VERSION ""

NS_ :

BS_:

BU_: CVC_I MHU TBOX FCAM_I MRR SRR_RL SRR_RR SRR_FL SRR_FR DUMMY_ECU ADCU_I AMP HUD

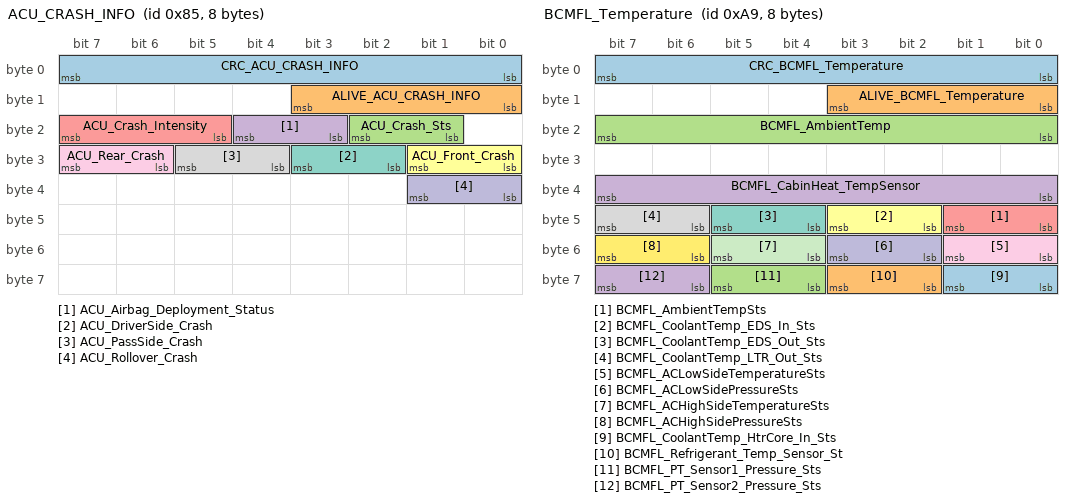
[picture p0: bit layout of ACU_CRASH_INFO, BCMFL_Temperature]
BO_ 133 ACU_CRASH_INFO: 8 CVC_I
 SG_ CRC_ACU_CRASH_INFO : 7|8@0+ (1,0) [0|255] ""  MHU,TBOX,FCAM_I,ADCU_I
 SG_ ALIVE_ACU_CRASH_INFO : 11|4@0+ (1,0) [0|15] ""  MHU,TBOX,FCAM_I,ADCU_I
 SG_ ACU_Crash_Sts : 18|2@0+ (1,0) [0|3] ""  MHU,TBOX,FCAM_I,ADCU_I
 SG_ ACU_Airbag_Deployment_Status : 20|2@0+ (1,0) [0|3] ""  MHU,TBOX,FCAM_I,ADCU_I
 SG_ ACU_Crash_Intensity : 23|3@0+ (1,0) [0|7] ""  MHU,TBOX,FCAM_I,ADCU_I
 SG_ ACU_Front_Crash : 25|2@0+ (1,0) [0|3] ""  MHU,TBOX,FCAM_I,ADCU_I
 SG_ ACU_DriverSide_Crash : 27|2@0+ (1,0) [0|3] ""  MHU,TBOX,FCAM_I,ADCU_I
 SG_ ACU_PassSide_Crash : 29|2@0+ (1,0) [0|3] ""  MHU,TBOX,FCAM_I,ADCU_I
 SG_ ACU_Rear_Crash : 31|2@0+ (1,0) [0|3] ""  MHU,TBOX,FCAM_I,ADCU_I
 SG_ ACU_Rollover_Crash : 33|2@0+ (1,0) [0|3] ""  MHU,TBOX,FCAM_I,ADCU_I

BO_ 169 BCMFL_Temperature: 8 CVC_I
 SG_ CRC_BCMFL_Temperature : 7|8@0+ (1,0) [0|255] ""  MHU,TBOX,FCAM_I,MRR,SRR_RL,SRR_RR,SRR_FL,SRR_FR,ADCU_I
 SG_ ALIVE_BCMFL_Temperature : 11|4@0+ (1,0) [0|15] ""  MHU,TBOX,FCAM_I,MRR,SRR_RL,SRR_RR,SRR_FL,SRR_FR,ADCU_I
 SG_ BCMFL_AmbientTemp : 23|8@0+ (0.5,-40) [-40|85] "Degree C"  MHU,TBOX,FCAM_I,MRR,SRR_RL,SRR_RR,SRR_FL,SRR_FR,ADCU_I
 SG_ BCMFL_CabinHeat_TempSensor : 39|8@0+ (0.5,-40) [-40|85] "Degree C"  MHU,TBOX,FCAM_I,MRR,SRR_RL,SRR_RR,SRR_FL,SRR_FR,ADCU_I
 SG_ BCMFL_AmbientTempSts : 41|2@0+ (1,0) [0|3] ""  MHU,TBOX,FCAM_I,MRR,SRR_RL,SRR_RR,SRR_FL,SRR_FR,ADCU_I
 SG_ BCMFL_CoolantTemp_EDS_In_Sts : 43|2@0+ (1,0) [0|3] ""  MHU,TBOX,FCAM_I,MRR,SRR_RL,SRR_RR,SRR_FL,SRR_FR,ADCU_I
 SG_ BCMFL_CoolantTemp_EDS_Out_Sts : 45|2@0+ (1,0) [0|3] ""  MHU,TBOX,FCAM_I,MRR,SRR_RL,SRR_RR,SRR_FL,SRR_FR,ADCU_I
 SG_ BCMFL_CoolantTemp_LTR_Out_Sts : 47|2@0+ (1,0) [0|3] ""  MHU,TBOX,FCAM_I,MRR,SRR_RL,SRR_RR,SRR_FL,SRR_FR,ADCU_I
 SG_ BCMFL_ACLowSideTemperatureSts : 49|2@0+ (1,0) [0|3] ""  MHU,TBOX,FCAM_I,MRR,SRR_RL,SRR_RR,SRR_FL,SRR_FR,ADCU_I
 SG_ BCMFL_ACLowSidePressureSts : 51|2@0+ (1,0) [0|3] ""  MHU,TBOX,FCAM_I,MRR,SRR_RL,SRR_RR,SRR_FL,SRR_FR,ADCU_I
 SG_ BCMFL_ACHighSideTemperatureSts : 53|2@0+ (1,0) [0|3] ""  MHU,TBOX,FCAM_I,MRR,SRR_RL,SRR_RR,SRR_FL,SRR_FR,ADCU_I
 SG_ BCMFL_ACHighSidePressureSts : 55|2@0+ (1,0) [0|3] ""  MHU,TBOX,FCAM_I,MRR,SRR_RL,SRR_RR,SRR_FL,SRR_FR,ADCU_I
 SG_ BCMFL_CoolantTemp_HtrCore_In_Sts : 57|2@0+ (1,0) [0|3] ""  MHU,TBOX,FCAM_I,MRR,SRR_RL,SRR_RR,SRR_FL,SRR_FR,ADCU_I
 SG_ BCMFL_Refrigerant_Temp_Sensor_St : 59|2@0+ (1,0) [0|3] ""  MHU,TBOX,FCAM_I,MRR,SRR_RL,SRR_RR,SRR_FL,SRR_FR,ADCU_I
 SG_ BCMFL_PT_Sensor1_Pressure_Sts : 61|2@0+ (1,0) [0|3] ""  MHU,TBOX,FCAM_I,MRR,SRR_RL,SRR_RR,SRR_FL,SRR_FR,ADCU_I
 SG_ BCMFL_PT_Sensor2_Pressure_Sts : 63|2@0+ (1,0) [0|3] ""  MHU,TBOX,FCAM_I,MRR,SRR_RL,SRR_RR,SRR_FL,SRR_FR,ADCU_I

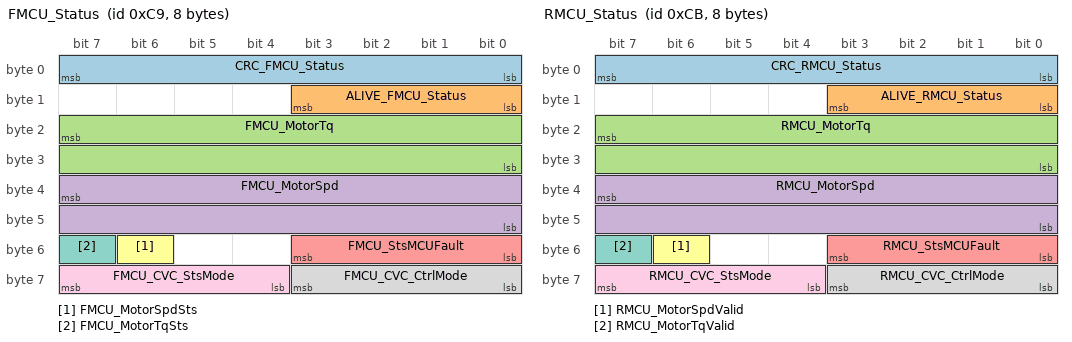
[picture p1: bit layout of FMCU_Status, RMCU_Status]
BO_ 201 FMCU_Status: 8 CVC_I
 SG_ CRC_FMCU_Status : 7|8@0+ (1,0) [0|255] ""  MHU,TBOX,FCAM_I,MRR,SRR_RL,SRR_RR,SRR_FL,SRR_FR,ADCU_I
 SG_ ALIVE_FMCU_Status : 11|4@0+ (1,0) [0|15] ""  MHU,TBOX,FCAM_I,MRR,SRR_RL,SRR_RR,SRR_FL,SRR_FR,ADCU_I
 SG_ FMCU_MotorTq : 23|16@0+ (0.1,-400) [-400|400] "Nm"  MHU,TBOX,FCAM_I,MRR,SRR_RL,SRR_RR,SRR_FL,SRR_FR,ADCU_I
 SG_ FMCU_MotorSpd : 39|16@0+ (1,-20000) [-20000|45531] "rpm"  MHU,TBOX,FCAM_I,MRR,SRR_RL,SRR_RR,SRR_FL,SRR_FR,ADCU_I
 SG_ FMCU_StsMCUFault : 51|4@0+ (1,0) [0|15] ""  MHU,TBOX,FCAM_I,MRR,SRR_RL,SRR_RR,SRR_FL,SRR_FR,ADCU_I
 SG_ FMCU_MotorSpdSts : 54|1@0+ (1,0) [0|1] ""  MHU,TBOX,FCAM_I,MRR,SRR_RL,SRR_RR,SRR_FL,SRR_FR,ADCU_I
 SG_ FMCU_MotorTqSts : 55|1@0+ (1,0) [0|1] ""  MHU,TBOX,FCAM_I,MRR,SRR_RL,SRR_RR,SRR_FL,SRR_FR,ADCU_I
 SG_ FMCU_CVC_CtrlMode : 59|4@0+ (1,0) [0|15] ""  MHU,TBOX,FCAM_I,MRR,SRR_RL,SRR_RR,SRR_FL,SRR_FR,ADCU_I
 SG_ FMCU_CVC_StsMode : 63|4@0+ (1,0) [0|15] ""  MHU,TBOX,FCAM_I,MRR,SRR_RL,SRR_RR,SRR_FL,SRR_FR,ADCU_I

BO_ 203 RMCU_Status: 8 CVC_I
 SG_ CRC_RMCU_Status : 7|8@0+ (1,0) [0|255] ""  MHU,TBOX,FCAM_I,MRR,SRR_RL,SRR_RR,SRR_FL,SRR_FR,ADCU_I
 SG_ ALIVE_RMCU_Status : 11|4@0+ (1,0) [0|15] ""  MHU,TBOX,FCAM_I,MRR,SRR_RL,SRR_RR,SRR_FL,SRR_FR,ADCU_I
 SG_ RMCU_MotorTq : 23|16@0+ (0.1,-400) [-400|400] "Nm"  MHU,TBOX,FCAM_I,MRR,SRR_RL,SRR_RR,SRR_FL,SRR_FR,ADCU_I
 SG_ RMCU_MotorSpd : 39|16@0+ (1,-20000) [-20000|45531] "rpm"  MHU,TBOX,FCAM_I,MRR,SRR_RL,SRR_RR,SRR_FL,SRR_FR,ADCU_I
 SG_ RMCU_StsMCUFault : 51|4@0+ (1,0) [0|15] ""  MHU,TBOX,FCAM_I,MRR,SRR_RL,SRR_RR,SRR_FL,SRR_FR,ADCU_I
 SG_ RMCU_MotorSpdValid : 54|1@0+ (1,0) [0|1] ""  MHU,TBOX,FCAM_I,MRR,SRR_RL,SRR_RR,SRR_FL,SRR_FR,ADCU_I
 SG_ RMCU_MotorTqValid : 55|1@0+ (1,0) [0|1] ""  MHU,TBOX,FCAM_I,MRR,SRR_RL,SRR_RR,SRR_FL,SRR_FR,ADCU_I
 SG_ RMCU_CVC_CtrlMode : 59|4@0+ (1,0) [0|15] ""  MHU,TBOX,FCAM_I,MRR,SRR_RL,SRR_RR,SRR_FL,SRR_FR,ADCU_I
 SG_ RMCU_CVC_StsMode : 63|4@0+ (1,0) [0|15] ""  MHU,TBOX,FCAM_I,MRR,SRR_RL,SRR_RR,SRR_FL,SRR_FR,ADCU_I

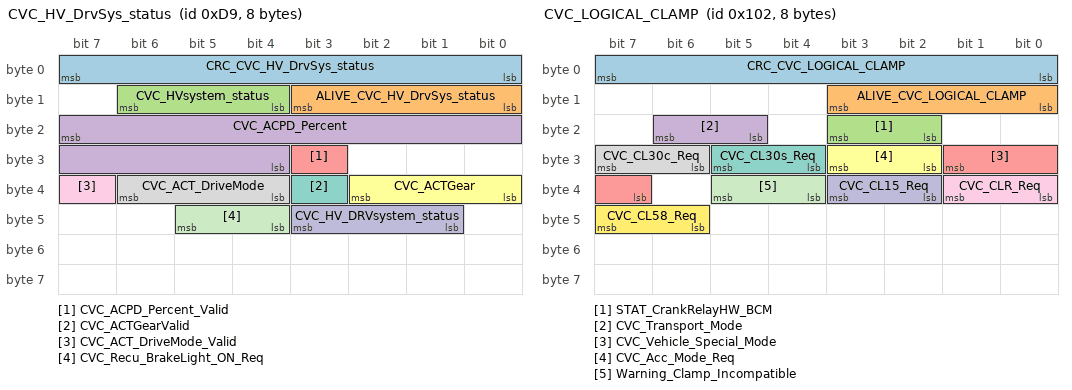
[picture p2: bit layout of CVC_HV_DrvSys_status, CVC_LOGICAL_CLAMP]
BO_ 217 CVC_HV_DrvSys_status: 8 CVC_I
 SG_ CRC_CVC_HV_DrvSys_status : 7|8@0+ (1,0) [0|255] ""  MHU,FCAM_I,SRR_RR
 SG_ ALIVE_CVC_HV_DrvSys_status : 11|4@0+ (1,0) [0|15] ""  MHU,FCAM_I,SRR_RR
 SG_ CVC_HVsystem_status : 14|3@0+ (1,0) [0|7] ""  MHU,FCAM_I,SRR_RR
 SG_ CVC_ACPD_Percent : 23|12@0+ (0.0625,0) [0|100] "%"  MHU,FCAM_I,SRR_RR
 SG_ CVC_ACPD_Percent_Valid : 27|1@0+ (1,0) [0|1] ""  MHU,FCAM_I,SRR_RR
 SG_ CVC_ACTGear : 34|3@0+ (1,0) [0|7] ""  MHU,FCAM_I,SRR_RR
 SG_ CVC_ACTGearValid : 35|1@0+ (1,0) [0|1] ""  MHU,FCAM_I,SRR_RR
 SG_ CVC_ACT_DriveMode : 38|3@0+ (1,0) [0|7] ""  MHU,FCAM_I,SRR_RR
 SG_ CVC_ACT_DriveMode_Valid : 39|1@0+ (1,0) [0|1] ""  MHU,FCAM_I,SRR_RR
 SG_ CVC_HV_DRVsystem_status : 43|3@0+ (1,0) [0|7] ""  MHU,FCAM_I,SRR_RR
 SG_ CVC_Recu_BrakeLight_ON_Req : 45|2@0+ (1,0) [0|3] ""  MHU,FCAM_I,SRR_RR

BO_ 258 CVC_LOGICAL_CLAMP: 8 CVC_I
 SG_ CRC_CVC_LOGICAL_CLAMP : 7|8@0+ (1,0) [0|255] ""  MHU,TBOX,FCAM_I,MRR,SRR_RL,SRR_RR,SRR_FL,SRR_FR,ADCU_I,AMP,HUD
 SG_ ALIVE_CVC_LOGICAL_CLAMP : 11|4@0+ (1,0) [0|15] ""  MHU,TBOX,FCAM_I,MRR,SRR_RL,SRR_RR,SRR_FL,SRR_FR,ADCU_I,AMP,HUD
 SG_ STAT_CrankRelayHW_BCM : 19|2@0+ (1,0) [0|3] ""  MHU
 SG_ CVC_Transport_Mode : 22|2@0+ (1,0) [0|3] ""  MHU,TBOX,FCAM_I,MRR,SRR_RL,SRR_RR,SRR_FL,SRR_FR,ADCU_I,AMP,HUD
 SG_ CVC_Vehicle_Special_Mode : 25|3@0+ (1,0) [0|7] ""  MHU
 SG_ CVC_Acc_Mode_Req : 27|2@0+ (1,0) [0|3] ""  MHU
 SG_ CVC_CL30s_Req : 29|2@0+ (1,0) [0|3] ""  MHU
 SG_ CVC_CL30c_Req : 31|2@0+ (1,0) [0|3] ""  MHU
 SG_ CVC_CLR_Req : 33|2@0+ (1,0) [0|3] ""  MHU
 SG_ CVC_CL15_Req : 35|2@0+ (1,0) [0|3] ""  MHU
 SG_ Warning_Clamp_Incompatible : 37|2@0+ (1,0) [0|3] ""  MHU
 SG_ CVC_CL58_Req : 47|2@0+ (1,0) [0|3] ""  MHU

BO_ 260 BCM_FL_Measured_Data: 12 CVC_I
 SG_ CRC_BCM_FL_Measured_Data : 7|8@0+ (1,0) [0|255] ""  MHU
 SG_ ALIVE_BCM_FL_Measured_Data : 11|4@0+ (1,0) [0|15] ""  MHU
 SG_ SOH_SUL : 23|8@0+ (1,0) [0|100] "%"  MHU
 SG_ SOH_SUL_STATE : 29|2@0+ (1,0) [0|3] ""  MHU
 SG_ SOC_STATE : 31|2@0+ (1,0) [0|3] ""  MHU
 SG_ Resp_Error : 35|1@0+ (1,0) [0|1] ""  MHU
 SG_ FLAG_INCONSTENCY : 36|1@0+ (1,0) [0|1] ""  MHU
 SG_ EBS_error : 37|1@0+ (1,0) [0|1] ""  MHU
 SG_ FLAG_DISCONNECT : 38|1@0+ (1,0) [0|1] ""  MHU
 SG_ IBATT_QUIESCENT : 47|8@0+ (0.00390625,0) [0|0.984375] ""  MHU
 SG_ LV_TargetCurrent : 55|10@0+ (0.25,-128) [-128|127] "A"  MHU
 SG_ LV_TargetVoltage : 61|6@0+ (0.112903,9) [9|16] "V"  MHU
 SG_ LV_ContinuousWakeUpCnt : 71|8@0+ (1,0) [0|255] ""  MHU

BO_ 262 CVC_Body_LIGHT: 8 CVC_I
 SG_ CRC_CVC_Body_LIGHT : 7|8@0+ (1,0) [0|255] ""  MHU,FCAM_I,SRR_RR,ADCU_I
 SG_ ALIVE_CVC_Body_LIGHT : 11|4@0+ (1,0) [0|15] ""  MHU,FCAM_I,SRR_RR,ADCU_I
 SG_ Body_DayRunningLampSts : 13|2@0+ (1,0) [0|3] ""  MHU,ADCU_I
 SG_ Body_ReverseLightSts : 15|2@0+ (1,0) [0|3] ""  MHU,ADCU_I
 SG_ Body_StopLightSts : 17|2@0+ (1,0) [0|3] ""  MHU,FCAM_I,SRR_RR,ADCU_I
 SG_ Body_LicensePlateLightSts : 19|2@0+ (1,0) [0|3] ""  MHU,ADCU_I
 SG_ Body_Fr_Dimming_dome_lampSts : 21|2@0+ (1,0) [0|3] ""  MHU,ADCU_I
 SG_ Body_Rr_Dimming_dome_lampSts : 23|2@0+ (1,0) [0|3] ""  MHU,ADCU_I
 SG_ Body_STAT_InteriorLight : 25|2@0+ (1,0) [0|3] ""  MHU,ADCU_I
 SG_ Body_STAT_LightActivation : 28|3@0+ (1,0) [0|7] ""  MHU,ADCU_I
 SG_ Body_HighBeamSts : 31|2@0+ (1,0) [0|3] ""  MHU,FCAM_I,SRR_RR,ADCU_I
 SG_ Body_STAT_SwitchLightBrightness : 39|7@0+ (1,0) [0|100] "%"  MHU,ADCU_I
 SG_ Body_LowBeamSts : 41|2@0+ (1,0) [0|3] ""  MHU,FCAM_I,SRR_RR,ADCU_I
 SG_ Body_RearFogLmpSts : 43|2@0+ (1,0) [0|3] ""  MHU,ADCU_I
 SG_ Body_FrntFogLmpSts : 45|2@0+ (1,0) [0|3] ""  MHU,ADCU_I
 SG_ Body_PosLmpSts : 47|2@0+ (1,0) [0|3] ""  MHU,ADCU_I
 SG_ Body_HornSts : 53|2@0+ (1,0) [0|3] ""  MHU,ADCU_I
 SG_ Body_TurnIndicatorSts : 55|2@0+ (1,0) [0|3] ""  MHU,FCAM_I,SRR_RR,ADCU_I

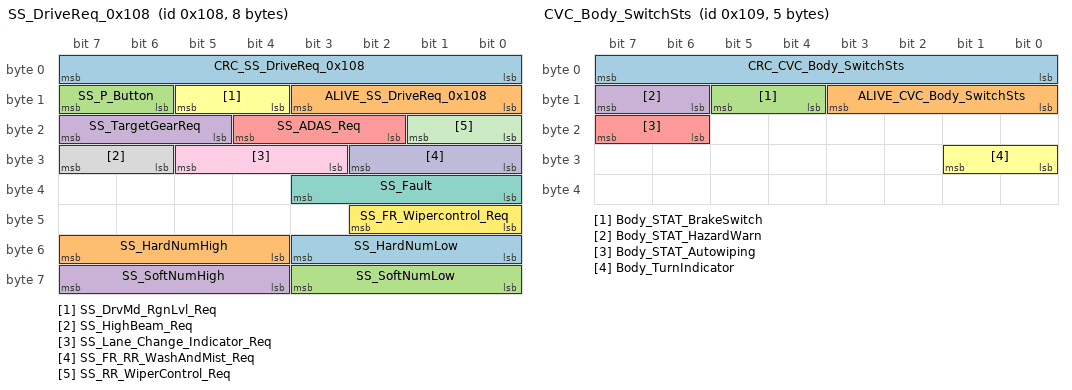
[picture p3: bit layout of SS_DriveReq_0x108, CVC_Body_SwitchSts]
BO_ 264 SS_DriveReq_0x108: 8 CVC_I
 SG_ CRC_SS_DriveReq_0x108 : 7|8@0+ (1,0) [0|255] ""  FCAM_I,ADCU_I
 SG_ ALIVE_SS_DriveReq_0x108 : 11|4@0+ (1,0) [0|15] ""  FCAM_I,ADCU_I
 SG_ SS_P_Button : 15|2@0+ (1,0) [0|3] ""  FCAM_I,ADCU_I
 SG_ SS_TargetGearReq : 23|3@0+ (1,0) [0|7] ""  FCAM_I,ADCU_I
 SG_ SS_ADAS_Req : 20|3@0+ (1,0) [0|7] ""  FCAM_I,ADCU_I
 SG_ SS_DrvMd_RgnLvl_Req : 13|2@0+ (1,0) [0|3] ""  FCAM_I,ADCU_I
 SG_ SS_Fault : 35|4@0+ (1,0) [0|15] ""  FCAM_I,ADCU_I
 SG_ SS_HighBeam_Req : 31|2@0+ (1,0) [0|3] ""  FCAM_I,ADCU_I
 SG_ SS_Lane_Change_Indicator_Req : 29|3@0+ (1,0) [0|7] ""  FCAM_I,ADCU_I
 SG_ SS_FR_RR_WashAndMist_Req : 26|3@0+ (1,0) [0|7] ""  FCAM_I,ADCU_I
 SG_ SS_RR_WiperControl_Req : 17|2@0+ (1,0) [0|3] ""  FCAM_I,ADCU_I
 SG_ SS_FR_Wipercontrol_Req : 42|3@0+ (1,0) [0|7] ""  FCAM_I,ADCU_I
 SG_ SS_HardNumLow : 51|4@0+ (1,0) [0|15] ""  FCAM_I,ADCU_I
 SG_ SS_HardNumHigh : 55|4@0+ (1,0) [0|15] ""  FCAM_I,ADCU_I
 SG_ SS_SoftNumLow : 59|4@0+ (1,0) [0|15] ""  FCAM_I,ADCU_I
 SG_ SS_SoftNumHigh : 63|4@0+ (1,0) [0|15] ""  FCAM_I,ADCU_I

BO_ 265 CVC_Body_SwitchSts: 5 CVC_I
 SG_ CRC_CVC_Body_SwitchSts : 7|8@0+ (1,0) [0|255] ""  MHU,FCAM_I,SRR_RR,ADCU_I
 SG_ ALIVE_CVC_Body_SwitchSts : 11|4@0+ (1,0) [0|15] ""  MHU,FCAM_I,SRR_RR,ADCU_I
 SG_ Body_STAT_BrakeSwitch : 13|2@0+ (1,0) [0|3] ""  MHU,FCAM_I,SRR_RR,ADCU_I
 SG_ Body_STAT_HazardWarn : 15|2@0+ (1,0) [0|3] ""  MHU,FCAM_I,SRR_RR,ADCU_I
 SG_ Body_STAT_Autowiping : 23|2@0+ (1,0) [0|3] ""  MHU,FCAM_I,SRR_RR,ADCU_I
 SG_ Body_TurnIndicator : 25|2@0+ (1,0) [0|3] ""  MHU,FCAM_I,SRR_RR,ADCU_I

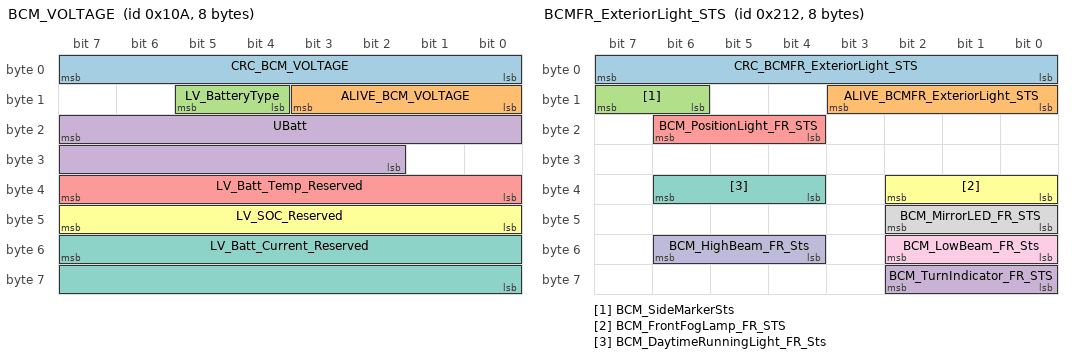
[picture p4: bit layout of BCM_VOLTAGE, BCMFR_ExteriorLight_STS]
BO_ 266 BCM_VOLTAGE: 8 CVC_I
 SG_ CRC_BCM_VOLTAGE : 7|8@0+ (1,0) [0|255] ""  MHU,TBOX,FCAM_I,MRR,SRR_RL,SRR_RR,ADCU_I
 SG_ ALIVE_BCM_VOLTAGE : 11|4@0+ (1,0) [0|15] ""  MHU,TBOX,FCAM_I,MRR,SRR_RL,SRR_RR,ADCU_I
 SG_ LV_BatteryType : 13|2@0+ (1,0) [0|3] ""  MHU,TBOX,FCAM_I,MRR,SRR_RL,SRR_RR,ADCU_I
 SG_ UBatt : 23|14@0+ (0.0009777,3) [3|18] "V"  MHU,TBOX,FCAM_I,MRR,SRR_RL,SRR_RR,ADCU_I
 SG_ LV_Batt_Temp_Reserved : 39|8@0+ (1,-40) [-40|105] "Degree C" Vector__XXX
 SG_ LV_SOC_Reserved : 47|8@0+ (1,0) [0|100] "%"  MHU,TBOX,FCAM_I,MRR,SRR_RL,SRR_RR,ADCU_I
 SG_ LV_Batt_Current_Reserved : 55|16@0+ (0.03125,-1536) [-1536|511.90625] "A"  MHU,TBOX,FCAM_I,MRR,SRR_RL,SRR_RR,ADCU_I

BO_ 180 BCM_WindowsFL_Status: 8 CVC_I
 SG_ CRC_BCM_WindowsFL_Status : 7|8@0+ (1,0) [0|255] ""  ADCU_I
 SG_ ALIVE_BCM_WindowsFL_Status : 11|4@0+ (1,0) [0|15] ""  ADCU_I
 SG_ BCMFL_WindowsFL_AntiPinch_Warn : 19|2@0+ (1,0) [0|3] ""  ADCU_I
 SG_ BCMFL_WindowFL_Learning_Sts : 23|2@0+ (1,0) [0|3] ""  ADCU_I
 SG_ BCMFL_WindowFL_Suppression_Warn : 25|2@0+ (1,0) [0|2] ""  ADCU_I
 SG_ BCMFL_WindowFL_LockActive : 26|1@0+ (1,0) [0|1] ""  ADCU_I
 SG_ BCMFL_WindowFL_ThermalProtect : 29|2@0+ (1,0) [0|2] ""  ADCU_I
 SG_ BCMFL_WindowFL_Error : 27|1@0+ (1,0) [0|1] ""  ADCU_I
 SG_ BCMFL_WindowsRL_AntiPinch_Warn : 33|2@0+ (1,0) [0|3] ""  ADCU_I
 SG_ BCMFL_WindowRL_LockActive : 35|1@0+ (1,0) [0|1] ""  ADCU_I
 SG_ BCMFL_WindowRL_Error : 34|1@0+ (1,0) [0|1] ""  ADCU_I
 SG_ BCMFL_WindowRL_Learning_Sts : 37|2@0+ (1,0) [0|3] ""  ADCU_I
 SG_ BCMFL_WindowRL_Suppression_Warn : 39|2@0+ (1,0) [0|2] ""  ADCU_I
 SG_ BCMFL_WindowRL_ThermalProtect : 41|2@0+ (1,0) [0|2] ""  ADCU_I
 SG_ Window_Position_FL : 51|4@0+ (1,0) [0|15] ""  ADCU_I
 SG_ Window_Position_RL : 55|4@0+ (1,0) [0|15] ""  ADCU_I
 SG_ BCMFL_WindowBtnPress_RL : 44|3@0+ (1,0) [0|4] ""  ADCU_I
 SG_ BCMFL_WindowBtnPress_FL : 47|3@0+ (1,0) [0|4] ""  ADCU_I
 SG_ BCMFL_WindowFL_Malfunction_Warn : 63|2@0+ (1,0) [0|3] ""  ADCU_I
 SG_ BCMFL_WindowRL_Malfunction_Warn : 61|2@0+ (1,0) [0|3] ""  ADCU_I

BO_ 530 BCMFR_ExteriorLight_STS: 8 CVC_I
 SG_ CRC_BCMFR_ExteriorLight_STS : 7|8@0+ (1,0) [0|255] ""  ADCU_I
 SG_ ALIVE_BCMFR_ExteriorLight_STS : 11|4@0+ (1,0) [0|15] ""  ADCU_I
 SG_ BCM_SideMarkerSts : 15|2@0+ (1,0) [0|3] ""  DUMMY_ECU
 SG_ BCM_TurnIndicator_FR_STS : 58|3@0+ (1,0) [0|4] ""  ADCU_I
 SG_ BCM_PositionLight_FR_STS : 22|3@0+ (1,0) [0|4] ""  ADCU_I
 SG_ BCM_FrontFogLamp_FR_STS : 34|3@0+ (1,0) [0|4] ""  DUMMY_ECU
 SG_ BCM_DaytimeRunningLight_FR_Sts : 38|3@0+ (1,0) [0|4] ""  DUMMY_ECU
 SG_ BCM_MirrorLED_FR_STS : 42|3@0+ (1,0) [0|4] ""  ADCU_I
 SG_ BCM_LowBeam_FR_Sts : 50|3@0+ (1,0) [0|4] ""  ADCU_I
 SG_ BCM_HighBeam_FR_Sts : 54|3@0+ (1,0) [0|4] ""  DUMMY_ECU

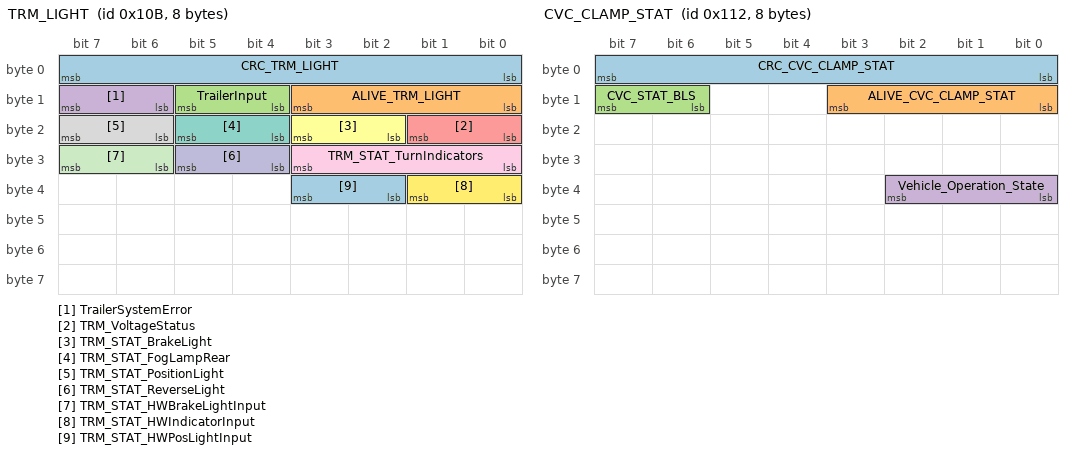
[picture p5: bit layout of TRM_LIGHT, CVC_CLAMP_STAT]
BO_ 267 TRM_LIGHT: 8 CVC_I
 SG_ CRC_TRM_LIGHT : 7|8@0+ (1,0) [0|255] ""  MHU
 SG_ ALIVE_TRM_LIGHT : 11|4@0+ (1,0) [0|15] ""  MHU
 SG_ TrailerInput : 13|2@0+ (1,0) [0|3] ""  MHU
 SG_ TrailerSystemError : 15|2@0+ (1,0) [0|3] ""  MHU
 SG_ TRM_VoltageStatus : 17|2@0+ (1,0) [0|3] ""  MHU
 SG_ TRM_STAT_BrakeLight : 19|2@0+ (1,0) [0|3] ""  MHU
 SG_ TRM_STAT_FogLampRear : 21|2@0+ (1,0) [0|3] ""  MHU
 SG_ TRM_STAT_PositionLight : 23|2@0+ (1,0) [0|3] ""  MHU
 SG_ TRM_STAT_TurnIndicators : 27|4@0+ (1,0) [0|15] ""  MHU
 SG_ TRM_STAT_ReverseLight : 29|2@0+ (1,0) [0|3] ""  MHU
 SG_ TRM_STAT_HWBrakeLightInput : 31|2@0+ (1,0) [0|3] ""  MHU
 SG_ TRM_STAT_HWIndicatorInput : 33|2@0+ (1,0) [0|3] ""  MHU
 SG_ TRM_STAT_HWPosLightInput : 35|2@0+ (1,0) [0|3] ""  MHU

BO_ 273 CVC_WCBS01: 12 CVC_I
 SG_ CRC_CVC_WCBS01 : 7|8@0+ (1,0) [0|255] ""  MHU
 SG_ ALIVE_CVC_WCBS01 : 11|4@0+ (1,0) [0|15] ""  MHU
 SG_ CVC_F_RegenTrqMaxValid : 12|1@0+ (1,0) [0|1] ""  MHU
 SG_ CVC_R_RegenTrqMaxValid : 13|1@0+ (1,0) [0|1] ""  MHU
 SG_ CVC_F_BrkRegenTrqActualValid : 14|1@0+ (1,0) [0|1] ""  MHU
 SG_ CVC_R_BrkRegenTrqActualValid : 15|1@0+ (1,0) [0|1] ""  MHU
 SG_ CVC_F_RegenTrqMax : 23|12@0+ (1,-4000) [-4000|0] "Nm"  MHU
 SG_ CVC_R_RegenTrqMax : 27|12@0+ (1,-4000) [-4000|0] "Nm"  MHU
 SG_ CVC_F_BrkRegenTrqActual : 47|12@0+ (1,-4000) [-4000|0] "Nm"  MHU
 SG_ CVC_R_BrkRegenTrqActual : 51|12@0+ (1,-4000) [-4000|0] "Nm"  MHU
 SG_ CVC_OnePedalModeSts : 69|2@0+ (1,0) [0|3] ""  MHU
 SG_ CVC_OnePedalModeEnable : 71|2@0+ (1,0) [0|3] ""  MHU
 SG_ CVC_TargetBrkTq : 67|12@0+ (1,0) [0|4000] "Nm"  MHU

BO_ 274 CVC_CLAMP_STAT: 8 CVC_I
 SG_ CRC_CVC_CLAMP_STAT : 7|8@0+ (1,0) [0|255] ""  MHU,TBOX,FCAM_I,MRR,SRR_RL,SRR_RR,SRR_FL,SRR_FR,ADCU_I,AMP,HUD
 SG_ ALIVE_CVC_CLAMP_STAT : 11|4@0+ (1,0) [0|15] ""  MHU,TBOX,FCAM_I,MRR,SRR_RL,SRR_RR,SRR_FL,SRR_FR,ADCU_I,AMP,HUD
 SG_ CVC_STAT_BLS : 15|2@0+ (1,0) [0|3] ""  MHU,TBOX,FCAM_I,MRR,SRR_RL,SRR_RR,SRR_FL,SRR_FR,ADCU_I,AMP,HUD
 SG_ Vehicle_Operation_State : 34|3@0+ (1,0) [0|7] ""  MHU,TBOX,FCAM_I,MRR,SRR_RL,SRR_RR,SRR_FL,SRR_FR,ADCU_I,AMP,HUD

BO_ 279 WCBS_Pressure: 16 CVC_I
 SG_ CRC_WCBS_Pressure : 7|8@0+ (1,0) [0|255] ""  SRR_RR,SRR_FR
 SG_ ALIVE_WCBS_Pressure : 11|4@0+ (1,0) [0|15] ""  SRR_RR,SRR_FR
 SG_ WCBS_CircuitPress : 58|15@0+ (0.01,0) [0|327.67] "bar"  SRR_RR,SRR_FR
 SG_ WCBS_CircuitPressValid : 109|1@0+ (1,0) [0|1] ""  SRR_RR,SRR_FR
 SG_ WCBS_EstWhlPress_FL : 23|15@0+ (0.01,0) [0|327.67] "bar"  SRR_RR,SRR_FR
 SG_ WCBS_EstWhlPress_FR : 92|15@0+ (0.01,0) [0|327.67] "bar"  SRR_RR,SRR_FR
 SG_ WCBS_EstWhlPress_RL : 75|15@0+ (0.01,0) [0|327.67] "bar"  SRR_RR,SRR_FR
 SG_ WCBS_EstWhlPress_RR : 24|15@0+ (0.01,0) [0|327.67] "bar"  SRR_RR,SRR_FR
 SG_ WCBS_EstWhlPressValid : 108|1@0+ (1,0) [0|1] ""  SRR_RR,SRR_FR
 SG_ WCBS_MainCylinderPress : 41|15@0+ (0.01,0) [0|250] "bar"  SRR_RR,SRR_FR
 SG_ WCBS_MainCylinderPressValid : 107|1@0+ (1,0) [0|1] ""  SRR_RR,SRR_FR

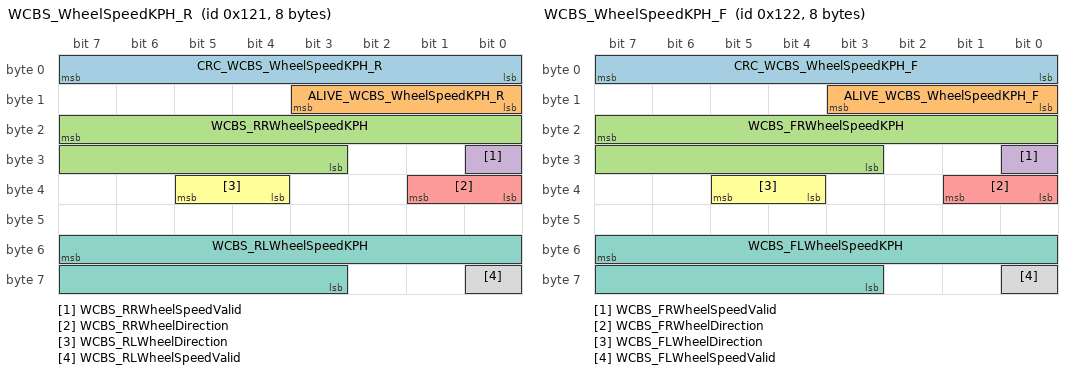
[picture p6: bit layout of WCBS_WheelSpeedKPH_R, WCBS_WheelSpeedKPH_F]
BO_ 289 WCBS_WheelSpeedKPH_R: 8 CVC_I
 SG_ CRC_WCBS_WheelSpeedKPH_R : 7|8@0+ (1,0) [0|255] ""  MHU,SRR_RR,SRR_FR
 SG_ ALIVE_WCBS_WheelSpeedKPH_R : 11|4@0+ (1,0) [0|15] ""  MHU,SRR_RR,SRR_FR
 SG_ WCBS_RRWheelSpeedKPH : 23|13@0+ (0.05625,0) [0|460.6875] "Km/h"  MHU,SRR_RR,SRR_FR
 SG_ WCBS_RRWheelSpeedValid : 24|1@0+ (1,0) [0|1] ""  MHU,SRR_RR,SRR_FR
 SG_ WCBS_RRWheelDirection : 33|2@0+ (1,0) [0|3] ""  MHU,SRR_RR,SRR_FR
 SG_ WCBS_RLWheelDirection : 37|2@0+ (1,0) [0|3] ""  MHU,SRR_RR,SRR_FR
 SG_ WCBS_RLWheelSpeedKPH : 55|13@0+ (0.05625,0) [0|460.6875] "Km/h"  MHU,SRR_RR,SRR_FR
 SG_ WCBS_RLWheelSpeedValid : 56|1@0+ (1,0) [0|1] ""  MHU,SRR_RR,SRR_FR

BO_ 290 WCBS_WheelSpeedKPH_F: 8 CVC_I
 SG_ CRC_WCBS_WheelSpeedKPH_F : 7|8@0+ (1,0) [0|255] ""  MHU,SRR_RR,SRR_FR
 SG_ ALIVE_WCBS_WheelSpeedKPH_F : 11|4@0+ (1,0) [0|15] ""  MHU,SRR_RR,SRR_FR
 SG_ WCBS_FRWheelSpeedKPH : 23|13@0+ (0.05625,0) [0|460.6875] "Km/h"  MHU,SRR_RR,SRR_FR
 SG_ WCBS_FRWheelSpeedValid : 24|1@0+ (1,0) [0|1] ""  MHU,SRR_RR,SRR_FR
 SG_ WCBS_FRWheelDirection : 33|2@0+ (1,0) [0|3] ""  MHU,SRR_RR,SRR_FR
 SG_ WCBS_FLWheelDirection : 37|2@0+ (1,0) [0|3] ""  MHU,SRR_RR,SRR_FR
 SG_ WCBS_FLWheelSpeedKPH : 55|13@0+ (0.05625,0) [0|460.6875] "Km/h"  MHU,SRR_RR,SRR_FR
 SG_ WCBS_FLWheelSpeedValid : 56|1@0+ (1,0) [0|1] ""  MHU,SRR_RR,SRR_FR

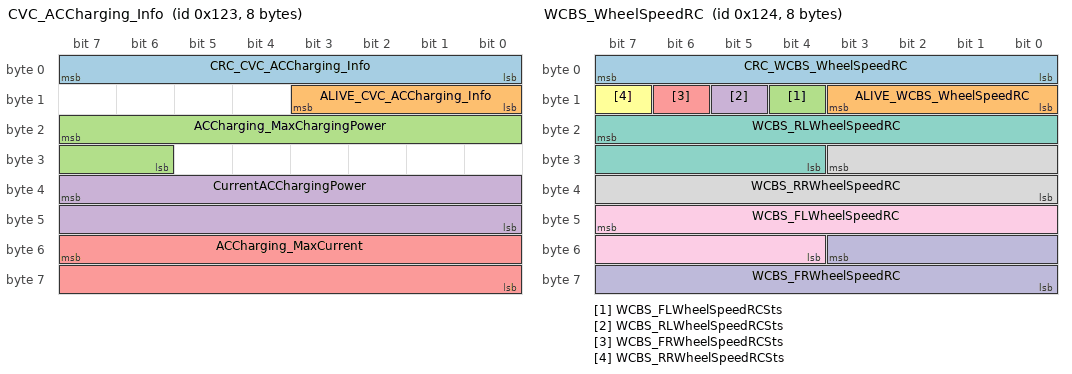
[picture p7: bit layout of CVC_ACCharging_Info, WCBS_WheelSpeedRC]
BO_ 291 CVC_ACCharging_Info: 8 CVC_I
 SG_ CRC_CVC_ACCharging_Info : 7|8@0+ (1,0) [0|255] ""  MHU
 SG_ ALIVE_CVC_ACCharging_Info : 11|4@0+ (1,0) [0|15] ""  MHU
 SG_ ACCharging_MaxChargingPower : 23|10@0+ (0.1,0) [0|102.2] "kW"  MHU
 SG_ CurrentACChargingPower : 39|16@0+ (0.1,0) [0|6553.5] "kW"  MHU
 SG_ ACCharging_MaxCurrent : 55|16@0+ (0.1,0) [0|3276.7] "A"  MHU

BO_ 292 WCBS_WheelSpeedRC: 8 CVC_I
 SG_ CRC_WCBS_WheelSpeedRC : 7|8@0+ (1,0) [0|255] ""  MHU,SRR_RR,SRR_FR
 SG_ ALIVE_WCBS_WheelSpeedRC : 11|4@0+ (1,0) [0|15] ""  MHU,SRR_RR,SRR_FR
 SG_ WCBS_FLWheelSpeedRCSts : 12|1@0+ (1,0) [0|1] ""  MHU,SRR_RR,SRR_FR
 SG_ WCBS_RLWheelSpeedRCSts : 13|1@0+ (1,0) [0|1] ""  MHU,SRR_RR,SRR_FR
 SG_ WCBS_FRWheelSpeedRCSts : 14|1@0+ (1,0) [0|1] ""  MHU,SRR_RR,SRR_FR
 SG_ WCBS_RRWheelSpeedRCSts : 15|1@0+ (1,0) [0|1] ""  MHU,SRR_RR,SRR_FR
 SG_ WCBS_RLWheelSpeedRC : 23|12@0+ (1,0) [0|4095] ""  MHU,SRR_RR,SRR_FR
 SG_ WCBS_RRWheelSpeedRC : 27|12@0+ (1,0) [0|4095] ""  MHU,SRR_RR,SRR_FR
 SG_ WCBS_FLWheelSpeedRC : 47|12@0+ (1,0) [0|4095] ""  MHU,SRR_RR,SRR_FR
 SG_ WCBS_FRWheelSpeedRC : 51|12@0+ (1,0) [0|4095] ""  MHU,SRR_RR,SRR_FR

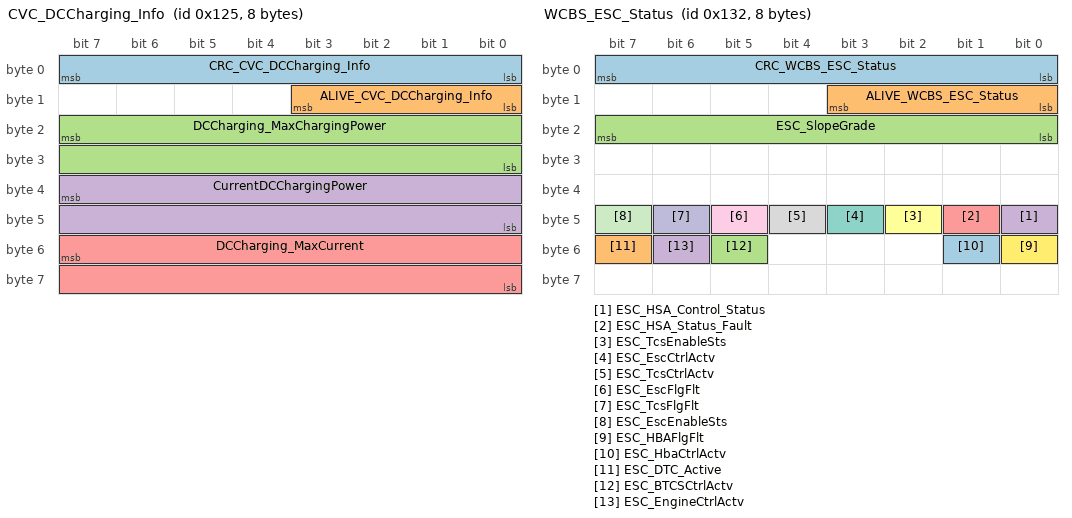
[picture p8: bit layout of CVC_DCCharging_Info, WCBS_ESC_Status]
BO_ 293 CVC_DCCharging_Info: 8 CVC_I
 SG_ CRC_CVC_DCCharging_Info : 7|8@0+ (1,0) [0|255] ""  MHU
 SG_ ALIVE_CVC_DCCharging_Info : 11|4@0+ (1,0) [0|15] ""  MHU
 SG_ DCCharging_MaxChargingPower : 23|16@0+ (0.1,0) [0|6553.5] "kW"  MHU
 SG_ CurrentDCChargingPower : 39|16@0+ (0.1,0) [0|6553.5] "kW"  MHU
 SG_ DCCharging_MaxCurrent : 55|16@0+ (0.1,0) [0|3276.7] "A"  MHU

BO_ 306 WCBS_ESC_Status: 8 CVC_I
 SG_ CRC_WCBS_ESC_Status : 7|8@0+ (1,0) [0|255] ""  MHU,SRR_RR
 SG_ ALIVE_WCBS_ESC_Status : 11|4@0+ (1,0) [0|15] ""  MHU,SRR_RR
 SG_ ESC_SlopeGrade : 23|8@0+ (1,-30) [-30|30] "%"  MHU,SRR_RR
 SG_ ESC_HSA_Control_Status : 40|1@0+ (1,0) [0|1] ""  MHU,SRR_RR
 SG_ ESC_HSA_Status_Fault : 41|1@0+ (1,0) [0|1] ""  MHU,SRR_RR
 SG_ ESC_TcsEnableSts : 42|1@0+ (1,0) [0|1] ""  MHU,SRR_RR
 SG_ ESC_EscCtrlActv : 43|1@0+ (1,0) [0|1] ""  MHU,SRR_RR
 SG_ ESC_TcsCtrlActv : 44|1@0+ (1,0) [0|1] ""  MHU,SRR_RR
 SG_ ESC_EscFlgFlt : 45|1@0+ (1,0) [0|1] ""  MHU,SRR_RR
 SG_ ESC_TcsFlgFlt : 46|1@0+ (1,0) [0|1] ""  MHU,SRR_RR
 SG_ ESC_EscEnableSts : 47|1@0+ (1,0) [0|1] ""  MHU,SRR_RR
 SG_ ESC_HBAFlgFlt : 48|1@0+ (1,0) [0|1] ""  MHU,SRR_RR
 SG_ ESC_HbaCtrlActv : 49|1@0+ (1,0) [0|1] ""  MHU,SRR_RR
 SG_ ESC_DTC_Active : 55|1@0+ (1,0) [0|1] ""  MHU,SRR_RR
 SG_ ESC_BTCSCtrlActv : 53|1@0+ (1,0) [0|1] ""  MHU,SRR_RR
 SG_ ESC_EngineCtrlActv : 54|1@0+ (1,0) [0|1] ""  MHU,SRR_RR

BO_ 311 EAS_CDC_WorkState: 8 CVC_I
 SG_ CRC_EAS_CDC_WorkState : 7|8@0+ (1,0) [0|255] ""  MHU
 SG_ ALIVE_EAS_CDC_WorkState : 11|4@0+ (1,0) [0|15] ""  MHU
 SG_ EAS_StiffStsFL : 12|1@0+ (1,0) [0|1] ""  MHU
 SG_ EAS_StiffStsFR : 13|1@0+ (1,0) [0|1] ""  MHU
 SG_ EAS_StiffStsRL : 14|1@0+ (1,0) [0|1] ""  MHU
 SG_ EAS_StiffStsRR : 15|1@0+ (1,0) [0|1] ""  MHU
 SG_ EAS_WorkSts : 17|2@0+ (1,0) [0|3] ""  MHU
 SG_ CDC_WorkSts : 19|2@0+ (1,0) [0|3] ""  MHU
 SG_ EAS_CDC_SystemWorkMode : 21|2@0+ (1,0) [0|3] ""  MHU
 SG_ EAS_SuspensionMode : 23|2@0+ (1,0) [0|3] ""  MHU
 SG_ EAS_EasyAccessSts : 25|2@0+ (1,0) [0|3] ""  MHU
 SG_ CDC_DamperMode : 27|2@0+ (1,0) [0|3] ""  MHU
 SG_ EAS_ValveValue_FL : 30|3@0+ (1,0) [0|7] ""  MHU
 SG_ EAS_ValveValue_FR : 34|3@0+ (1,0) [0|7] ""  MHU
 SG_ EAS_ValveValue_RL : 38|3@0+ (1,0) [0|7] ""  MHU
 SG_ EAS_ValveValue_RR : 42|3@0+ (1,0) [0|7] ""  MHU
 SG_ EAS_EnableSts : 31|1@0+ (1,0) [0|1] ""  MHU
 SG_ CDC_ValveValue_FL : 35|1@0+ (1,0) [0|1] ""  MHU
 SG_ CDC_ValveValue_FR : 39|1@0+ (1,0) [0|1] ""  MHU
 SG_ CDC_ValveValue_RL : 43|1@0+ (1,0) [0|1] ""  MHU
 SG_ CDC_ValveValue_RR : 44|1@0+ (1,0) [0|1] ""  MHU
 SG_ EAS_MntnSts : 45|1@0+ (1,0) [0|1] ""  MHU
 SG_ EAS_EasyLoadingSetFb : 47|2@0+ (1,0) [0|3] ""  MHU
 SG_ EAS_LiftModFb : 49|2@0+ (1,0) [0|3] ""  MHU
 SG_ EAS_VehicleUpDownState : 51|2@0+ (1,0) [0|3] ""  MHU
 SG_ EAS_Overheat_Warning : 52|1@0+ (1,0) [0|1] ""  MHU
 SG_ EAS_VehiclePositionState : 55|3@0+ (1,0) [0|7] ""  MHU
 SG_ EAS_VehicleTargetPositionState : 58|3@0+ (1,0) [0|7] ""  MHU

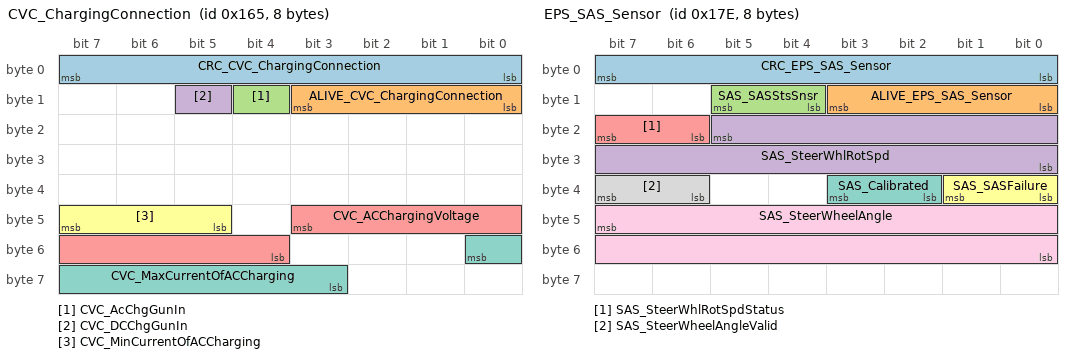
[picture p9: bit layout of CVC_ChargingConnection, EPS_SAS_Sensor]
BO_ 357 CVC_ChargingConnection: 8 CVC_I
 SG_ CRC_CVC_ChargingConnection : 7|8@0+ (1,0) [0|255] ""  MHU
 SG_ ALIVE_CVC_ChargingConnection : 11|4@0+ (1,0) [0|15] ""  MHU
 SG_ CVC_AcChgGunIn : 12|1@0+ (1,0) [0|1] ""  MHU
 SG_ CVC_DCChgGunIn : 13|1@0+ (1,0) [0|1] ""  MHU
 SG_ CVC_ACChargingVoltage : 43|8@0+ (1,0) [0|255] "V"  MHU
 SG_ CVC_MinCurrentOfACCharging : 47|3@0+ (1,0) [0|7] "A"  MHU
 SG_ CVC_MaxCurrentOfACCharging : 48|6@0+ (1,0) [0|63] "A"  MHU

BO_ 372 BMS_CurMeas: 24 CVC_I
 SG_ CRC_BMS_CurMeas : 7|8@0+ (1,0) [0|255] ""  MHU
 SG_ ALIVE_BMS_CurMeas : 11|4@0+ (1,0) [0|15] ""  MHU
 SG_ BMS_StartOfMeasument_STS : 15|1@0+ (1,0) [0|1] ""  MHU
 SG_ BMS_PackCur_MEAS : 23|16@0+ (0.1,-3276.8) [-3276.8|3276.7] "A"  MHU
 SG_ BMS_HVPackVol_MEAS : 39|16@0+ (0.1,0) [0|800] "V"  MHU
 SG_ BMS_HVLinkVol_MEAS : 55|16@0+ (0.1,0) [0|800] "V"  MHU
 SG_ BMS_HVBusVol_MEAS : 71|16@0+ (0.1,0) [0|800] "V"  MHU
 SG_ BMS_HVFuseVol_MEAS : 87|16@0+ (0.1,0) [0|800] "V"  MHU
 SG_ BMS_MainNegRelay_Volt : 103|8@0+ (0.1,0) [0|5] "V"  MHU
 SG_ BMS_CellNumMinCellVol : 111|8@0+ (1,0) [0|255] ""  MHU
 SG_ BMS_CellNumMaxCellVol : 119|8@0+ (1,0) [0|255] ""  MHU
 SG_ BMS_MinCellVol : 127|13@0+ (0.001,0) [0|6] "V"  MHU
 SG_ BMS_MaxCellVol : 143|13@0+ (0.001,0) [0|6] "V"  MHU
 SG_ BMS_MaxMinDiffCellVol : 159|13@0+ (0.001,0) [0|2] "V"  MHU
 SG_ BMS_CVC_Insulation_Mon_Sts : 162|1@0+ (1,0) [0|1] ""  MHU
 SG_ BMS_PackInsuRes : 175|16@0+ (1,0) [0|60000] "kOhm"  MHU

BO_ 382 EPS_SAS_Sensor: 8 CVC_I
 SG_ CRC_EPS_SAS_Sensor : 7|8@0+ (1,0) [0|255] ""  MHU,SRR_RR
 SG_ ALIVE_EPS_SAS_Sensor : 11|4@0+ (1,0) [0|15] ""  MHU,SRR_RR
 SG_ SAS_SASStsSnsr : 13|2@0+ (1,0) [0|1] ""  MHU,SRR_RR
 SG_ SAS_SteerWhlRotSpd : 21|14@0+ (0.125,-1024) [-1024|1023.88] "degree/s"  MHU,SRR_RR
 SG_ SAS_SteerWhlRotSpdStatus : 23|2@0+ (1,0) [0|1] ""  MHU,SRR_RR
 SG_ SAS_SASFailure : 33|2@0+ (1,0) [0|1] ""  MHU,SRR_RR
 SG_ SAS_Calibrated : 35|2@0+ (1,0) [0|1] ""  MHU,SRR_RR
 SG_ SAS_SteerWheelAngleValid : 39|2@0+ (1,0) [0|1] ""  MHU,SRR_RR
 SG_ SAS_SteerWheelAngle : 47|16@0+ (0.0238,-780) [-780|779.7] "deg"  MHU,SRR_RR

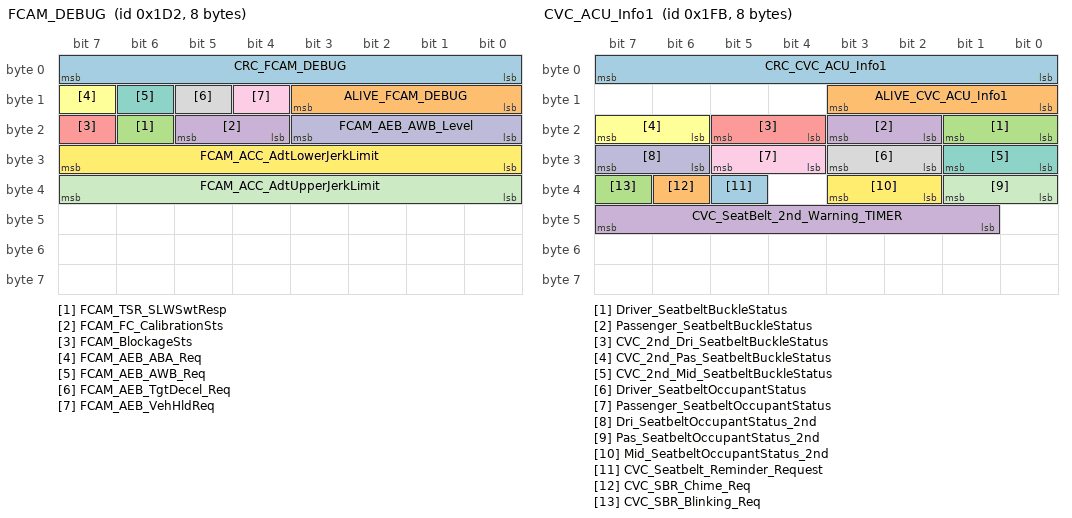
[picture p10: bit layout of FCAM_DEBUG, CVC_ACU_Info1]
BO_ 466 FCAM_DEBUG: 8 CVC_I
 SG_ CRC_FCAM_DEBUG : 7|8@0+ (1,0) [0|255] ""  MHU
 SG_ ALIVE_FCAM_DEBUG : 11|4@0+ (1,0) [0|15] ""  MHU
 SG_ FCAM_TSR_SLWSwtResp : 22|1@0+ (1,0) [0|1] ""  MHU
 SG_ FCAM_FC_CalibrationSts : 21|2@0+ (1,0) [0|3] ""  MHU
 SG_ FCAM_BlockageSts : 23|1@0+ (1,0) [0|1] ""  MHU
 SG_ FCAM_AEB_ABA_Req : 15|1@0+ (1,0) [0|1] ""  MHU
 SG_ FCAM_AEB_AWB_Req : 14|1@0+ (1,0) [0|1] ""  MHU
 SG_ FCAM_AEB_TgtDecel_Req : 13|1@0+ (1,0) [0|1] ""  MHU
 SG_ FCAM_AEB_VehHldReq : 12|1@0+ (1,0) [0|1] ""  MHU
 SG_ FCAM_AEB_AWB_Level : 19|4@0+ (1,0) [0|15] ""  MHU
 SG_ FCAM_ACC_AdtUpperJerkLimit : 39|8@0+ (0.1,-12.7) [-12.7|12.7] "m/s3"  MHU
 SG_ FCAM_ACC_AdtLowerJerkLimit : 31|8@0+ (0.1,-12.7) [-12.7|12.7] "m/s3"  MHU

BO_ 507 CVC_ACU_Info1: 8 CVC_I
 SG_ CRC_CVC_ACU_Info1 : 7|8@0+ (1,0) [0|255] ""  MHU
 SG_ ALIVE_CVC_ACU_Info1 : 11|4@0+ (1,0) [0|15] ""  MHU
 SG_ Driver_SeatbeltBuckleStatus : 17|2@0+ (1,0) [0|3] ""  MHU
 SG_ Passenger_SeatbeltBuckleStatus : 19|2@0+ (1,0) [0|3] ""  MHU
 SG_ CVC_2nd_Dri_SeatbeltBuckleStatus : 21|2@0+ (1,0) [0|3] ""  MHU
 SG_ CVC_2nd_Pas_SeatbeltBuckleStatus : 23|2@0+ (1,0) [0|3] ""  MHU
 SG_ CVC_2nd_Mid_SeatbeltBuckleStatus : 25|2@0+ (1,0) [0|3] ""  MHU
 SG_ Driver_SeatbeltOccupantStatus : 27|2@0+ (1,0) [0|3] ""  MHU
 SG_ Passenger_SeatbeltOccupantStatus : 29|2@0+ (1,0) [0|3] ""  MHU
 SG_ Dri_SeatbeltOccupantStatus_2nd : 31|2@0+ (1,0) [0|3] ""  MHU
 SG_ Pas_SeatbeltOccupantStatus_2nd : 33|2@0+ (1,0) [0|3] ""  MHU
 SG_ Mid_SeatbeltOccupantStatus_2nd : 35|2@0+ (1,0) [0|3] ""  MHU
 SG_ CVC_Seatbelt_Reminder_Request : 37|1@0+ (1,0) [0|1] ""  MHU
 SG_ CVC_SBR_Chime_Req : 38|1@0+ (1,0) [0|1] ""  MHU
 SG_ CVC_SBR_Blinking_Req : 39|1@0+ (1,0) [0|1] ""  MHU
 SG_ CVC_SeatBelt_2nd_Warning_TIMER : 47|7@0+ (1,0) [0|127] ""  MHU

BO_ 522 ETG_STATUS: 8 CVC_I
 SG_ ETG_Lift_Gate_Status : 43|4@0+ (1,0) [0|15] ""  MHU
 SG_ ETG_Power_Latch_Status : 5|3@0+ (1,0) [0|7] ""  MHU
 SG_ ETG_Latch_Segment : 7|2@0+ (1,0) [0|3] ""  MHU
 SG_ ETG_Opening_Percentage : 15|8@0+ (1,0) [0|100] "%"  MHU
 SG_ ETG_DSW_Status : 16|1@0+ (1,0) [0|1] ""  MHU
 SG_ ETG_GSW_Status : 17|1@0+ (1,0) [0|1] ""  MHU
 SG_ ETG_LTS_Status : 18|1@0+ (1,0) [0|1] ""  MHU
 SG_ ETG_RTS_Status : 19|1@0+ (1,0) [0|1] ""  MHU
 SG_ ETG_HAL_Status : 20|1@0+ (1,0) [0|1] ""  MHU
 SG_ ETG_FUL_Status : 21|1@0+ (1,0) [0|1] ""  MHU
 SG_ ETG_AJR_Status : 22|1@0+ (1,0) [0|1] ""  MHU
 SG_ ETG_NTL_Status : 23|1@0+ (1,0) [0|1] ""  MHU
 SG_ ETG_ERR_Voltage : 25|2@0+ (1,0) [0|3] ""  MHU
 SG_ ETG_ERR_Left_Motor : 27|2@0+ (1,0) [0|3] ""  MHU
 SG_ ETG_ERR_Right_Motor : 29|2@0+ (1,0) [0|3] ""  MHU
 SG_ ETG_ERR_Latch : 31|2@0+ (1,0) [0|3] ""  MHU
 SG_ ETG_ERR_Hall : 33|2@0+ (1,0) [0|3] ""  MHU
 SG_ ETG_Lift_Motor_Stall : 34|1@0+ (1,0) [0|1] ""  MHU
 SG_ ETG_Lift_Motor_AntiPinch : 35|1@0+ (1,0) [0|1] ""  MHU
 SG_ ETG_Lift_Motor_Thermal : 36|1@0+ (1,0) [0|1] ""  MHU
 SG_ ETG_Power_Latch_Thermal : 37|1@0+ (1,0) [0|1] ""  MHU
 SG_ ETG_Abuse_Protection : 38|1@0+ (1,0) [0|1] ""  MHU

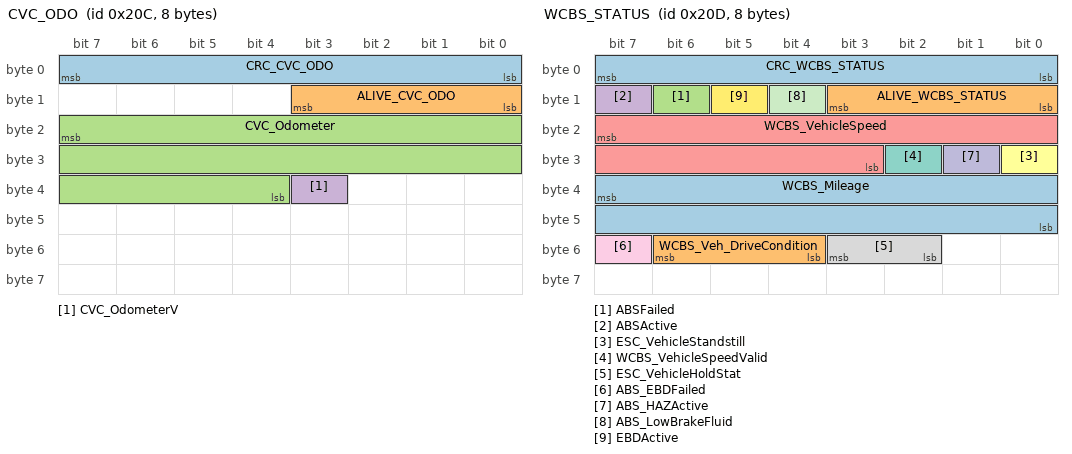
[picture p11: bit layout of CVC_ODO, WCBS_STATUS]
BO_ 524 CVC_ODO: 8 CVC_I
 SG_ CRC_CVC_ODO : 7|8@0+ (1,0) [0|255] ""  MHU,TBOX,FCAM_I,MRR,SRR_RL,SRR_RR,ADCU_I
 SG_ ALIVE_CVC_ODO : 11|4@0+ (1,0) [0|15] ""  MHU,TBOX,FCAM_I,MRR,SRR_RL,SRR_RR,ADCU_I
 SG_ CVC_Odometer : 23|20@0+ (1,0) [0|999999] "km"  MHU,TBOX,FCAM_I,MRR,SRR_RL,SRR_RR,ADCU_I
 SG_ CVC_OdometerV : 35|1@0+ (1,0) [0|1] ""  MHU,TBOX,FCAM_I,MRR,SRR_RL,SRR_RR,ADCU_I

BO_ 525 WCBS_STATUS: 8 CVC_I
 SG_ CRC_WCBS_STATUS : 7|8@0+ (1,0) [0|255] ""  MHU,TBOX,FCAM_I,MRR,SRR_RL,SRR_RR,SRR_FL,SRR_FR
 SG_ ALIVE_WCBS_STATUS : 11|4@0+ (1,0) [0|15] ""  MHU,TBOX,FCAM_I,MRR,SRR_RL,SRR_RR,SRR_FL,SRR_FR
 SG_ ABSFailed : 14|1@0+ (1,0) [0|1] ""  MHU,TBOX,FCAM_I,MRR,SRR_RL,SRR_RR,SRR_FL,SRR_FR
 SG_ ABSActive : 15|1@0+ (1,0) [0|1] ""  MHU,TBOX,FCAM_I,MRR,SRR_RL,SRR_RR,SRR_FL,SRR_FR
 SG_ WCBS_VehicleSpeed : 23|13@0+ (0.05625,0) [0|300] "km/h"  MHU,TBOX,FCAM_I,MRR,SRR_RL,SRR_RR,SRR_FL,SRR_FR
 SG_ ESC_VehicleStandstill : 24|1@0+ (1,0) [0|1] ""  MHU,TBOX,FCAM_I,MRR,SRR_RL,SRR_RR,SRR_FL,SRR_FR
 SG_ WCBS_VehicleSpeedValid : 26|1@0+ (1,0) [0|1] ""  MHU,TBOX,FCAM_I,MRR,SRR_RL,SRR_RR,SRR_FL,SRR_FR
 SG_ ESC_VehicleHoldStat : 51|2@0+ (1,0) [0|3] ""  MHU,TBOX,FCAM_I,MRR,SRR_RL,SRR_RR,SRR_FL,SRR_FR
 SG_ ABS_EBDFailed : 55|1@0+ (1,0) [0|1] ""  MHU,TBOX,FCAM_I,MRR,SRR_RL,SRR_RR,SRR_FL,SRR_FR
 SG_ ABS_HAZActive : 25|1@0+ (1,0) [0|1] ""  MHU,TBOX,FCAM_I,MRR,SRR_RL,SRR_RR,SRR_FL,SRR_FR
 SG_ ABS_LowBrakeFluid : 12|1@0+ (1,0) [0|1] ""  MHU,TBOX,FCAM_I,MRR,SRR_RL,SRR_RR,SRR_FL,SRR_FR
 SG_ EBDActive : 13|1@0+ (1,0) [0|1] ""  MHU,TBOX,FCAM_I,MRR,SRR_RL,SRR_RR,SRR_FL,SRR_FR
 SG_ WCBS_Mileage : 39|16@0+ (1,0) [0|65535] "cm"  MHU,TBOX,FCAM_I,MRR,SRR_RL,SRR_RR,SRR_FL,SRR_FR
 SG_ WCBS_Veh_DriveCondition : 54|3@0+ (1,0) [0|7] ""  MHU,TBOX,FCAM_I,MRR,SRR_RL,SRR_RR,SRR_FL,SRR_FR

BO_ 533 BMS_Sts: 16 CVC_I
 SG_ CRC_BMS_Sts : 7|8@0+ (1,0) [0|255] ""  MHU,FCAM_I,ADCU_I
 SG_ ALIVE_BMS_Sts : 11|4@0+ (1,0) [0|15] ""  MHU,FCAM_I,ADCU_I
 SG_ BMS_BatBalance_ERR : 12|1@0+ (1,0) [0|1] ""  MHU,FCAM_I,ADCU_I
 SG_ BMS_Balance_STS : 13|1@0+ (1,0) [0|1] ""  MHU,FCAM_I,ADCU_I
 SG_ BMS_IGN_Sts : 14|1@0+ (1,0) [0|1] ""  MHU,FCAM_I,ADCU_I
 SG_ BMS_HWCrash_Sts : 15|1@0+ (1,0) [0|1] ""  MHU,FCAM_I,ADCU_I
 SG_ BMS_HVIL_STS : 17|2@0+ (1,0) [0|3] ""  MHU,FCAM_I,ADCU_I
 SG_ BMS_HVOnOff_STS : 19|2@0+ (1,0) [0|3] ""  MHU,FCAM_I,ADCU_I
 SG_ BMS_ERR_LEV : 23|4@0+ (1,0) [0|7] ""  MHU,FCAM_I,ADCU_I
 SG_ BMS_SocActual_EST : 25|10@0+ (0.1,0) [0|100] "%"  MHU,FCAM_I,ADCU_I
 SG_ BMS_Sys_STS : 29|4@0+ (1,0) [0|15] ""  MHU,FCAM_I,ADCU_I
 SG_ BMS_ISU_Status : 31|2@0+ (1,0) [0|3] ""  MHU,FCAM_I,ADCU_I
 SG_ BMS_SOH : 47|8@0+ (0.5,0) [0|100] "%"  MHU,FCAM_I,ADCU_I
 SG_ BMS_SOE : 55|8@0+ (0.5,0) [0|100] "%"  MHU,FCAM_I,ADCU_I
 SG_ BMS_HV_Sts : 63|8@0+ (1,0) [0|255] ""  MHU,FCAM_I,ADCU_I
 SG_ BMS_Display_SOC : 71|10@0+ (0.1,0) [0|100] "%"  MHU,FCAM_I,ADCU_I
 SG_ BMS_SOCE : 87|14@0+ (0.01,0) [0|100] "%"  MHU,FCAM_I,ADCU_I

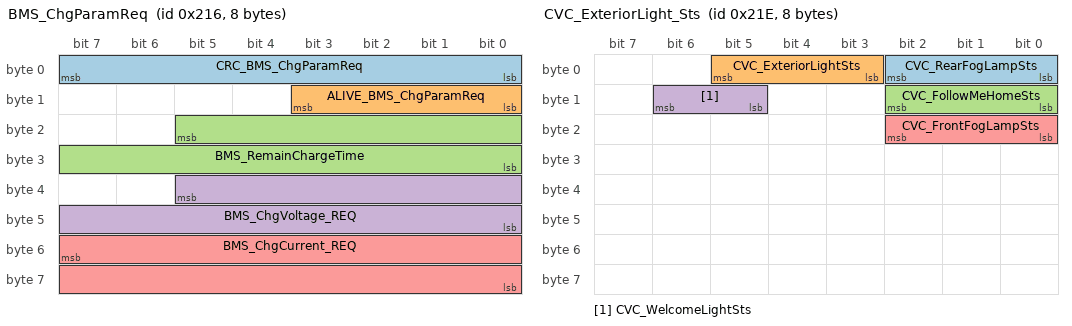
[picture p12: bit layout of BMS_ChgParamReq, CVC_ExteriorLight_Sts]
BO_ 534 BMS_ChgParamReq: 8 CVC_I
 SG_ CRC_BMS_ChgParamReq : 7|8@0+ (1,0) [0|255] ""  MHU
 SG_ ALIVE_BMS_ChgParamReq : 11|4@0+ (1,0) [0|15] ""  MHU
 SG_ BMS_RemainChargeTime : 21|14@0+ (1,0) [0|16383] "min"  MHU
 SG_ BMS_ChgVoltage_REQ : 37|14@0+ (0.1,0) [0|800] "V"  MHU
 SG_ BMS_ChgCurrent_REQ : 55|16@0+ (0.1,0) [0|1500] "A"  MHU

BO_ 542 CVC_ExteriorLight_Sts: 8 CVC_I
 SG_ CVC_RearFogLampSts : 2|3@0+ (1,0) [0|4] ""  MHU,FCAM_I
 SG_ CVC_ExteriorLightSts : 5|3@0+ (1,0) [0|4] ""  MHU,FCAM_I
 SG_ CVC_FollowMeHomeSts : 10|3@0+ (1,0) [0|5] ""  MHU,FCAM_I
 SG_ CVC_WelcomeLightSts : 14|2@0+ (1,0) [0|3] ""  MHU,FCAM_I
 SG_ CVC_FrontFogLampSts : 18|3@0+ (1,0) [0|4] ""  MHU,FCAM_I,ADCU_I

BO_ 560 WCBS_VAFS: 12 CVC_I
 SG_ CRC_WCBS_VAFS : 7|8@0+ (1,0) [0|255] ""  MHU,SRR_RR
 SG_ ALIVE_WCBS_VAFS : 11|4@0+ (1,0) [0|15] ""  MHU,SRR_RR
 SG_ WCBS_BrkLampReq : 18|1@0+ (1,0) [0|1] ""  MHU,SRR_RR
 SG_ EPB_SysWrnIndReq : 23|2@0+ (1,0) [0|2] ""  MHU,SRR_RR
 SG_ EPB_SysStatIndReq : 25|2@0+ (1,0) [0|3] ""  MHU,SRR_RR
 SG_ EPB_SysDspMsgReq : 30|3@0+ (1,0) [0|7] ""  MHU,SRR_RR
 SG_ EPB_Sts : 51|3@0+ (1,0) [0|7] ""  MHU,SRR_RR
 SG_ WCBS_TSMActive : 52|1@0+ (1,0) [0|1] ""  MHU,SRR_RR
 SG_ EPB_CDPActive : 15|4@0+ (1,0) [0|15] ""  MHU,SRR_RR
 SG_ EPB_Swch_Mafnc : 31|1@0+ (1,0) [0|1] ""  MHU,SRR_RR
 SG_ WCBS_Avh_Available : 39|1@0+ (1,0) [0|1] ""  MHU,SRR_RR
 SG_ WCBS_AVH_DispMsg : 38|3@0+ (1,0) [0|7] ""  MHU,SRR_RR
 SG_ WCBS_AVH_Status : 35|4@0+ (1,0) [0|15] ""  MHU,SRR_RR
 SG_ WCBS_EPB_Fault : 26|1@0+ (1,0) [0|1] ""  MHU,SRR_RR
 SG_ WCBS_ROMActive : 27|1@0+ (1,0) [0|1] ""  MHU,SRR_RR
 SG_ WCBS_ROMFailure : 17|1@0+ (1,0) [0|1] ""  MHU,SRR_RR
 SG_ WCBS_TrailerDetected : 16|1@0+ (1,0) [0|1] ""  MHU,SRR_RR
 SG_ WCBS_TSMFailure : 53|1@0+ (1,0) [0|1] ""  MHU,SRR_RR
 SG_ WCBS_OnePedalAvailable : 48|1@0+ (1,0) [0|1] ""  SRR_RR
 SG_ WCBS_BrkFricTqTotAtWhls : 63|14@0+ (1,0) [0|15000] "Nm"  SRR_RR
 SG_ WCBS_HDCCtrlsts : 21|2@0+ (1,0) [0|3] ""  MHU,SRR_RR
 SG_ WCBS_HDC_displayWarnMsg : 55|2@0+ (1,0) [0|3] ""  MHU,SRR_RR
 SG_ WCBS_VehicleSteerSts : 47|2@0+ (1,0) [0|3] ""  MHU,SRR_RR
 SG_ WCBS_HDC_available : 19|1@0+ (1,0) [0|1] ""  MHU,SRR_RR
 SG_ WCBS_HDC_SwitchSts : 42|1@0+ (1,0) [0|1] ""  MHU,SRR_RR
 SG_ WCBS_DTCFailure : 41|1@0+ (1,0) [0|1] ""  MHU,SRR_RR
 SG_ WCBS_TowMode_Feedback : 65|2@0+ (1,0) [0|3] ""  MHU,SRR_RR
 SG_ WCBS_SCM_available : 73|1@0+ (1,0) [0|1] ""  MHU,SRR_RR
 SG_ WCBS_OnePedal_Active : 74|1@0+ (1,0) [0|1] ""  MHU,SRR_RR
 SG_ WCBS_OnePedal_hold_state : 75|1@0+ (1,0) [0|1] ""  MHU,SRR_RR
 SG_ WCBS_CDPFailSts : 76|1@0+ (1,0) [0|1] ""  MHU,SRR_RR
 SG_ WCBS_CBC_Active : 78|1@0+ (1,0) [0|1] ""  MHU,SRR_RR
 SG_ WCBS_CBC_Available : 79|1@0+ (1,0) [0|1] ""  MHU,SRR_RR
 SG_ WCBS_SLS_Active : 80|1@0+ (1,0) [0|1] ""  MHU,SRR_RR
 SG_ WCBS_SLS_Available : 81|1@0+ (1,0) [0|1] ""  MHU,SRR_RR
 SG_ WCBS_TVBB_Active : 82|1@0+ (1,0) [0|1] ""  MHU,SRR_RR
 SG_ WCBS_TVBB_Available : 83|1@0+ (1,0) [0|1] ""  MHU,SRR_RR
 SG_ WCBS_BDW_Active : 84|1@0+ (1,0) [0|1] ""  MHU,SRR_RR
 SG_ WCBS_BDW_Available : 85|1@0+ (1,0) [0|1] ""  MHU,SRR_RR
 SG_ WCBS_SCMActive : 77|1@0+ (1,0) [0|1] ""  MHU,SRR_RR

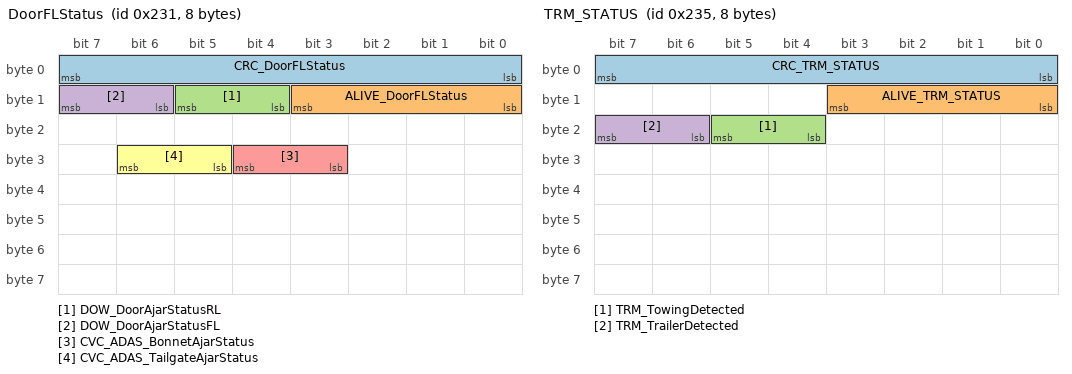
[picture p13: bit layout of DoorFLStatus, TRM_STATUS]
BO_ 561 DoorFLStatus: 8 CVC_I
 SG_ CRC_DoorFLStatus : 7|8@0+ (1,0) [0|255] ""  MHU,SRR_RL,SRR_RR,SRR_FL,SRR_FR
 SG_ ALIVE_DoorFLStatus : 11|4@0+ (1,0) [0|15] ""  MHU,SRR_RL,SRR_RR,SRR_FL,SRR_FR
 SG_ DOW_DoorAjarStatusRL : 13|2@0+ (1,0) [0|3] ""  MHU,SRR_RL,SRR_RR,SRR_FL,SRR_FR
 SG_ DOW_DoorAjarStatusFL : 15|2@0+ (1,0) [0|3] ""  MHU,SRR_RL,SRR_RR,SRR_FL,SRR_FR
 SG_ CVC_ADAS_BonnetAjarStatus : 28|2@0+ (1,0) [0|3] ""  MHU,SRR_RL,SRR_RR
 SG_ CVC_ADAS_TailgateAjarStatus : 30|2@0+ (1,0) [0|3] ""  MHU,SRR_RL,SRR_RR

BO_ 565 TRM_STATUS: 8 CVC_I
 SG_ CRC_TRM_STATUS : 7|8@0+ (1,0) [0|255] ""  MHU,FCAM_I,SRR_RR,ADCU_I
 SG_ ALIVE_TRM_STATUS : 11|4@0+ (1,0) [0|15] ""  MHU,FCAM_I,SRR_RR,ADCU_I
 SG_ TRM_TowingDetected : 21|2@0+ (1,0) [0|3] ""  MHU,FCAM_I,SRR_RR,ADCU_I
 SG_ TRM_TrailerDetected : 23|2@0+ (1,0) [0|3] ""  MHU,FCAM_I,SRR_RR,ADCU_I

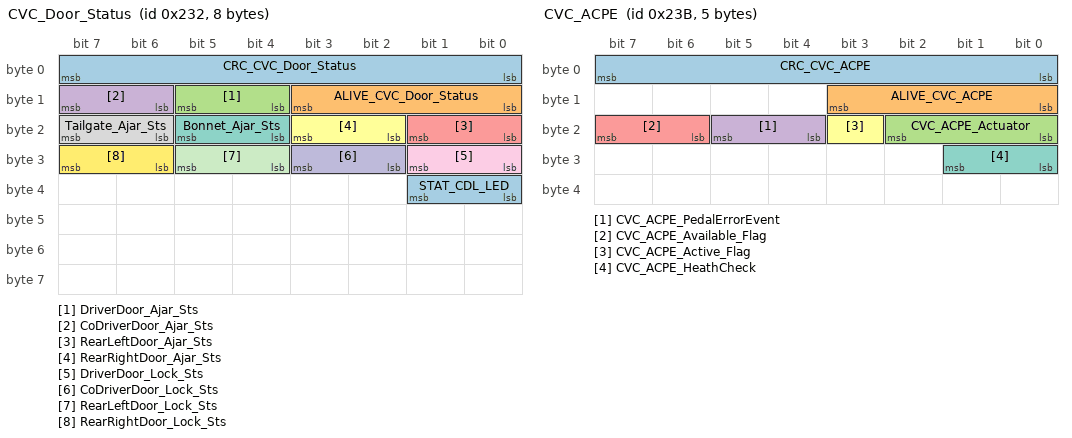
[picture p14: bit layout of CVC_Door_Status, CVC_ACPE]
BO_ 562 CVC_Door_Status: 8 CVC_I
 SG_ CRC_CVC_Door_Status : 7|8@0+ (1,0) [0|255] ""  MHU,FCAM_I,SRR_RL,SRR_RR,SRR_FL,SRR_FR,ADCU_I
 SG_ ALIVE_CVC_Door_Status : 11|4@0+ (1,0) [0|15] ""  MHU,FCAM_I,SRR_RL,SRR_RR,SRR_FL,SRR_FR,ADCU_I
 SG_ DriverDoor_Ajar_Sts : 13|2@0+ (1,0) [0|3] ""  MHU,FCAM_I,SRR_RL,SRR_RR,SRR_FL,SRR_FR,ADCU_I
 SG_ CoDriverDoor_Ajar_Sts : 15|2@0+ (1,0) [0|255] ""  MHU,FCAM_I,SRR_RL,SRR_RR,SRR_FL,SRR_FR,ADCU_I
 SG_ RearLeftDoor_Ajar_Sts : 17|2@0+ (1,0) [0|255] ""  MHU,FCAM_I,SRR_RL,SRR_RR,SRR_FL,SRR_FR,ADCU_I
 SG_ RearRightDoor_Ajar_Sts : 19|2@0+ (1,0) [0|255] ""  MHU,FCAM_I,SRR_RL,SRR_RR,SRR_FL,SRR_FR,ADCU_I
 SG_ Bonnet_Ajar_Sts : 21|2@0+ (1,0) [0|255] ""  MHU,FCAM_I,SRR_RL,SRR_RR,SRR_FL,SRR_FR,ADCU_I
 SG_ Tailgate_Ajar_Sts : 23|2@0+ (1,0) [0|255] ""  MHU,FCAM_I,SRR_RL,SRR_RR,SRR_FL,SRR_FR,ADCU_I
 SG_ DriverDoor_Lock_Sts : 25|2@0+ (1,0) [0|255] ""  MHU,FCAM_I,SRR_RL,SRR_RR,SRR_FL,SRR_FR,ADCU_I
 SG_ CoDriverDoor_Lock_Sts : 27|2@0+ (1,0) [0|255] ""  MHU,FCAM_I,SRR_RL,SRR_RR,SRR_FL,SRR_FR,ADCU_I
 SG_ RearLeftDoor_Lock_Sts : 29|2@0+ (1,0) [0|255] ""  MHU,FCAM_I,SRR_RL,SRR_RR,SRR_FL,SRR_FR,ADCU_I
 SG_ RearRightDoor_Lock_Sts : 31|2@0+ (1,0) [0|255] ""  MHU,FCAM_I,SRR_RL,SRR_RR,SRR_FL,SRR_FR,ADCU_I
 SG_ STAT_CDL_LED : 33|2@0+ (1,0) [0|3] ""  MHU,FCAM_I,SRR_RL,SRR_RR,SRR_FL,SRR_FR,ADCU_I

BO_ 571 CVC_ACPE: 5 CVC_I
 SG_ CRC_CVC_ACPE : 7|8@0+ (1,0) [0|255] ""  MHU,ADCU_I
 SG_ ALIVE_CVC_ACPE : 11|4@0+ (1,0) [0|15] ""  MHU,ADCU_I
 SG_ CVC_ACPE_Actuator : 18|3@0+ (1,0) [0|7] ""  MHU,ADCU_I
 SG_ CVC_ACPE_PedalErrorEvent : 21|2@0+ (1,0) [0|3] ""  MHU,ADCU_I
 SG_ CVC_ACPE_Available_Flag : 23|2@0+ (1,0) [0|3] ""  MHU,ADCU_I
 SG_ CVC_ACPE_Active_Flag : 19|1@0+ (1,0) [0|1] ""  MHU,ADCU_I
 SG_ CVC_ACPE_HeathCheck : 25|2@0+ (1,0) [0|3] ""  MHU,ADCU_I

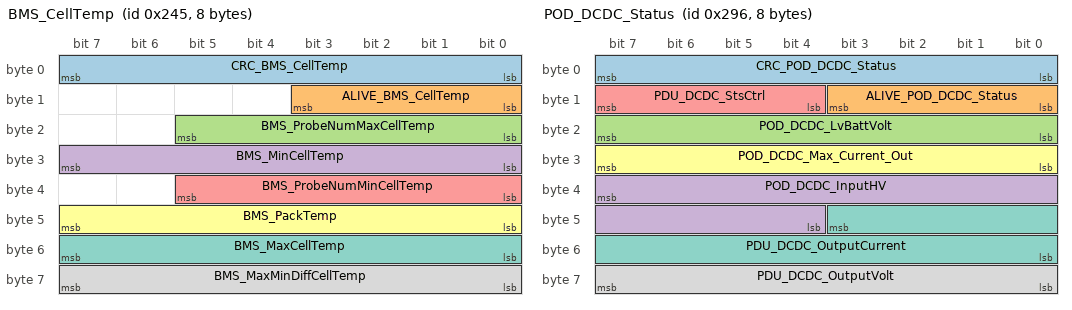
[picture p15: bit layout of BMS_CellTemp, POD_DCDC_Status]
BO_ 581 BMS_CellTemp: 8 CVC_I
 SG_ CRC_BMS_CellTemp : 7|8@0+ (1,0) [0|255] ""  MHU
 SG_ ALIVE_BMS_CellTemp : 11|4@0+ (1,0) [0|15] ""  MHU
 SG_ BMS_ProbeNumMaxCellTemp : 21|6@0+ (1,0) [0|63] ""  MHU
 SG_ BMS_MinCellTemp : 31|8@0+ (1,-40) [-40|215] "Degree C"  MHU
 SG_ BMS_ProbeNumMinCellTemp : 37|6@0+ (1,0) [0|63] ""  MHU
 SG_ BMS_PackTemp : 47|8@0+ (1,-40) [-40|215] "Degree C"  MHU
 SG_ BMS_MaxCellTemp : 55|8@0+ (1,-40) [-40|215] "Degree C"  MHU
 SG_ BMS_MaxMinDiffCellTemp : 63|8@0+ (1,-40) [-40|215] "Degree C"  MHU

BO_ 584 DoorFRStatus: 8 CVC_I
 SG_ CRC_DoorFRStatus : 7|8@0+ (1,0) [0|255] ""  MHU,SRR_RL,SRR_RR,SRR_FL,SRR_FR
 SG_ ALIVE_DoorFRStatus : 11|4@0+ (1,0) [0|15] ""  MHU,SRR_RL,SRR_RR,SRR_FL,SRR_FR
 SG_ DOW_DoorAjarStatusRR : 13|2@0+ (1,0) [0|3] ""  MHU,SRR_RL,SRR_RR,SRR_FL,SRR_FR
 SG_ DOW_DoorAjarStatusFR : 15|2@0+ (1,0) [0|3] ""  MHU,SRR_RL,SRR_RR,SRR_FL,SRR_FR

BO_ 624 WCBS_Info: 12 CVC_I
 SG_ CRC_WCBS_Info : 7|8@0+ (1,0) [0|255] ""  MHU,SRR_RR,SRR_FR
 SG_ ALIVE_WCBS_Info : 11|4@0+ (1,0) [0|15] ""  MHU,SRR_RR,SRR_FR
 SG_ WCBS_Fault_Status : 14|3@0+ (1,0) [0|7] ""  MHU,SRR_RR,SRR_FR
 SG_ WCBS_IBS_Sys_Fault_Sts : 15|1@0+ (1,0) [0|1] ""  MHU,SRR_RR,SRR_FR
 SG_ WCBS_BrkPedalPct : 23|8@0+ (0.4,0) [0|100] "%"  MHU,SRR_RR,SRR_FR
 SG_ WCBS_BrkPedalTravel : 31|10@0+ (0.2,0) [0|150] "mm"  MHU,SRR_RR,SRR_FR
 SG_ WCBS_BrkPedalValid : 69|1@0+ (1,0) [0|1] ""  MHU,SRR_RR,SRR_FR
 SG_ WCBS_DiagMode : 68|1@0+ (1,0) [0|1] ""  MHU,SRR_RR,SRR_FR
 SG_ WCBS_RollerBenchMode : 67|1@0+ (1,0) [0|1] ""  MHU,SRR_RR,SRR_FR
 SG_ WCBSActive : 66|1@0+ (1,0) [0|1] ""  MHU,SRR_RR,SRR_FR
 SG_ WCBS_EOL_NotDone : 64|1@0+ (1,0) [0|1] ""  MHU,SRR_RR,SRR_FR
 SG_ STAT_DSC : 79|2@0+ (1,0) [0|3] ""  MHU,SRR_RR,SRR_FR
 SG_ WCBS_BLAFlt : 65|1@0+ (1,0) [0|1] ""  MHU,SRR_RR,SRR_FR
 SG_ FBW_WarningSts : 77|2@0+ (1,0) [0|3] ""  MHU,SRR_RR,SRR_FR
 SG_ Brake_Disc_Temp_FL : 35|7@0+ (10,40) [-40|800] "" Vector__XXX
 SG_ Brake_Disc_Temp_FR : 44|7@0+ (10,40) [-40|800] "" Vector__XXX
 SG_ Brake_Disc_Temp_RL : 53|7@0+ (10,40) [-40|800] "" Vector__XXX
 SG_ Brake_Disc_Temp_RR : 62|7@0+ (10,40) [-40|800] "" Vector__XXX
 SG_ WCBS_BrakesystemFailSts : 75|3@0+ (1,0) [0|7] "" Vector__XXX

BO_ 662 POD_DCDC_Status: 8 CVC_I
 SG_ CRC_POD_DCDC_Status : 7|8@0+ (1,0) [0|255] ""  MHU
 SG_ ALIVE_POD_DCDC_Status : 11|4@0+ (1,0) [0|15] ""  MHU
 SG_ POD_DCDC_LvBattVolt : 23|8@0+ (0.1,0) [0|15] ""  MHU
 SG_ POD_DCDC_InputHV : 39|12@0+ (0.5,0) [0|1000] "V"  MHU
 SG_ PDU_DCDC_StsCtrl : 15|4@0+ (1,0) [0|15] ""  MHU
 SG_ POD_DCDC_Max_Current_Out : 31|8@0+ (1,0) [0|250] ""  MHU
 SG_ PDU_DCDC_OutputCurrent : 43|12@0+ (0.1,-100) [-100|300] "A"  MHU
 SG_ PDU_DCDC_OutputVolt : 63|8@0+ (0.125,0) [0|31.875] "V"  MHU

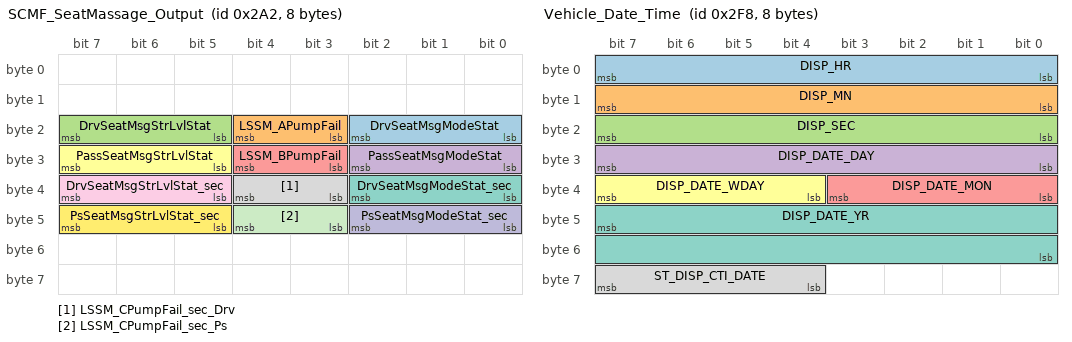
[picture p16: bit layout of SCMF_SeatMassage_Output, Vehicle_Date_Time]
BO_ 674 SCMF_SeatMassage_Output: 8 CVC_I
 SG_ DrvSeatMsgModeStat : 18|3@0+ (1,0) [0|7] ""  MHU
 SG_ LSSM_APumpFail : 20|2@0+ (1,0) [0|3] ""  MHU
 SG_ DrvSeatMsgStrLvlStat : 23|3@0+ (1,0) [0|7] ""  MHU
 SG_ PassSeatMsgModeStat : 26|3@0+ (1,0) [0|7] ""  MHU
 SG_ LSSM_BPumpFail : 28|2@0+ (1,0) [0|3] ""  MHU
 SG_ PassSeatMsgStrLvlStat : 31|3@0+ (1,0) [0|7] ""  MHU
 SG_ DrvSeatMsgModeStat_sec : 34|3@0+ (1,0) [0|7] ""  MHU
 SG_ LSSM_CPumpFail_sec_Drv : 36|2@0+ (1,0) [0|3] ""  MHU
 SG_ DrvSeatMsgStrLvlStat_sec : 39|3@0+ (1,0) [0|7] ""  MHU
 SG_ PsSeatMsgModeStat_sec : 42|3@0+ (1,0) [0|7] ""  MHU
 SG_ LSSM_CPumpFail_sec_Ps : 44|2@0+ (1,0) [0|3] ""  MHU
 SG_ PsSeatMsgStrLvlStat_sec : 47|3@0+ (1,0) [0|7] ""  MHU

BO_ 746 CVC_Temp: 16 CVC_I
 SG_ InteriorTemperature : 7|12@0+ (0.1,-80) [-80|329] "C"  MHU,TBOX,FCAM_I,MRR,SRR_RL,SRR_RR,ADCU_I
 SG_ CVC_SW_Versions : 23|16@0+ (1,0) [0|255] ""  DUMMY_ECU
 SG_ CVC_Fan_Sts : 33|2@0+ (1,0) [0|3] ""  DUMMY_ECU
 SG_ CVC_DCChgPosTemp : 47|8@0+ (1,-40) [-40|210] "Degree C"  DUMMY_ECU
 SG_ CVC_DCChgNegTemp : 55|8@0+ (1,-40) [-40|210] "Degree C"  DUMMY_ECU
 SG_ CVC_ACChgLTerminalTemp : 63|8@0+ (1,-40) [-40|210] "Degree C"  DUMMY_ECU
 SG_ CVC_ACChgNTerminalTemp_Reserve : 71|8@0+ (1,-40) [-40|210] "Degree C"  DUMMY_ECU
 SG_ CVC_EdrivePump_Sts : 77|2@0+ (1,0) [0|3] ""  DUMMY_ECU
 SG_ CVC_BatPump_Sts : 79|2@0+ (1,0) [0|3] ""  DUMMY_ECU
 SG_ CVC_ActiveHeatingPower : 87|16@0+ (0.2,0) [0|8000] "kW"  DUMMY_ECU

BO_ 760 Vehicle_Date_Time: 8 CVC_I
 SG_ DISP_HR : 7|8@0+ (1,0) [0|23] "h"  MHU,TBOX,FCAM_I,MRR,SRR_RL,SRR_RR,SRR_FL,SRR_FR,ADCU_I,AMP
 SG_ DISP_MN : 15|8@0+ (1,0) [0|59] "min"  MHU,TBOX,FCAM_I,MRR,SRR_RL,SRR_RR,SRR_FL,SRR_FR,ADCU_I,AMP
 SG_ DISP_SEC : 23|8@0+ (1,0) [0|59] "s"  MHU,TBOX,FCAM_I,MRR,SRR_RL,SRR_RR,SRR_FL,SRR_FR,ADCU_I,AMP
 SG_ DISP_DATE_DAY : 31|8@0+ (1,0) [1|31] "Day"  MHU,TBOX,FCAM_I,MRR,SRR_RL,SRR_RR,SRR_FL,SRR_FR,ADCU_I,AMP
 SG_ DISP_DATE_MON : 35|4@0+ (1,0) [1|12] "Month"  MHU,TBOX,FCAM_I,MRR,SRR_RL,SRR_RR,SRR_FL,SRR_FR,ADCU_I,AMP
 SG_ DISP_DATE_WDAY : 39|4@0+ (1,0) [0|15] ""  MHU,TBOX,FCAM_I,MRR,SRR_RL,SRR_RR,SRR_FL,SRR_FR,ADCU_I,AMP
 SG_ DISP_DATE_YR : 47|16@0+ (1,0) [1|65534] "Year"  MHU,TBOX,FCAM_I,MRR,SRR_RL,SRR_RR,SRR_FL,SRR_FR,ADCU_I,AMP
 SG_ ST_DISP_CTI_DATE : 63|4@0+ (1,0) [0|15] ""  MHU,TBOX,FCAM_I,MRR,SRR_RL,SRR_RR,SRR_FL,SRR_FR,ADCU_I,AMP

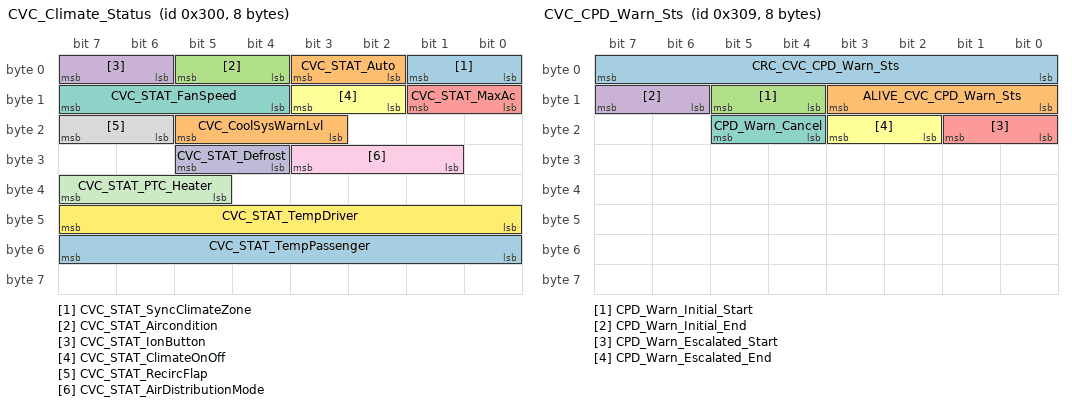
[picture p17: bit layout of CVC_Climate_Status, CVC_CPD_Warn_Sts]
BO_ 768 CVC_Climate_Status: 8 CVC_I
 SG_ CVC_STAT_SyncClimateZone : 1|2@0+ (1,0) [0|3] ""  MHU
 SG_ CVC_STAT_Auto : 3|2@0+ (1,0) [0|3] ""  MHU
 SG_ CVC_STAT_Aircondition : 5|2@0+ (1,0) [0|3] ""  MHU
 SG_ CVC_STAT_IonButton : 7|2@0+ (1,0) [0|3] ""  MHU
 SG_ CVC_STAT_MaxAc : 9|2@0+ (1,0) [0|3] ""  MHU
 SG_ CVC_STAT_ClimateOnOff : 11|2@0+ (1,0) [0|3] ""  MHU
 SG_ CVC_STAT_FanSpeed : 15|4@0+ (1,0) [0|15] ""  MHU
 SG_ CVC_STAT_RecircFlap : 23|2@0+ (1,0) [0|3] ""  MHU
 SG_ CVC_STAT_AirDistributionMode : 27|3@0+ (1,0) [0|7] ""  MHU
 SG_ CVC_STAT_Defrost : 29|2@0+ (1,0) [0|3] ""  MHU
 SG_ CVC_STAT_PTC_Heater : 39|3@0+ (1,0) [0|7] ""  MHU
 SG_ CVC_STAT_TempDriver : 47|8@0+ (0.5,0) [16|32] "Degree C"  MHU
 SG_ CVC_STAT_TempPassenger : 55|8@0+ (0.5,0) [16|32] "Degree C"  MHU
 SG_ CVC_CoolSysWarnLvl : 21|3@0+ (1,0) [0|7] ""  MHU

BO_ 777 CVC_CPD_Warn_Sts: 8 CVC_I
 SG_ CRC_CVC_CPD_Warn_Sts : 7|8@0+ (1,0) [0|255] ""  MHU
 SG_ ALIVE_CVC_CPD_Warn_Sts : 11|4@0+ (1,0) [0|15] ""  MHU
 SG_ CPD_Warn_Initial_Start : 13|2@0+ (1,0) [0|3] ""  MHU
 SG_ CPD_Warn_Initial_End : 15|2@0+ (1,0) [0|3] ""  MHU
 SG_ CPD_Warn_Escalated_Start : 17|2@0+ (1,0) [0|3] ""  MHU
 SG_ CPD_Warn_Escalated_End : 19|2@0+ (1,0) [0|3] ""  MHU
 SG_ CPD_Warn_Cancel : 21|2@0+ (1,0) [0|3] ""  MHU

BO_ 778 CVC_DKCU_CommandRequest: 24 CVC_I
 SG_ CRC_CVC_DKCU_CommandRequest : 7|8@0+ (1,0) [0|255] ""  MHU,TBOX
 SG_ ALIVE_CVC_DKCU_CommandRequest : 11|4@0+ (1,0) [0|15] ""  MHU,TBOX
 SG_ CVC_DKCU_PhoneLocationReq : 18|3@0+ (1,0) [0|7] ""  MHU,TBOX
 SG_ Secure_ResetCnt_0x30A : 135|16@0+ (1,0) [0|65535] ""  DUMMY_ECU
 SG_ Secure_MsgCnt_0x30A : 151|16@0+ (1,0) [0|65535] ""  DUMMY_ECU
 SG_ Secure_MAC_0x30A : 167|32@0+ (1,0) [0|4294967295] ""  DUMMY_ECU

BO_ 779 CVC_DK_TempIntervention_Start: 8 CVC_I
 SG_ CVC_DKCU_Temp_Intervention_Fdbk : 7|8@0+ (1,0) [0|255] ""  MHU,TBOX
 SG_ CVC_DKCU_Remote_Phone_Interventi : 15|8@0+ (1,0) [0|255] ""  MHU,TBOX

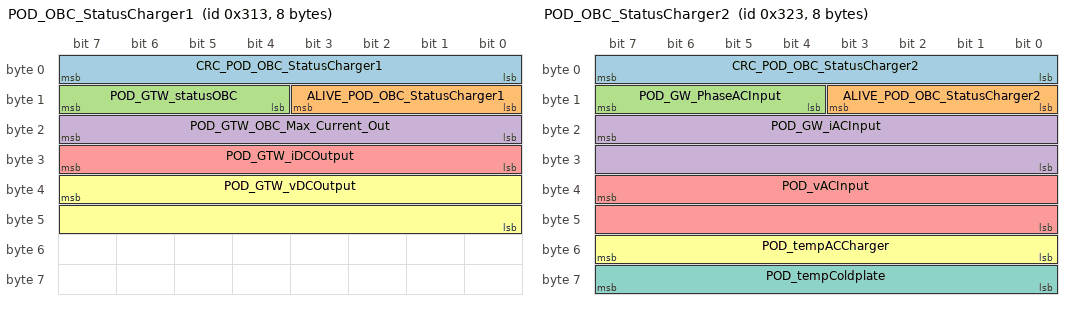
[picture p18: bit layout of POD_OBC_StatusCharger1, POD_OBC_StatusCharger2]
BO_ 787 POD_OBC_StatusCharger1: 8 CVC_I
 SG_ CRC_POD_OBC_StatusCharger1 : 7|8@0+ (1,0) [0|255] ""  MHU
 SG_ ALIVE_POD_OBC_StatusCharger1 : 11|4@0+ (1,0) [0|15] ""  MHU
 SG_ POD_GTW_statusOBC : 15|4@0+ (1,0) [0|15] ""  MHU
 SG_ POD_GTW_OBC_Max_Current_Out : 23|8@0+ (1,0) [0|64] ""  MHU
 SG_ POD_GTW_iDCOutput : 31|8@0+ (1,-50) [-50|50] "A"  MHU
 SG_ POD_GTW_vDCOutput : 39|16@0+ (0.0625,0) [0|512] "V"  MHU

BO_ 803 POD_OBC_StatusCharger2: 8 CVC_I
 SG_ CRC_POD_OBC_StatusCharger2 : 7|8@0+ (1,0) [0|255] ""  MHU
 SG_ ALIVE_POD_OBC_StatusCharger2 : 11|4@0+ (1,0) [0|15] ""  MHU
 SG_ POD_GW_PhaseACInput : 15|4@0+ (1,0) [0|3] ""  MHU
 SG_ POD_GW_iACInput : 23|16@0+ (0.0625,0) [0|60] "amps"  MHU
 SG_ POD_vACInput : 39|16@0+ (0.0625,0) [0|512] "V"  MHU
 SG_ POD_tempACCharger : 55|8@0+ (1,-40) [-40|150] "degC"  MHU
 SG_ POD_tempColdplate : 63|8@0+ (1,-40) [-40|150] "degC"  MHU

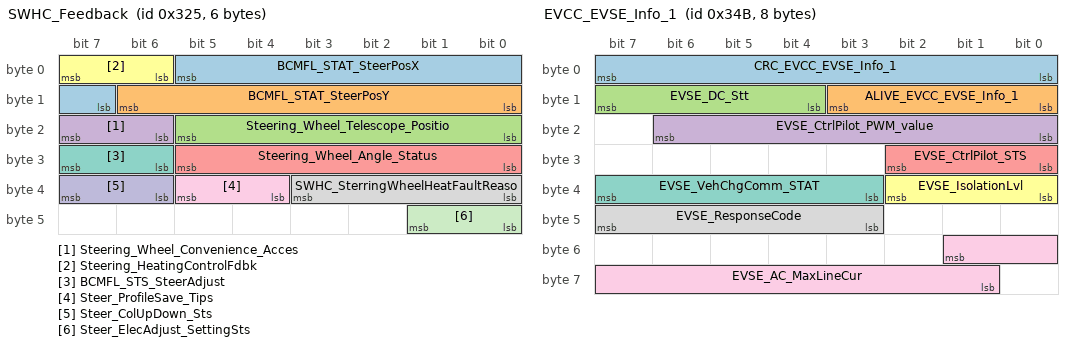
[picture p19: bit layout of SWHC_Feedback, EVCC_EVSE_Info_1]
BO_ 805 SWHC_Feedback: 6 CVC_I
 SG_ BCMFL_STAT_SteerPosX : 5|7@0+ (1,-50) [-50|50] "mm"  MHU
 SG_ BCMFL_STAT_SteerPosY : 14|7@0+ (1,-50) [-50|50] "mm"  MHU
 SG_ Steering_Wheel_Telescope_Positio : 21|6@0+ (1,-20) [-20|20] "mm"  MHU
 SG_ Steering_Wheel_Convenience_Acces : 23|2@0+ (1,0) [0|3] ""  MHU
 SG_ Steering_Wheel_Angle_Status : 29|6@0+ (0.1,-2.1) [-2.1|2.1] "Degree"  MHU
 SG_ Steering_HeatingControlFdbk : 7|2@0+ (1,0) [0|3] ""  MHU
 SG_ BCMFL_STS_SteerAdjust : 31|2@0+ (1,0) [0|3] ""  MHU
 SG_ SWHC_SterringWheelHeatFaultReaso : 35|4@0+ (1,0) [0|15] ""  MHU
 SG_ Steer_ProfileSave_Tips : 37|2@0+ (1,0) [0|3] ""  MHU
 SG_ Steer_ColUpDown_Sts : 39|2@0+ (1,0) [0|3] ""  MHU
 SG_ Steer_ElecAdjust_SettingSts : 41|2@0+ (1,0) [0|3] ""  MHU

BO_ 815 WCBS_ADAS_Info: 24 CVC_I
 SG_ CRC_WCBS_ADAS_Info : 7|8@0+ (1,0) [0|255] ""  MHU,SRR_RR,SRR_FR
 SG_ ALIVE_WCBS_ADAS_Info : 11|4@0+ (1,0) [0|15] ""  MHU,SRR_RR,SRR_FR
 SG_ WCBS_ACC_Available_Flag : 13|1@0+ (1,0) [0|1] ""  MHU,SRR_RR,SRR_FR
 SG_ WCBS_ACC_Deceleration_Flag : 14|1@0+ (1,0) [0|1] ""  MHU,SRR_RR,SRR_FR
 SG_ WCBS_ACC_Acceleration_Flag : 15|1@0+ (1,0) [0|1] ""  MHU,SRR_RR,SRR_FR
 SG_ WCBS_RAEB_Active_Flag : 18|1@0+ (1,0) [0|1] ""  MHU,SRR_RR,SRR_FR
 SG_ WCBS_RAEB_Available_Flag : 19|1@0+ (1,0) [0|1] ""  MHU,SRR_RR,SRR_FR
 SG_ WCBS_AEB_Active_Flag : 20|1@0+ (1,0) [0|1] ""  MHU,SRR_RR,SRR_FR
 SG_ WCBS_AEB_Available_Flag : 21|1@0+ (1,0) [0|1] ""  MHU,SRR_RR,SRR_FR
 SG_ WCBS_ACC_DriverOverride : 23|2@0+ (1,0) [0|3] ""  MHU,SRR_RR,SRR_FR
 SG_ WCBS_ACC_TargetWheel_Torque : 31|16@0+ (1,-8000) [-8000|8000] "Nm"  DUMMY_ECU
 SG_ WCBS_ACC_WheelTrq_Active : 12|1@0+ (1,0) [0|1] ""  DUMMY_ECU
 SG_ WCBS_RAEB_BrakeActuator : 47|3@0+ (1,0) [0|7] ""  DUMMY_ECU
 SG_ Secure_ResetCnt_0x32F : 135|16@0+ (1,0) [0|65535] ""  DUMMY_ECU
 SG_ Secure_MsgCnt_0x32F : 151|16@0+ (1,0) [0|65535] ""  DUMMY_ECU
 SG_ Secure_MAC_0x32F : 167|32@0+ (1,0) [0|4294967295] ""  DUMMY_ECU

BO_ 838 POD_StatusDCDC2: 8 CVC_I
 SG_ CRC_POD_StatusDCDC2 : 7|8@0+ (1,0) [0|255] ""  MHU
 SG_ ALIVE_POD_StatusDCDC2 : 11|4@0+ (1,0) [0|15] ""  MHU
 SG_ POD_vDCInput : 23|16@0+ (0.0625,0) [0|512] "V"  MHU
 SG_ POD_iDCDCOutput : 39|16@0+ (0.0625,0) [0|300] "A"  MHU
 SG_ POD_vDCDCOutput : 55|16@0+ (0.0625,0) [0|18] "V"  MHU

BO_ 843 EVCC_EVSE_Info_1: 8 CVC_I
 SG_ CRC_EVCC_EVSE_Info_1 : 7|8@0+ (1,0) [0|255] ""  MHU
 SG_ ALIVE_EVCC_EVSE_Info_1 : 11|4@0+ (1,0) [0|15] ""  MHU
 SG_ EVSE_DC_Stt : 15|4@0+ (1,0) [0|12] ""  MHU
 SG_ EVSE_CtrlPilot_PWM_value : 22|7@0+ (1,0) [0|100] "%"  MHU
 SG_ EVSE_CtrlPilot_STS : 26|3@0+ (1,0) [0|6] ""  MHU
 SG_ EVSE_IsolationLvl : 34|3@0+ (1,0) [0|5] ""  MHU
 SG_ EVSE_VehChgComm_STAT : 39|5@0+ (1,0) [0|27] ""  MHU
 SG_ EVSE_ResponseCode : 47|5@0+ (1,0) [0|26] ""  MHU
 SG_ EVSE_AC_MaxLineCur : 49|9@0+ (1,0) [0|400] "A"  MHU

BO_ 847 EVCC_EVSE_Info_2: 8 CVC_I
 SG_ CRC_EVCC_EVSE_Info_2 : 7|8@0+ (1,0) [0|255] ""  MHU
 SG_ ALIVE_EVCC_EVSE_Info_2 : 11|4@0+ (1,0) [0|15] ""  MHU
 SG_ EVSE_DC_MaxChgCur : 23|16@0+ (0.1,0) [0|6553.5] "A"  MHU
 SG_ EVSE_DC_MaxChgPwr : 39|16@0+ (0.1,0) [0|6553.5] "kW"  MHU
 SG_ EVSE_DC_ActCurOut : 55|16@0+ (0.1,0) [0|6553.5] "A"  MHU

BO_ 852 CVC_FCAM_req: 16 CVC_I
 SG_ CRC_CVC_FCAM_req : 7|8@0+ (1,0) [0|255] ""  MHU,FCAM_I,SRR_RR,SRR_FR,ADCU_I
 SG_ ALIVE_CVC_FCAM_req : 11|4@0+ (1,0) [0|15] ""  MHU,FCAM_I,SRR_RR,SRR_FR,ADCU_I
 SG_ CVC_RAEB_Mode : 13|2@0+ (1,0) [0|3] ""  FCAM_I,SRR_RR,SRR_FR,ADCU_I
 SG_ CVC_LA_AudWarning : 15|2@0+ (1,0) [0|3] ""  FCAM_I,SRR_RR,SRR_FR,ADCU_I
 SG_ CVC_BSD_On : 17|2@0+ (1,0) [0|3] ""  FCAM_I,SRR_RR,SRR_FR,ADCU_I
 SG_ CVC_BSD_sens : 19|2@0+ (1,0) [0|3] ""  FCAM_I,SRR_RR,SRR_FR,ADCU_I
 SG_ CVC_BSD_AudWarning : 21|2@0+ (1,0) [0|3] ""  FCAM_I,SRR_RR,SRR_FR,ADCU_I
 SG_ CVC_RCTA_On : 23|2@0+ (1,0) [0|3] ""  FCAM_I,SRR_RR,SRR_FR,ADCU_I
 SG_ CVC_RCTA_sens : 25|2@0+ (1,0) [0|3] ""  FCAM_I,SRR_RR,SRR_FR,ADCU_I
 SG_ CVC_PA_On : 27|2@0+ (1,0) [0|3] ""  FCAM_I,SRR_RR,SRR_FR,ADCU_I
 SG_ CVC_AHB_On : 29|2@0+ (1,0) [0|3] ""  FCAM_I,SRR_RR,SRR_FR,ADCU_I
 SG_ CVC_IA_Mode : 31|2@0+ (1,0) [0|3] ""  FCAM_I,SRR_RR,SRR_FR,ADCU_I
 SG_ CVC_TSR_Mode : 33|2@0+ (1,0) [0|3] ""  FCAM_I,SRR_RR,SRR_FR,ADCU_I
 SG_ CVC_DOW_Mode : 35|2@0+ (1,0) [0|3] ""  FCAM_I,SRR_RR,SRR_FR,ADCU_I
 SG_ CVC_AHB_sens : 37|2@0+ (1,0) [0|3] ""  FCAM_I,SRR_RR,SRR_FR,ADCU_I
 SG_ CVC_FCW_sens : 39|2@0+ (1,0) [0|3] ""  FCAM_I,SRR_RR,SRR_FR,ADCU_I
 SG_ CVC_LA_Mode : 41|3@0+ (1,0) [0|7] ""  FCAM_I,SRR_RR,SRR_FR,ADCU_I
 SG_ CVC_FCW_Mode : 43|2@0+ (1,0) [0|3] ""  FCAM_I,SRR_RR,SRR_FR,ADCU_I
 SG_ CVC_SET_TSR_AudWarn : 45|2@0+ (1,0) [0|3] ""  FCAM_I,SRR_RR,SRR_FR,ADCU_I
 SG_ CVC_SET_TSR_SLAert : 47|2@0+ (1,0) [0|3] ""  FCAM_I,SRR_RR,SRR_FR,ADCU_I
 SG_ CVC_LA_sens : 49|2@0+ (1,0) [0|3] ""  FCAM_I,SRR_RR,SRR_FR,ADCU_I
 SG_ CVC_AEB_Mode : 51|2@0+ (1,0) [0|3] ""  FCAM_I,SRR_RR,SRR_FR,ADCU_I
 SG_ CVC_ESA_ON : 54|1@0+ (1,0) [0|1] ""  FCAM_I,SRR_RR,SRR_FR,ADCU_I
 SG_ CVC_ELKA_ON : 56|1@0+ (1,0) [0|1] ""  FCAM_I,SRR_RR,SRR_FR,ADCU_I
 SG_ CVC_ALC_ON : 58|2@0+ (1,0) [0|3] ""  FCAM_I,SRR_RR,SRR_FR,ADCU_I
 SG_ CVC_DashCam_Setting : 61|3@0+ (1,0) [0|7] ""  FCAM_I,SRR_RR,SRR_FR,ADCU_I
 SG_ CVC_LKA_LDW_Haptic_Mode : 53|1@0+ (1,0) [0|1] ""  FCAM_I,SRR_RR,SRR_FR,ADCU_I
 SG_ CVC_ELK_Haptic_Mode : 52|1@0+ (1,0) [0|1] ""  FCAM_I,SRR_RR,SRR_FR,ADCU_I
 SG_ CVC_TSR_Haptic_Mode : 63|1@0+ (1,0) [0|1] ""  FCAM_I,SRR_RR,SRR_FR,ADCU_I
 SG_ CVC_SLW_Mode_Req : 62|1@0+ (1,0) [0|1] ""  FCAM_I,SRR_RR,SRR_FR,ADCU_I
 SG_ CVC_HWA_Mode : 64|1@0+ (1,0) [0|1] ""  FCAM_I,ADCU_I
 SG_ CVC_ISA_ON : 89|2@0+ (1,0) [0|3] ""  FCAM_I,SRR_RR,SRR_FR,ADCU_I
 SG_ CVC_Option_feed : 67|2@0+ (1,0) [0|3] ""  FCAM_I,SRR_RR,SRR_FR,ADCU_I
 SG_ CVC_ALCA_LaneChange_confir : 69|2@0+ (1,0) [0|3] ""  FCAM_I,SRR_RR,SRR_FR,ADCU_I
 SG_ CVC_FCTB_Mode : 71|2@0+ (1,0) [0|3] ""  MHU,FCAM_I,SRR_FR
 SG_ CVC_RCTB_Mode : 73|2@0+ (1,0) [0|3] ""  MHU,SRR_RR,ADCU_I
 SG_ CVC_ACPE_Setting : 75|2@0+ (1,0) [0|3] ""  MHU,ADCU_I
 SG_ CVC_ACPE_Sens : 77|2@0+ (1,0) [0|3] ""  MHU,ADCU_I
 SG_ CVC_SVM_Setting_Guideline : 79|2@0+ (1,0) [0|3] ""  MHU,ADCU_I
 SG_ CVC_SVM_Setting_ObjOverlay : 81|2@0+ (1,0) [0|3] ""  MHU,ADCU_I
 SG_ CVC_SVM_Setting_TrailerGuideline : 83|2@0+ (1,0) [0|3] ""  MHU,ADCU_I
 SG_ CVC_SVM_Setting_MaxDoorOverlay : 85|2@0+ (1,0) [0|3] ""  MHU,ADCU_I
 SG_ CVC_SVM_TransparentRequest : 87|2@0+ (1,0) [0|3] ""  MHU,ADCU_I
 SG_ CVC_SVM_Setting_BlindSpotView : 95|2@0+ (1,0) [0|3] ""  MHU,ADCU_I
 SG_ CVC_NOP_Mode : 91|2@0+ (1,0) [0|3] ""  FCAM_I,ADCU_I
 SG_ CVC_NOP_Type : 93|2@0+ (1,0) [0|3] ""  ADCU_I
 SG_ CVC_ALC_Recommend : 65|1@0+ (1,0) [0|1] ""  FCAM_I,ADCU_I
 SG_ CVC_TLD_On : 103|2@0+ (1,0) [0|3] ""  ADCU_I

CM_ SG_ 133 CRC_ACU_CRASH_INFO "Checksum";
CM_ SG_ 133 ALIVE_ACU_CRASH_INFO "Alive Counter";
CM_ SG_ 133 ACU_Crash_Sts "Crash status";
CM_ SG_ 133 ACU_Airbag_Deployment_Status "Signal to indicate if airbag pretensioner pyrofuse is deployed";
CM_ SG_ 133 ACU_Crash_Intensity "Indicate crash intensity level";
CM_ SG_ 133 ACU_Front_Crash "Frontal collision";
CM_ SG_ 133 ACU_DriverSide_Crash "Driver's side collision";
CM_ SG_ 133 ACU_PassSide_Crash "Passenger side collision";
CM_ SG_ 133 ACU_Rear_Crash "Rear collision";
CM_ SG_ 133 ACU_Rollover_Crash "Has the vehicle experienced a rollover collision";
CM_ SG_ 169 BCMFL_AmbientTemp "Ambient temperature";
CM_ SG_ 169 BCMFL_CabinHeat_TempSensor "the Interior Temperature with Celcius Degree";
CM_ SG_ 169 BCMFL_AmbientTempSts "Environmental temperature sensor input value";
CM_ SG_ 169 BCMFL_CoolantTemp_EDS_In_Sts "Front EDS Inlet Coolant Temperature Sensor Status";
CM_ SG_ 169 BCMFL_CoolantTemp_EDS_Out_Sts "Front EDS Outlet Coolant Temperature";
CM_ SG_ 169 BCMFL_CoolantTemp_LTR_Out_Sts "LTR Outlet Coolant Temperature Sensor Status";
CM_ SG_ 169 BCMFL_ACLowSideTemperatureSts "Temperature status on the low-pressure side of the air conditioner";
CM_ SG_ 169 BCMFL_ACLowSidePressureSts "Pressure state on the low-pressure side of the air conditioner";
CM_ SG_ 169 BCMFL_ACHighSideTemperatureSts "Temperature status on the high-pressure side of the air conditioner";
CM_ SG_ 169 BCMFL_ACHighSidePressureSts "Pressure status on the high-pressure side of the air conditioner";
CM_ SG_ 169 BCMFL_CoolantTemp_HtrCore_In_Sts "Heater Core Inlet Coolant Temperature Sensor Status";
CM_ SG_ 169 BCMFL_Refrigerant_Temp_Sensor_St "Refrigerant temperature sensor status";
CM_ SG_ 169 BCMFL_PT_Sensor1_Pressure_Sts "Pressure state of pressure and temperature sensor [1]";
CM_ SG_ 169 BCMFL_PT_Sensor2_Pressure_Sts "Pressure state of pressure and temperature sensor [2]";
CM_ SG_ 201 CRC_FMCU_Status "Checksum of this message";
CM_ SG_ 201 ALIVE_FMCU_Status "Signal counting the times of this message";
CM_ SG_ 201 FMCU_MotorTq "Front Motor torque";
CM_ SG_ 201 FMCU_MotorSpd "Front Motor rotating speed";
CM_ SG_ 201 FMCU_StsMCUFault "FMCU Fault Status";
CM_ SG_ 201 FMCU_MotorSpdSts "Front Motor rotating speed Invalid";
CM_ SG_ 201 FMCU_MotorTqSts "Front Motor torque Invalid";
CM_ SG_ 201 FMCU_CVC_CtrlMode "FMCU control mode";
CM_ SG_ 201 FMCU_CVC_StsMode "FMCU Operating Mode";
CM_ SG_ 203 CRC_RMCU_Status "Checksum of this message";
CM_ SG_ 203 ALIVE_RMCU_Status "Signal counting the times of this message";
CM_ SG_ 203 RMCU_MotorTq "Rear Motor torque";
CM_ SG_ 203 RMCU_MotorSpd "Rear Motor rotating speed";
CM_ SG_ 203 RMCU_StsMCUFault "RMCU Fault Status";
CM_ SG_ 203 RMCU_MotorSpdValid "Rear Motor rotating speed Invalid";
CM_ SG_ 203 RMCU_MotorTqValid "Rear Motor torque Invalid";
CM_ SG_ 203 RMCU_CVC_CtrlMode "RMCU control mode";
CM_ SG_ 203 RMCU_CVC_StsMode "RMCU Operating Mode";
CM_ SG_ 217 CRC_CVC_HV_DrvSys_status "Checksum";
CM_ SG_ 217 ALIVE_CVC_HV_DrvSys_status "Alive counter";
CM_ SG_ 217 CVC_HVsystem_status "High Voltage system status";
CM_ SG_ 217 CVC_ACPD_Percent "The signal contains the actual angle of the acceleration pedal100% acceleration pedal position shall only provided in case of kick down.Without kickdown the maximum value shall be 99.";
CM_ SG_ 217 CVC_ACPD_Percent_Valid "Qualifier for corresponding signal.  In value table not defined values are reserved";
CM_ SG_ 217 CVC_ACTGear "actual gear,Provide gear shift signal";
CM_ SG_ 217 CVC_ACTGearValid "Indicate the current gear position";
CM_ SG_ 217 CVC_ACT_DriveMode "Vehicle drive mode";
CM_ SG_ 217 CVC_ACT_DriveMode_Valid "Vehicle drive mode status";
CM_ SG_ 217 CVC_HV_DRVsystem_status "Status of driving system ( Highvoltage )";
CM_ SG_ 217 CVC_Recu_BrakeLight_ON_Req "CVC request brake light ON when regen";
CM_ SG_ 258 CRC_CVC_LOGICAL_CLAMP "Checksum";
CM_ SG_ 258 ALIVE_CVC_LOGICAL_CLAMP "Alive counter";
CM_ SG_ 258 STAT_CrankRelayHW_BCM "Represents the status of the starter relais";
CM_ SG_ 258 CVC_Transport_Mode "Transport mode shall be enable during storage or transportation with long-distance travel.";
CM_ SG_ 258 CVC_Vehicle_Special_Mode "Accessory mode of the vehicle";
CM_ SG_ 258 CVC_Acc_Mode_Req "Request vehicle into ACC state to activate HV on in some special mode/function of vehicle";
CM_ SG_ 258 CVC_CL30s_Req "Request to control ON/OFF CL30s relay";
CM_ SG_ 258 CVC_CL30c_Req "Request to control ON/OFF CL30c relay";
CM_ SG_ 258 CVC_CLR_Req "Request to control ON/OFF CLR relay";
CM_ SG_ 258 CVC_CL15_Req "Request to control ON/OFF CL15 relay";
CM_ SG_ 258 Warning_Clamp_Incompatible "Send alert to CAN in case of clamp status not the same as request";
CM_ SG_ 258 CVC_CL58_Req "Request to control ON/OFF CL58 relay";
CM_ SG_ 260 CRC_BCM_FL_Measured_Data "Checksum";
CM_ SG_ 260 ALIVE_BCM_FL_Measured_Data "Alive counter";
CM_ SG_ 260 SOH_SUL "Actual name LV_SOH (State of Health)";
CM_ SG_ 260 SOH_SUL_STATE "Actual name LV_SOH_Sts (SOH Status)";
CM_ SG_ 260 SOC_STATE "SOC Status";
CM_ SG_ 260 Resp_Error "Resp_Error";
CM_ SG_ 260 FLAG_INCONSTENCY "Battery inconsistency flag";
CM_ SG_ 260 EBS_error "EBS error";
CM_ SG_ 260 FLAG_DISCONNECT "Battery disconnection flag";
CM_ SG_ 260 IBATT_QUIESCENT "IBATT_QUIESCENT";
CM_ SG_ 260 LV_TargetCurrent "Target battery current from LV BMS";
CM_ SG_ 260 LV_TargetVoltage "LV BMS sends out expected target voltage";
CM_ SG_ 260 LV_ContinuousWakeUpCnt "Continuous wake-up count of low-voltage system";
CM_ SG_ 262 CRC_CVC_Body_LIGHT "Checksum";
CM_ SG_ 262 ALIVE_CVC_Body_LIGHT "Alive counter";
CM_ SG_ 262 Body_DayRunningLampSts "DayRunning Lamp output Status";
CM_ SG_ 262 Body_ReverseLightSts "Reverse light output Status";
CM_ SG_ 262 Body_StopLightSts "Stop light output Status";
CM_ SG_ 262 Body_LicensePlateLightSts "License plate light output";
CM_ SG_ 262 Body_Fr_Dimming_dome_lampSts "Dimming dome lamp Front Status";
CM_ SG_ 262 Body_Rr_Dimming_dome_lampSts "Dimming dome lamp Rear Status";
CM_ SG_ 262 Body_STAT_InteriorLight "Status for functional illumination in the interior light switch button";
CM_ SG_ 262 Body_STAT_LightActivation "Status of light";
CM_ SG_ 262 Body_HighBeamSts "High beam output Status";
CM_ SG_ 262 Body_STAT_SwitchLightBrightness "Confirm Brighness level of Switch illumination";
CM_ SG_ 262 Body_LowBeamSts "Low beam output  Status";
CM_ SG_ 262 Body_RearFogLmpSts "Rear fog output Status";
CM_ SG_ 262 Body_FrntFogLmpSts "Front fog output Status";
CM_ SG_ 262 Body_PosLmpSts "Position light output Status";
CM_ SG_ 262 Body_HornSts "Horn output Status";
CM_ SG_ 262 Body_TurnIndicatorSts "Turn light output  Status";
CM_ SG_ 264 CRC_SS_DriveReq_0x108 "Check sum";
CM_ SG_ 264 ALIVE_SS_DriveReq_0x108 "Rolling Counter";
CM_ SG_ 264 SS_P_Button "The button for the P (parking) gear position";
CM_ SG_ 264 SS_TargetGearReq "Target gear request";
CM_ SG_ 264 SS_ADAS_Req "ADAS request";
CM_ SG_ 264 SS_DrvMd_RgnLvl_Req "Driving mode request";
CM_ SG_ 264 SS_Fault "Fault status";
CM_ SG_ 264 SS_HighBeam_Req "High beam Control Request";
CM_ SG_ 264 SS_Lane_Change_Indicator_Req "Lane Change Indicator Request";
CM_ SG_ 264 SS_FR_RR_WashAndMist_Req "Front and Rear Washer and Mist function control request";
CM_ SG_ 264 SS_RR_WiperControl_Req "Rear Wiper Control Request";
CM_ SG_ 264 SS_FR_Wipercontrol_Req "Front Wiper control Request";
CM_ BO_ 265 "BCM switches status";
CM_ SG_ 265 CRC_CVC_Body_SwitchSts "Checksum";
CM_ SG_ 265 ALIVE_CVC_Body_SwitchSts "Alive counter";
CM_ SG_ 265 Body_STAT_BrakeSwitch "Brake pedal switch BCM pressed (only for brake light)";
CM_ SG_ 265 Body_STAT_HazardWarn "Hazard Warning switch activation";
CM_ SG_ 265 Body_STAT_Autowiping "Status for Autowiping ON /OFF";
CM_ SG_ 265 Body_TurnIndicator "BCM_TurnIndicator";
CM_ SG_ 266 CRC_BCM_VOLTAGE "Checksum";
CM_ SG_ 266 ALIVE_BCM_VOLTAGE "Alive counter";
CM_ SG_ 266 LV_BatteryType "LV Battery Type (Lead Acid or Lithium)";
CM_ SG_ 266 UBatt "Battery Voltage";
CM_ SG_ 266 LV_Batt_Temp_Reserved "Low voltage Battery Temperature";
CM_ SG_ 266 LV_SOC_Reserved "State Of charge for Low Voltage Battery";
CM_ SG_ 266 LV_Batt_Current_Reserved "Current of Low Voltage Battery";
CM_ SG_ 180 BCMFL_WindowsFL_AntiPinch_Warn "Feedback anti-pinch status to CVC for HMI warning";
CM_ SG_ 180 BCMFL_WindowFL_Learning_Sts "Feedback learning status to CVC";
CM_ SG_ 180 BCMFL_WindowFL_Suppression_Warn "Feedback the lifter suppression status";
CM_ SG_ 180 BCMFL_WindowFL_LockActive "Feedback current window lock status";
CM_ SG_ 180 BCMFL_WindowFL_ThermalProtect "Feedback thermal protection status";
CM_ SG_ 180 BCMFL_WindowFL_Error "Feedback front left window error position to CVC for corresponding warning on HMI";
CM_ SG_ 180 BCMFL_WindowsRL_AntiPinch_Warn "Feedback anti-pinch status to CVC for HMI warning";
CM_ SG_ 180 BCMFL_WindowRL_LockActive "Feedback current window lock status";
CM_ SG_ 180 BCMFL_WindowRL_Error "Feedback rear left window error position to CVC for corresponding warning on HMI";
CM_ SG_ 180 BCMFL_WindowRL_Learning_Sts "Feedback learning status to CVC";
CM_ SG_ 180 BCMFL_WindowRL_Suppression_Warn "Feedback the lifter suppression status";
CM_ SG_ 180 BCMFL_WindowRL_ThermalProtect "Feedback thermal protection status";
CM_ SG_ 180 Window_Position_FL "Feedback the current front left window position to CVC";
CM_ SG_ 180 Window_Position_RL "Feedback the current rear left window position to CVC";
CM_ SG_ 180 BCMFL_WindowBtnPress_RL "Rear Left Window Button status";
CM_ SG_ 180 BCMFL_WindowBtnPress_FL "Front Left Window Button status";
CM_ SG_ 530 BCM_TurnIndicator_FR_STS "Feedback status of FR indicator";
CM_ SG_ 530 BCM_PositionLight_FR_STS "Feedback on the status of the right reversing light";
CM_ SG_ 530 BCM_FrontFogLamp_FR_STS "Front right daytime running light status";
CM_ SG_ 530 BCM_DaytimeRunningLight_FR_Sts "Front right rearview mirror LED status";
CM_ SG_ 530 BCM_MirrorLED_FR_STS "Front right low beam status";
CM_ SG_ 530 BCM_LowBeam_FR_Sts "Front right high beam status";
CM_ SG_ 530 BCM_HighBeam_FR_Sts "Feedback right brake light status";
CM_ SG_ 267 ALIVE_TRM_LIGHT "Alive counter rolling counter of the message if it's over 14 then will swap back to 0 and increase again. Invalid Value = F";
CM_ SG_ 267 TrailerInput "Trailer synchronization confirmation with HW/SW";
CM_ SG_ 267 TrailerSystemError "Trailer error detection";
CM_ SG_ 267 TRM_VoltageStatus "Trailer voltage status";
CM_ SG_ 267 TRM_STAT_BrakeLight "Trailer Brake light status";
CM_ SG_ 267 TRM_STAT_FogLampRear "Trailer Rear fog lamp status";
CM_ SG_ 267 TRM_STAT_PositionLight "Trailer Position light status";
CM_ SG_ 267 TRM_STAT_TurnIndicators "Trailer Turn Indicatiors status";
CM_ SG_ 267 TRM_STAT_ReverseLight "Trailer Reverse light status";
CM_ SG_ 267 TRM_STAT_HWBrakeLightInput "Trailer hardwired Brake light inputstatus";
CM_ SG_ 267 TRM_STAT_HWIndicatorInput "Trailer hardwired Turn Indicatiors input status";
CM_ SG_ 267 TRM_STAT_HWPosLightInput "Trailer hardwired Position light input status";
CM_ SG_ 273 CVC_F_RegenTrqMaxValid "Effective position of maximum regenerative torque on the front axle";
CM_ SG_ 273 CVC_R_RegenTrqMaxValid "Effective position of maximum regenerative torque on the rear axle";
CM_ SG_ 273 CVC_F_BrkRegenTrqActualValid "Effective position of actual brake recovery torque on the front axle";
CM_ SG_ 273 CVC_R_BrkRegenTrqActualValid "Effective position of actual brake recovery torque on the rear axle";
CM_ SG_ 273 CVC_F_RegenTrqMax "Maximum recoverable torque of front axle";
CM_ SG_ 273 CVC_R_RegenTrqMax "Maximum recoverable torque of rear axle";
CM_ SG_ 273 CVC_F_BrkRegenTrqActual "Actual braking recovery torque of front axle";
CM_ SG_ 273 CVC_R_BrkRegenTrqActual "Actual braking recovery torque of rear axle";
CM_ SG_ 273 CVC_OnePedalModeSts "One pedal function request mode";
CM_ SG_ 273 CVC_OnePedalModeEnable "CVC OPD function enable status received by MHU";
CM_ SG_ 273 CVC_TargetBrkTq "one-pedal function to target the braking torque";
CM_ SG_ 274 CRC_CVC_CLAMP_STAT "Checksum";
CM_ SG_ 274 ALIVE_CVC_CLAMP_STAT "Alive counter";
CM_ SG_ 274 CVC_STAT_BLS "Signal represent plausibility of both HW Inputs for brake light switch.";
CM_ SG_ 274 Vehicle_Operation_State "Represent the status of physical terminal";
CM_ BO_ 279 "EPBi Brake presure";
CM_ SG_ 279 WCBS_CircuitPress "Real pressure in circuit after offset correction";
CM_ SG_ 279 WCBS_CircuitPressValid "Validity of circuit pressure";
CM_ SG_ 279 WCBS_EstWhlPress_FL "Estimated pressure at invidual wheel";
CM_ SG_ 279 WCBS_EstWhlPress_FR "Estimated pressure at invidual wheel";
CM_ SG_ 279 WCBS_EstWhlPress_RL "Estimated pressure at invidual wheel";
CM_ SG_ 279 WCBS_EstWhlPress_RR "Estimated pressure at invidual wheel";
CM_ SG_ 279 WCBS_EstWhlPressValid "Validity of wheel pressure estimation";
CM_ SG_ 279 WCBS_MainCylinderPress "Driver demand pressure";
CM_ SG_ 279 WCBS_MainCylinderPressValid "Validity of Main cylinder pressure";
CM_ SG_ 289 WCBS_RRWheelSpeedKPH "Signal from ABS to indicate the rear right wheel speed in kph";
CM_ SG_ 289 WCBS_RRWheelSpeedValid "signal to identify if the wheel speed value valid";
CM_ SG_ 289 WCBS_RRWheelDirection "indicate the rear right wheel direction";
CM_ SG_ 289 WCBS_RLWheelDirection "indicate the rear left wheel direction";
CM_ SG_ 289 WCBS_RLWheelSpeedKPH "Signal from ABS to indicate the rear left wheel speed in kph";
CM_ SG_ 289 WCBS_RLWheelSpeedValid "signal to identify if the wheel speed value valid";
CM_ SG_ 290 CRC_WCBS_WheelSpeedKPH_F "CRC code to check the data integrity";
CM_ SG_ 290 ALIVE_WCBS_WheelSpeedKPH_F "signal couting the times of this message";
CM_ SG_ 290 WCBS_FRWheelSpeedKPH "Signal from ABS to indicate the front right wheel speed in kph";
CM_ SG_ 290 WCBS_FRWheelSpeedValid "signal to identify if the wheel speed value valid";
CM_ SG_ 290 WCBS_FRWheelDirection "indicate the front right wheel direction";
CM_ SG_ 290 WCBS_FLWheelDirection "indicate the front left wheel direction";
CM_ SG_ 290 WCBS_FLWheelSpeedKPH "Signal from ABS to indicate the front left wheel speed in kph";
CM_ SG_ 290 WCBS_FLWheelSpeedValid "signal to identify if the wheel speed value valid";
CM_ SG_ 291 CRC_CVC_ACCharging_Info "Checksum";
CM_ SG_ 291 ALIVE_CVC_ACCharging_Info "Alive counter";
CM_ SG_ 291 ACCharging_MaxChargingPower "Max  Power of AC Charging gun.";
CM_ SG_ 291 CurrentACChargingPower "Nominal power from AC charnge gun";
CM_ SG_ 291 ACCharging_MaxCurrent "Max current of AC Charging gun";
CM_ SG_ 292 CRC_WCBS_WheelSpeedRC "CRC code to check the data integrity";
CM_ SG_ 292 ALIVE_WCBS_WheelSpeedRC "signal couting the times of this message";
CM_ SG_ 292 WCBS_FLWheelSpeedRCSts "Signal from ABS to indicate the front left wheel speed pulse";
CM_ SG_ 292 WCBS_RLWheelSpeedRCSts "Signal from ABS to indicate the rear left wheel speed pulse";
CM_ SG_ 292 WCBS_FRWheelSpeedRCSts "Signal from ABS to indicate the front right wheel speed pulse";
CM_ SG_ 292 WCBS_RRWheelSpeedRCSts "Signal from ABS to indicate the rear right wheel speed pulse";
CM_ SG_ 292 WCBS_RLWheelSpeedRC "Signal from ABS to indicate the rear left wheel speed pulse";
CM_ SG_ 292 WCBS_RRWheelSpeedRC "Signal from ABS to indicate the rear right wheel speed pulse";
CM_ SG_ 292 WCBS_FLWheelSpeedRC "Signal from ABS to indicate the front left wheel speed pulse";
CM_ SG_ 292 WCBS_FRWheelSpeedRC "Signal from ABS to indicate the front right wheel speed pulse";
CM_ SG_ 293 CRC_CVC_DCCharging_Info "Checksum";
CM_ SG_ 293 ALIVE_CVC_DCCharging_Info "Alive counter";
CM_ SG_ 293 DCCharging_MaxChargingPower "Max power from the DC charging gun";
CM_ SG_ 293 CurrentDCChargingPower "Nominal power output from DC charge gun";
CM_ SG_ 293 DCCharging_MaxCurrent "Max current from the DC charging gun";
CM_ SG_ 306 ESC_SlopeGrade "Vehicle slope,Uphill is negative (head is higher than tail), downhill is positive (tail is higher than head)";
CM_ SG_ 306 ESC_HSA_Control_Status "Indicate HSA function is active or not";
CM_ SG_ 306 ESC_HSA_Status_Fault "Detect the HAS Fault status";
CM_ SG_ 306 ESC_TcsEnableSts "Indicate the TCS function can use or not";
CM_ SG_ 306 ESC_EscCtrlActv "Indicate ESC  function is active or not";
CM_ SG_ 306 ESC_TcsCtrlActv "Indicate TCS  function is active or not";
CM_ SG_ 306 ESC_EscFlgFlt "Detect the ESC function fault status";
CM_ SG_ 306 ESC_TcsFlgFlt "Detect the TCS function fault status";
CM_ SG_ 306 ESC_EscEnableSts "Indicate the ESC function can use or not";
CM_ SG_ 306 ESC_HBAFlgFlt "Detect the HBA(Hydraulic Brake Assist) function status";
CM_ SG_ 306 ESC_HbaCtrlActv "Indicate HBA(Hydraulic Brake Assist)   function is active or not";
CM_ SG_ 306 ESC_DTC_Active "DTC active or not";
CM_ SG_ 306 ESC_BTCSCtrlActv "Indicate Brake TCS is active or not";
CM_ SG_ 306 ESC_EngineCtrlActv "ESC Engine control active status(reserved)";
CM_ SG_ 311 CRC_EAS_CDC_WorkState "Checksum";
CM_ SG_ 311 ALIVE_EAS_CDC_WorkState "Alive Counter";
CM_ SG_ 311 EAS_StiffStsFL "Stiffness state FL";
CM_ SG_ 311 EAS_StiffStsFR "Stiffness state FR";
CM_ SG_ 311 EAS_StiffStsRL "Stiffness state RL";
CM_ SG_ 311 EAS_StiffStsRR "Stiffness state RR";
CM_ SG_ 311 EAS_WorkSts "EAS Work state";
CM_ SG_ 311 CDC_WorkSts "CDC Work state";
CM_ SG_ 311 EAS_CDC_SystemWorkMode "EAS CDC system work mode";
CM_ SG_ 311 EAS_SuspensionMode "EAS Suspension Work mode";
CM_ SG_ 311 EAS_EasyAccessSts "EAS Easy Access state";
CM_ SG_ 311 CDC_DamperMode "CDC Work mode";
CM_ SG_ 311 EAS_ValveValue_FL "Left front air spring valve status";
CM_ SG_ 311 EAS_ValveValue_FR "Right front air spring valve status";
CM_ SG_ 311 EAS_ValveValue_RL "Left rear air spring valve status";
CM_ SG_ 311 EAS_ValveValue_RR "Right rear air spring valve status";
CM_ SG_ 311 EAS_EnableSts "EAS enable disable state";
CM_ SG_ 311 CDC_ValveValue_FL "Left front CDC valve status";
CM_ SG_ 311 CDC_ValveValue_FR "Right front CDC valve status";
CM_ SG_ 311 CDC_ValveValue_RL "Left rear CDC valve status";
CM_ SG_ 311 CDC_ValveValue_RR "Right rear CDC valve status";
CM_ SG_ 311 EAS_MntnSts "Air spring maintenance mode status";
CM_ SG_ 311 EAS_EasyLoadingSetFb "Easy load mode feedback";
CM_ SG_ 311 EAS_LiftModFb "Automatic lift/jack mode feedback";
CM_ SG_ 311 EAS_VehicleUpDownState "Vehicle up and down status";
CM_ SG_ 311 EAS_Overheat_Warning "Overheating protection prompt for gas supply pump";
CM_ SG_ 311 EAS_VehiclePositionState "Vehicle Position State";
CM_ SG_ 311 EAS_VehicleTargetPositionState "Vehicle Target Position State";
CM_ SG_ 357 CRC_CVC_ChargingConnection "Checksum";
CM_ SG_ 357 ALIVE_CVC_ChargingConnection "Alive Counter";
CM_ SG_ 357 CVC_AcChgGunIn "Slow Charge Gun Insert Status";
CM_ SG_ 357 CVC_DCChgGunIn "Connection status of DC Fast charging Gun";
CM_ SG_ 357 CVC_ACChargingVoltage "The Power of this AC charging connection in KW";
CM_ SG_ 357 CVC_MinCurrentOfACCharging "Minium Charging current of this AC Charging connection";
CM_ SG_ 357 CVC_MaxCurrentOfACCharging "Maximum Charging current of AC Charging";
CM_ SG_ 372 CRC_BMS_CurMeas "Checksum";
CM_ SG_ 372 ALIVE_BMS_CurMeas "Alive Counter";
CM_ SG_ 372 BMS_StartOfMeasument_STS "Synchronize signals indicate start of cell/pack voltage measument";
CM_ SG_ 372 BMS_PackCur_MEAS "Battery Pack Total Current";
CM_ SG_ 372 BMS_HVPackVol_MEAS "Pack Voltage";
CM_ SG_ 372 BMS_HVLinkVol_MEAS "Link Voltage";
CM_ SG_ 372 BMS_HVBusVol_MEAS "BUS Voltage, it is informative";
CM_ SG_ 372 BMS_HVFuseVol_MEAS "Measure voltage after fuse to identify the fuse is blown or not";
CM_ SG_ 372 BMS_MainNegRelay_Volt "main negative relay diagnosis voltage";
CM_ SG_ 372 BMS_CellNumMinCellVol "Cell Number of Min Cell Voltage";
CM_ SG_ 372 BMS_CellNumMaxCellVol "Cell Number of Max Cell Voltage";
CM_ SG_ 372 BMS_MinCellVol "Min Cell Voltage";
CM_ SG_ 372 BMS_MaxCellVol "Max Cell Voltage";
CM_ SG_ 372 BMS_MaxMinDiffCellVol "max and min cell voltage differences";
CM_ SG_ 372 BMS_CVC_Insulation_Mon_Sts "Feedback for the Insulation Monitoring signal";
CM_ SG_ 372 BMS_PackInsuRes "Minimum value of BCU_PosInsuRes and BCU_NegInsuRes";
CM_ SG_ 382 CRC_EPS_SAS_Sensor "Checksum";
CM_ SG_ 382 ALIVE_EPS_SAS_Sensor "Alive Counter";
CM_ SG_ 382 SAS_SASStsSnsr "The flag of  SAS status Punch Steering angle status";
CM_ SG_ 382 SAS_SteerWhlRotSpd "The current rotation speed of the steering wheel.";
CM_ SG_ 382 SAS_SteerWhlRotSpdStatus "The status of SteerWheelRotSpd";
CM_ SG_ 382 SAS_SASFailure "Angle sensor disabled.";
CM_ SG_ 382 SAS_Calibrated "SAS calibration state";
CM_ SG_ 382 SAS_SteerWheelAngleValid "Effective signal for steering angle";
CM_ SG_ 382 SAS_SteerWheelAngle "The current angle of the steering wheel(Positive, to left Negative, to right)";
CM_ SG_ 466 CRC_FCAM_DEBUG "Checksum";
CM_ SG_ 466 ALIVE_FCAM_DEBUG "Alive Counter";
CM_ SG_ 466 FCAM_TSR_SLWSwtResp "TSR alarm function switch feedback";
CM_ SG_ 466 FCAM_FC_CalibrationSts "Front camera calibration status";
CM_ SG_ 466 FCAM_BlockageSts "Front camera occlusion status";
CM_ SG_ 466 FCAM_AEB_ABA_Req "ADAS requests ABA";
CM_ SG_ 466 FCAM_AEB_AWB_Req "Request short brake warning from WCBS";
CM_ SG_ 466 FCAM_AEB_TgtDecel_Req "AEB deceleration request";
CM_ SG_ 466 FCAM_AEB_VehHldReq "AEB requests WCBS to hold the vehicle";
CM_ SG_ 466 FCAM_AEB_AWB_Level "Requirements for different levels of braking";
CM_ SG_ 466 FCAM_ACC_AdtUpperJerkLimit "Upper jerk limit of acceleration";
CM_ SG_ 466 FCAM_ACC_AdtLowerJerkLimit "Lower jerk limit of acceleration";
CM_ SG_ 507 Driver_SeatbeltBuckleStatus "CVC_Driver_SeatbeltBuckleStatus";
CM_ SG_ 507 Passenger_SeatbeltBuckleStatus "CVC_Passenger_SeatbeltBuckleStatus";
CM_ SG_ 507 CVC_2nd_Dri_SeatbeltBuckleStatus "CVC_2nd_Dri_SeatbeltBuckleStatus";
CM_ SG_ 507 CVC_2nd_Pas_SeatbeltBuckleStatus "CVC_2nd_Pas_SeatbeltBuckleStatus";
CM_ SG_ 507 CVC_2nd_Mid_SeatbeltBuckleStatus "CVC_2nd_Mid_SeatbeltBuckleStatus";
CM_ SG_ 507 Driver_SeatbeltOccupantStatus "CVC_Driver_SeatbeltOccupantStatus";
CM_ SG_ 507 Passenger_SeatbeltOccupantStatus "CVC_Passenger_SeatbeltOccupantStatus";
CM_ SG_ 507 Dri_SeatbeltOccupantStatus_2nd "CVC_2nd_Dri_SeatbeltOccupantStatus";
CM_ SG_ 507 Pas_SeatbeltOccupantStatus_2nd "CVC_2nd_Pas_SeatbeltOccupantStatus";
CM_ SG_ 507 Mid_SeatbeltOccupantStatus_2nd "CVC_2nd_Mid_SeatbeltOccupantStatus";
CM_ SG_ 507 CVC_SBR_Chime_Req "Prompt sound request";
CM_ SG_ 507 CVC_SBR_Blinking_Req "Flashing request";
CM_ SG_ 522 ETG_Lift_Gate_Status "The working status of rear lift gate";
CM_ SG_ 522 ETG_Power_Latch_Status "The working status of power latch";
CM_ SG_ 522 ETG_Latch_Segment "The segment of power latch";
CM_ SG_ 522 ETG_Opening_Percentage "The opening percentage of rear lift gate";
CM_ SG_ 522 ETG_DSW_Status "The status of driver switch";
CM_ SG_ 522 ETG_GSW_Status "The status of gate switch";
CM_ SG_ 522 ETG_LTS_Status "The status of left touch sensor";
CM_ SG_ 522 ETG_RTS_Status "The status of right touch sensor";
CM_ SG_ 522 ETG_HAL_Status "The level status of latch's half switch";
CM_ SG_ 522 ETG_FUL_Status "The level status of latch's full switch";
CM_ SG_ 522 ETG_AJR_Status "The level status of latch's AJAR switch";
CM_ SG_ 522 ETG_NTL_Status "The level status of latch's neutral switch";
CM_ SG_ 522 ETG_ERR_Voltage "The error status of ETG voltage";
CM_ SG_ 522 ETG_ERR_Left_Motor "The error status of left lift motor";
CM_ SG_ 522 ETG_ERR_Right_Motor "The error status of right lift motor";
CM_ SG_ 522 ETG_ERR_Latch "The error status of power latch";
CM_ SG_ 522 ETG_ERR_Hall "The error status of hall signal";
CM_ SG_ 522 ETG_Lift_Motor_Stall "The stall protection status of lift motor";
CM_ SG_ 522 ETG_Lift_Motor_AntiPinch "The antipinch protection status of lift motor";
CM_ SG_ 522 ETG_Lift_Motor_Thermal "The thermal protection status of lift motor";
CM_ SG_ 522 ETG_Power_Latch_Thermal "The thermal protection status of power latch";
CM_ SG_ 522 ETG_Abuse_Protection "The abuse protection status of ETG";
CM_ SG_ 524 CRC_CVC_ODO "Checksum";
CM_ SG_ 524 ALIVE_CVC_ODO "Alive Counter";
CM_ SG_ 524 CVC_Odometer "Odometer information.";
CM_ SG_ 524 CVC_OdometerV "Validity of odometer information";
CM_ BO_ 525 "WCBS status";
CM_ SG_ 525 CRC_WCBS_STATUS "Checksum";
CM_ SG_ 525 ALIVE_WCBS_STATUS "Alive counter";
CM_ SG_ 525 ABSFailed "ABS Fault Status";
CM_ SG_ 525 ABSActive "Further details when which bit will be set are defined within attached Excel file: Functions_Interventions File is at the moment under review at Bosch WCBS side";
CM_ SG_ 525 WCBS_VehicleSpeed "Vehicle Speed";
CM_ SG_ 525 ESC_VehicleStandstill "Vehicle stationary detected";
CM_ SG_ 525 WCBS_VehicleSpeedValid "Vehicle Speed Status";
CM_ SG_ 525 ESC_VehicleHoldStat "Set if vehicle stationary for ACC is detected";
CM_ SG_ 525 ABS_EBDFailed "Signal from ABS/ABS to indicate EBD failure for driver";
CM_ SG_ 525 ABS_HAZActive "Emergency Stop Active";
CM_ SG_ 525 ABS_LowBrakeFluid "Detect the brake fluid level";
CM_ SG_ 525 EBDActive "Signal from ABS/ABS to indicate if EBD is activate or not";
CM_ SG_ 525 WCBS_Mileage "Mileage in cm";
CM_ SG_ 525 WCBS_Veh_DriveCondition "Driving Condition";
CM_ SG_ 533 CRC_BMS_Sts "Checksum";
CM_ SG_ 533 ALIVE_BMS_Sts "Rolling Counter";
CM_ SG_ 533 BMS_BatBalance_ERR "Battery Balance Error indicates Balancing switch is short or open";
CM_ SG_ 533 BMS_Balance_STS "BMS Balance Status";
CM_ SG_ 533 BMS_IGN_Sts "the ignition signal status (on/off)";
CM_ SG_ 533 BMS_HWCrash_Sts "Battery Pack Hardware Crash signal Status";
CM_ SG_ 533 BMS_HVIL_STS "The HVIL state of BMS";
CM_ SG_ 533 BMS_HVOnOff_STS "Status of the High Voltage";
CM_ SG_ 533 BMS_ERR_LEV "BMS requesting CVC to operate at the limited operating strategy (LOS)";
CM_ SG_ 533 BMS_SocActual_EST "Actual SOC";
CM_ SG_ 533 BMS_Sys_STS "BMS_Status(Self-test after BMS wake-up) BMS CVC";
CM_ SG_ 533 BMS_ISU_Status "Pack Insulation Status";
CM_ SG_ 533 BMS_SOH "BMS State Of Health";
CM_ SG_ 533 BMS_SOE "BMS State Of Enegy";
CM_ SG_ 533 BMS_HV_Sts "HV Status";
CM_ SG_ 533 BMS_Display_SOC "Display SOC";
CM_ SG_ 533 BMS_SOCE "State of certified energy";
CM_ SG_ 534 CRC_BMS_ChgParamReq "Checksum";
CM_ SG_ 534 ALIVE_BMS_ChgParamReq "Rolling Counter";
CM_ SG_ 534 BMS_RemainChargeTime "Remain Charge Time send to other ECU (XGW - IPC)";
CM_ SG_ 534 BMS_ChgVoltage_REQ "Charge Voltage Request";
CM_ SG_ 534 BMS_ChgCurrent_REQ "Charge Current Request";
CM_ SG_ 542 CVC_RearFogLampSts "Setting feedback to CAN of rear fog light";
CM_ SG_ 542 CVC_ExteriorLightSts "Request exterior light system to change to the mode set from user";
CM_ SG_ 542 CVC_FollowMeHomeSts "Feedback FMH setting status";
CM_ SG_ 542 CVC_WelcomeLightSts "Feedback Welcome light setitng status";
CM_ SG_ 542 CVC_FrontFogLampSts "Setting feedback to CAN of Front Fog lamp";
CM_ SG_ 560 CRC_WCBS_VAFS "check sum";
CM_ SG_ 560 ALIVE_WCBS_VAFS "Rolling counter";
CM_ SG_ 560 WCBS_BrkLampReq "Brake System Brake Lights Requested";
CM_ SG_ 560 EPB_SysWrnIndReq "Electric Park Brake System Warning Indication Request";
CM_ SG_ 560 EPB_SysStatIndReq "Electric Park Brake System Status Indication Request";
CM_ SG_ 560 EPB_SysDspMsgReq "Electric Park Brake System Display Message Request";
CM_ SG_ 560 EPB_Sts "Electric Park Brake Status";
CM_ SG_ 560 WCBS_TSMActive "Trailer mode Feedback";
CM_ SG_ 560 EPB_CDPActive "Indicate CDP active or not";
CM_ SG_ 560 EPB_Swch_Mafnc "EPB switch is malfunction or brakes are incoherent";
CM_ SG_ 560 WCBS_Avh_Available "AVH Availability";
CM_ SG_ 560 WCBS_AVH_DispMsg "Special message display during AVH";
CM_ SG_ 560 WCBS_AVH_Status "AVH status";
CM_ SG_ 560 WCBS_EPB_Fault "Park brake fault";
CM_ SG_ 560 WCBS_ROMActive "Roll Over Mitigation/Anti roll protection Active status";
CM_ SG_ 560 WCBS_ROMFailure "Roll Over Mitigation/Anti roll protection Failure status";
CM_ SG_ 560 WCBS_TrailerDetected "Auto detection of trailer by WCBS";
CM_ SG_ 560 WCBS_TSMFailure "Trailer Sway mitigation malfunction warning";
CM_ SG_ 560 WCBS_OnePedalAvailable "Single pedal mode available status";
CM_ SG_ 560 WCBS_BrkFricTqTotAtWhls "Total friction braking torque of the wheels";
CM_ SG_ 560 WCBS_HDCCtrlsts "HDC control status flag";
CM_ SG_ 560 WCBS_HDC_displayWarnMsg "HDC display warning message";
CM_ SG_ 560 WCBS_VehicleSteerSts "Vehicle steer status";
CM_ SG_ 560 WCBS_HDC_available "HDC Availability";
CM_ SG_ 560 WCBS_HDC_SwitchSts "HDC switch feedback status";
CM_ SG_ 560 WCBS_DTCFailure "Drag Torque Control Failure status";
CM_ SG_ 560 WCBS_TowMode_Feedback "Tow Mode Feedback";
CM_ SG_ 560 WCBS_SCM_available "SCM Availability";
CM_ SG_ 560 WCBS_OnePedal_Active "OnePedal Active flag in WCBS";
CM_ SG_ 560 WCBS_OnePedal_hold_state "whether OnePedal is on pressure hold state";
CM_ SG_ 560 WCBS_CDPFailSts "Detect the CDP function fault status";
CM_ SG_ 560 WCBS_CBC_Active "CBC Active";
CM_ SG_ 560 WCBS_CBC_Available "CBC Available";
CM_ SG_ 560 WCBS_SLS_Active "SLS Active";
CM_ SG_ 560 WCBS_SLS_Available "SLS Available";
CM_ SG_ 560 WCBS_TVBB_Active "TVBB Active";
CM_ SG_ 560 WCBS_TVBB_Available "TVBB Available";
CM_ SG_ 560 WCBS_BDW_Active "BDW Active";
CM_ SG_ 560 WCBS_BDW_Available "BDW Available";
CM_ SG_ 560 WCBS_SCMActive "Indicate SCM is active or not";
CM_ SG_ 561 CRC_DoorFLStatus "Checksum";
CM_ SG_ 561 ALIVE_DoorFLStatus "Alive counter";
CM_ SG_ 561 DOW_DoorAjarStatusRL "Left rear door slightly open state";
CM_ SG_ 561 DOW_DoorAjarStatusFL "Left front door slightly open state";
CM_ SG_ 565 CRC_TRM_STATUS "Checksum";
CM_ SG_ 565 ALIVE_TRM_STATUS "Alive counter";
CM_ SG_ 565 TRM_TowingDetected "Towing status ( reserved )";
CM_ SG_ 565 TRM_TrailerDetected "Trailer Detected status";
CM_ SG_ 562 CRC_CVC_Door_Status "Checksum";
CM_ SG_ 562 ALIVE_CVC_Door_Status "Alive counter";
CM_ SG_ 562 STAT_CDL_LED "Status of functional CDL button LED, value 2 represents implausible state";
CM_ SG_ 571 CRC_CVC_ACPE "Checksum";
CM_ SG_ 571 ALIVE_CVC_ACPE "Alive counter";
CM_ SG_ 571 CVC_ACPE_Actuator "CVC ACPE Actuator Feebdack";
CM_ SG_ 571 CVC_ACPE_PedalErrorEvent "CVC ACPE Pedal Error event";
CM_ SG_ 571 CVC_ACPE_Available_Flag "CVC ACPE functional availability";
CM_ SG_ 571 CVC_ACPE_Active_Flag "CVC ACPE Function active status";
CM_ SG_ 571 CVC_ACPE_HeathCheck "CVC ACPE function heath check";
CM_ SG_ 581 CRC_BMS_CellTemp "Checksum";
CM_ SG_ 581 ALIVE_BMS_CellTemp "Rolling Counter";
CM_ SG_ 581 BMS_ProbeNumMaxCellTemp "Probe Number of Max Cell Temperature";
CM_ SG_ 581 BMS_MinCellTemp "Min Cell Temperature";
CM_ SG_ 581 BMS_ProbeNumMinCellTemp "Probe Number of Min Cell Temperature";
CM_ SG_ 581 BMS_PackTemp "Pack Temperature";
CM_ SG_ 581 BMS_MaxCellTemp "Max Cell Temperature";
CM_ SG_ 581 BMS_MaxMinDiffCellTemp "max and min cell temperature differences";
CM_ SG_ 584 DOW_DoorAjarStatusRR "Ajar Door Rear Right Status";
CM_ SG_ 584 DOW_DoorAjarStatusFR "Ajar Door Front Right Status";
CM_ SG_ 624 WCBS_Fault_Status "Braking system fault status";
CM_ SG_ 624 WCBS_IBS_Sys_Fault_Sts "IBS sysstem fault status";
CM_ SG_ 624 WCBS_BrkPedalPct "The percent of brake pedal";
CM_ SG_ 624 WCBS_BrkPedalTravel "brake pedal travel";
CM_ SG_ 624 WCBS_BrkPedalValid "Validity of Brake pedal signals";
CM_ SG_ 624 WCBS_DiagMode "Diagnosis mode";
CM_ SG_ 624 WCBS_RollerBenchMode "Rollerbench mode active";
CM_ SG_ 624 WCBSActive "Active when any brake pressure build > threshold";
CM_ SG_ 624 WCBS_EOL_NotDone "EOL configuration is not completely done";
CM_ SG_ 624 STAT_DSC "Dynamic Stability Control status(reserved)";
CM_ SG_ 624 WCBS_BLAFlt "WCBS need to have SM implemented to detect any fault which can lead to failure in WCBS not triggering brake light activation. Part of WCBS_FSR016";
CM_ SG_ 624 FBW_WarningSts "Brake disc fading alarm status due to high temperature";
CM_ SG_ 624 Brake_Disc_Temp_FL "Estimated Brake disc temperature FL (debug only)";
CM_ SG_ 624 Brake_Disc_Temp_FR "Estimated Brake disc temperature FR (debug only)";
CM_ SG_ 624 Brake_Disc_Temp_RL "Estimated Brake disc temperature RL (debug only)";
CM_ SG_ 624 Brake_Disc_Temp_RR "Estimated Brake disc temperature RR (debug only)";
CM_ SG_ 624 WCBS_BrakesystemFailSts "Brake system Fail status";
CM_ SG_ 662 POD_DCDC_InputHV "Input Voltage";
CM_ SG_ 662 PDU_DCDC_StsCtrl "DCDC Control Status to CVC";
CM_ SG_ 662 PDU_DCDC_OutputCurrent "Output Current";
CM_ SG_ 662 PDU_DCDC_OutputVolt "Output Voltage";
CM_ SG_ 674 DrvSeatMsgModeStat "Driver's seat information mode status";
CM_ SG_ 674 LSSM_APumpFail "Driver's seat pump malfunction";
CM_ SG_ 674 DrvSeatMsgStrLvlStat "Driver's seat message intensity level status";
CM_ SG_ 674 PassSeatMsgModeStat "Passenger seat information mode status";
CM_ SG_ 674 LSSM_BPumpFail "Passenger seat pump malfunction";
CM_ SG_ 674 PassSeatMsgStrLvlStat "Passenger seat message intensity level status";
CM_ SG_ 674 DrvSeatMsgModeStat_sec "Second row driver's side seat massage mode status";
CM_ SG_ 674 LSSM_CPumpFail_sec_Drv "Second row driver's seat pump malfunction";
CM_ SG_ 674 DrvSeatMsgStrLvlStat_sec "Second row driver's seat massage intensity level status";
CM_ SG_ 674 PsSeatMsgModeStat_sec "Second row passenger side seat massage mode status";
CM_ SG_ 674 LSSM_CPumpFail_sec_Ps "Second row passenger seat pump malfunction";
CM_ SG_ 674 PsSeatMsgStrLvlStat_sec "Second row passenger side seat massage intensity level status";
CM_ SG_ 746 InteriorTemperature "Interior Temprature value from LIN";
CM_ SG_ 746 CVC_SW_Versions "CVC software version";
CM_ SG_ 746 CVC_Fan_Sts "CVC control fan status";
CM_ SG_ 746 CVC_DCChgPosTemp "The Positive Temperature of DC Charging";
CM_ SG_ 746 CVC_DCChgNegTemp "The Negative Temperature of DC Charging";
CM_ SG_ 746 CVC_ACChgLTerminalTemp "Temperature of AC Charging L terminal";
CM_ SG_ 746 CVC_ACChgNTerminalTemp_Reserve "Temperature of AC Charging  N terminal_Reserve";
CM_ SG_ 746 CVC_EdrivePump_Sts "Electric drive water pump working status";
CM_ SG_ 746 CVC_BatPump_Sts "Battery water pump working status";
CM_ SG_ 746 CVC_ActiveHeatingPower "Active heating power for PTC in battery pre-heat for debugging";
CM_ SG_ 760 DISP_HR "The signal / parameter indicates the current hour.";
CM_ SG_ 760 DISP_MN "The signal / parameter indicates the current minute.";
CM_ SG_ 760 DISP_SEC "The signal / parameter indicates the current second.";
CM_ SG_ 760 DISP_DATE_DAY "The signal / parameter indicates the current day.";
CM_ SG_ 760 DISP_DATE_MON "The signal / parameter indicates the current month.";
CM_ SG_ 760 DISP_DATE_WDAY "The signal   parameter indicates the current day of the week.";
CM_ SG_ 760 DISP_DATE_YR "The signal / parameter indicates the current year.";
CM_ SG_ 760 ST_DISP_CTI_DATE "The signal / parameter indicates the state of the switch summer winter time.";
CM_ SG_ 768 CVC_STAT_SyncClimateZone "Status dual clima automatic";
CM_ SG_ 768 CVC_STAT_Auto "Status activation of auto mode";
CM_ SG_ 768 CVC_STAT_Aircondition "Aircondition status";
CM_ SG_ 768 CVC_STAT_IonButton "Status if the ionisator is active";
CM_ SG_ 768 CVC_STAT_MaxAc "Status activation of MAX AC mode";
CM_ SG_ 768 CVC_STAT_ClimateOnOff "Status On  Off button for clima";
CM_ SG_ 768 CVC_STAT_FanSpeed "Blower settings/Fan Speed for climate system";
CM_ SG_ 768 CVC_STAT_RecircFlap "Recirculation flap status, 100% fresh air, 0% recirculation mode";
CM_ SG_ 768 CVC_STAT_AirDistributionMode "Request for flap position";
CM_ SG_ 768 CVC_STAT_Defrost "Status activation of Defrost mode";
CM_ SG_ 768 CVC_STAT_PTC_Heater "CVC status for PTC heater";
CM_ SG_ 768 CVC_STAT_TempDriver "CVC status for temperature regulationr driver (Display Temperature)";
CM_ SG_ 768 CVC_STAT_TempPassenger "CVC status for temperature regulation  passenger(Display Temperature)";
CM_ SG_ 768 CVC_CoolSysWarnLvl "Cooling system warning level";
CM_ SG_ 777 CPD_Warn_Initial_Start "CPD initial warning begins";
CM_ SG_ 777 CPD_Warn_Initial_End "CPD initial warning ends";
CM_ SG_ 777 CPD_Warn_Escalated_Start "CPD upgrade warning begins";
CM_ SG_ 777 CPD_Warn_Escalated_End "CPD upgrade warning ends";
CM_ SG_ 777 CPD_Warn_Cancel "CPD warning cancelled";
CM_ SG_ 778 CVC_DKCU_PhoneLocationReq "CVC request to DKCU for Device presence confirmation";
CM_ SG_ 779 CVC_DKCU_Temp_Intervention_Fdbk "CVC received intervention message and started notifying BCM to start the in car air conditioning system";
CM_ SG_ 779 CVC_DKCU_Remote_Phone_Interventi "CVC received an intervention message and began to execute the phone system dialing actionCVC";
CM_ SG_ 787 CRC_POD_OBC_StatusCharger1 "Check sum 0x313";
CM_ SG_ 787 ALIVE_POD_OBC_StatusCharger1 "Alive counter 0x313";
CM_ SG_ 787 POD_GTW_statusOBC "OBC status";
CM_ SG_ 787 POD_GTW_OBC_Max_Current_Out "Max DC current OBC able to output";
CM_ SG_ 787 POD_GTW_iDCOutput "GTW measured output current on OBC output";
CM_ SG_ 787 POD_GTW_vDCOutput "GTW measured bus voltage";
CM_ SG_ 803 CRC_POD_OBC_StatusCharger2 "Check sum 0x323";
CM_ SG_ 803 ALIVE_POD_OBC_StatusCharger2 "Alive counter 0x323";
CM_ SG_ 803 POD_GW_PhaseACInput "OBC Phase's Type value";
CM_ SG_ 803 POD_GW_iACInput "GTW measured current on AC input";
CM_ SG_ 803 POD_vACInput "GTW measured voltage on AC input";
CM_ SG_ 803 POD_tempACCharger "Reported AC Charger/OBC temperauture";
CM_ SG_ 803 POD_tempColdplate "Coolant temperature into the CPDU";
CM_ SG_ 805 BCMFL_STAT_SteerPosX "Adjustment of the X position of the steering wheel";
CM_ SG_ 805 BCMFL_STAT_SteerPosY "Adjustment of the Y position of the steering wheel";
CM_ SG_ 805 Steering_Wheel_Telescope_Positio "Adjustment of the telescopic position of the steering wheel";
CM_ SG_ 805 Steering_Wheel_Convenience_Acces "Convenient access status of steering wheel";
CM_ SG_ 805 Steering_Wheel_Angle_Status "Steering wheel angle adjustment";
CM_ SG_ 805 Steering_HeatingControlFdbk "Steering wheel heating status";
CM_ SG_ 805 BCMFL_STS_SteerAdjust "Steering wheel adjustment state";
CM_ SG_ 805 SWHC_SterringWheelHeatFaultReaso "Reason for steering wheel heating malfunction";
CM_ SG_ 805 Steer_ProfileSave_Tips "Prompt for successful saving of current steering wheel posture";
CM_ SG_ 805 Steer_ColUpDown_Sts "Comfortable steering wheel up and down movement state";
CM_ SG_ 805 Steer_ElecAdjust_SettingSts "Steering wheel electric adjustment setting status";
CM_ BO_ 815 "WCBS_Info_Flag";
CM_ SG_ 815 CRC_WCBS_ADAS_Info "Checksum";
CM_ SG_ 815 ALIVE_WCBS_ADAS_Info "Alive counter";
CM_ SG_ 815 WCBS_ACC_Available_Flag "ACC available or not";
CM_ SG_ 815 WCBS_ACC_Deceleration_Flag "Deceleration flag for ACC";
CM_ SG_ 815 WCBS_ACC_Acceleration_Flag "Acceleration flag for ACC";
CM_ SG_ 815 WCBS_RAEB_Active_Flag "RAEB active or not";
CM_ SG_ 815 WCBS_RAEB_Available_Flag "RAEB available or not";
CM_ SG_ 815 WCBS_AEB_Active_Flag "AEB active or not";
CM_ SG_ 815 WCBS_AEB_Available_Flag "AEB available or not";
CM_ SG_ 815 WCBS_ACC_DriverOverride "Information of Driver pedal override.";
CM_ SG_ 815 WCBS_ACC_TargetWheel_Torque "Target wheel torque";
CM_ SG_ 815 WCBS_ACC_WheelTrq_Active "Target wheel torque effectiveness";
CM_ SG_ 838 CRC_POD_StatusDCDC2 "Check sum";
CM_ SG_ 838 ALIVE_POD_StatusDCDC2 "Alive counter";
CM_ SG_ 838 POD_vDCInput "POD measured DC bus voltage at DCDC input";
CM_ SG_ 838 POD_iDCDCOutput "POD reported 12V current";
CM_ SG_ 838 POD_vDCDCOutput "POD reported 12V voltage";
CM_ SG_ 843 CRC_EVCC_EVSE_Info_1 "Checksum";
CM_ SG_ 843 ALIVE_EVCC_EVSE_Info_1 "Alive counter";
CM_ SG_ 843 EVSE_DC_Stt "Debug) Indicate DC-EVSE internal state, element DC_EVSEStatusCode as definded in annex C.6, ISO 15118- 2:2016.";
CM_ SG_ 843 EVSE_CtrlPilot_PWM_value "(Debug) Indicate the PWM value of Control Pilot.";
CM_ SG_ 843 EVSE_CtrlPilot_STS "(Debug) Indicate Control Pilot state, as definded in Table A.4, IEC 61851-1:2017";
CM_ SG_ 843 EVSE_IsolationLvl "(Debug) Indicate EVSE isolation level, element EVSEIsolationStatus as definded in annex C.6, ISO 15118- 2:2016.";
CM_ SG_ 843 EVSE_VehChgComm_STAT "(Debug) Indicate vehicle charging communication state.";
CM_ SG_ 843 EVSE_ResponseCode "(Debug) Indicate EVSE response code, element responseCode as definded in annex C.6, ISO 15118-2:2016.";
CM_ SG_ 843 EVSE_AC_MaxLineCur "The information sent from EVSE to indicate the maximum line current per phase the EV can draw. Element EVSEMaxCurrent as definded in ISO 15118-2:2016.";
CM_ SG_ 847 CRC_EVCC_EVSE_Info_2 "Checksum";
CM_ SG_ 847 ALIVE_EVCC_EVSE_Info_2 "Alive counter";
CM_ SG_ 847 EVSE_DC_MaxChgCur "(Debug) The information sent from EVSE to indicate the maximum DC current the EVSE can deliver. Element EVSEMaximumCurrentLimit as definded in ISO 15118-2:2016.";
CM_ SG_ 847 EVSE_DC_MaxChgPwr "The information was sent from EVSE to indicate the maximum DC power the EVSE can deliver. Element EVSEMaximumPowerLimit as definded in ISO 15118-2:2016.";
CM_ SG_ 847 EVSE_DC_ActCurOut "(Debug) The information was sent from EVSE to indicate the present output current of the EVSE. Element EVSEPresentCurrent as definded in ISO 15118-2:2016.";
CM_ SG_ 852 CRC_CVC_FCAM_req "Checksum";
CM_ SG_ 852 ALIVE_CVC_FCAM_req "Alive Counter";
CM_ SG_ 852 CVC_RAEB_Mode "RAEB mode select";
CM_ SG_ 852 CVC_LA_AudWarning "Setting Audible warning for LA On off";
CM_ SG_ 852 CVC_BSD_On "BSD On off";
CM_ SG_ 852 CVC_BSD_sens "Radar sensitivity setting";
CM_ SG_ 852 CVC_BSD_AudWarning "Setting Audible warning for BSD On off";
CM_ SG_ 852 CVC_RCTA_On "RCTA On off";
CM_ SG_ 852 CVC_RCTA_sens "RCTA Sensitivity (Early   Normal   Late)";
CM_ SG_ 852 CVC_PA_On "PA On off";
CM_ SG_ 852 CVC_AHB_On "AHB On off";
CM_ SG_ 852 CVC_IA_Mode "IA mode select";
CM_ SG_ 852 CVC_TSR_Mode "TSR Mode selection";
CM_ SG_ 852 CVC_DOW_Mode "Door Open Warning Mode select";
CM_ SG_ 852 CVC_AHB_sens "AHB Sensitivity (Early   Normal   Late)";
CM_ SG_ 852 CVC_FCW_sens "FCW Sensitivity";
CM_ SG_ 852 CVC_LA_Mode "Lane Assistance Mode select";
CM_ SG_ 852 CVC_FCW_Mode "FCW ABE mode select";
CM_ SG_ 852 CVC_SET_TSR_AudWarn "TSR Audible Warning On Off";
CM_ SG_ 852 CVC_SET_TSR_SLAert "TSR Speed Limit Alert select";
CM_ SG_ 852 CVC_LA_sens "LA Sensitivity (Early   Normal   Late)";
CM_ SG_ 852 CVC_AEB_Mode "AEB Confirmation";
CM_ SG_ 852 CVC_ESA_ON "ESA function on/off";
CM_ SG_ 852 CVC_ELKA_ON "ELKA function ON/OFF";
CM_ SG_ 852 CVC_ALC_ON "Turn ALCA on/off";
CM_ SG_ 852 CVC_DashCam_Setting "Enable settings";
CM_ SG_ 852 CVC_LKA_LDW_Haptic_Mode "LKA Haptic Settings Request";
CM_ SG_ 852 CVC_ELK_Haptic_Mode "ELK Haptic Settings Request";
CM_ SG_ 852 CVC_TSR_Haptic_Mode "TSR Haptic Settings Request";
CM_ SG_ 852 CVC_SLW_Mode_Req "Speed Limit Warning ON/OFF Request";
CM_ SG_ 852 CVC_HWA_Mode "HWA setting";
CM_ SG_ 852 CVC_ISA_ON "Turn ISA On/ Off";
CM_ SG_ 852 CVC_Option_feed "Feedback on MHU functional options";
CM_ SG_ 852 CVC_ALCA_LaneChange_confir "ALCA lane change confirmation";
CM_ SG_ 852 CVC_FCTB_Mode "FCTB Mode selection in MHU";
CM_ SG_ 852 CVC_RCTB_Mode "RCTB Mode selection in MHU";
CM_ SG_ 852 CVC_ACPE_Setting "ACPE  Sens Mode selection in MHU";
CM_ SG_ 852 CVC_ACPE_Sens "ACPE Mode selection in MHU";
CM_ SG_ 852 CVC_SVM_Setting_Guideline "SVM Dynamic guideline setting";
CM_ SG_ 852 CVC_SVM_Setting_ObjOverlay "SVM 3D Obstacle overrlay setting";
CM_ SG_ 852 CVC_SVM_Setting_TrailerGuideline "SVM Trailer dynamic guideline setting";
CM_ SG_ 852 CVC_SVM_Setting_MaxDoorOverlay "SVM display Door openning overlay setting";
CM_ SG_ 852 CVC_SVM_TransparentRequest "SVM Tranparent Request";
CM_ SG_ 852 CVC_SVM_Setting_BlindSpotView "SVM Auto Blindspot camera setting";
CM_ SG_ 852 CVC_ALC_Recommend "CVC setting for ALC recommendation";
BA_DEF_ BO_  "DiagRequest" ENUM  "No","Yes";
BA_DEF_ BO_  "DiagResponse" ENUM  "No","Yes";
BA_DEF_ BO_  "DiagState" ENUM  "No","Yes";
BA_DEF_ BO_  "GenMsgCycleTime" INT 0 65535;
BA_DEF_ BO_  "GenMsgCycleTimeFast" INT 0 65535;
BA_DEF_ BO_  "GenMsgDelayTime" INT 0 65535;
BA_DEF_ BO_  "GenMsgILSupport" ENUM  "No","Yes";
BA_DEF_ BO_  "GenMsgNrOfRepetition" INT 0 65535;
BA_DEF_ BO_  "GenMsgSendType" ENUM  "Cyclic","NoMsgSendType","NotUsed","NotUsed","NotUsed","NotUsed","NotUsed","IfActive","NoMsgSendType","NotUsed";
BA_DEF_ BO_  "NmAsrMessage" ENUM  "No","Yes";
BA_DEF_ BO_  "NmMessage" ENUM  "No","Yes";
BA_DEF_ SG_  "GenSigSendType" ENUM  "Cyclic","NoSigSendType","OnWriteWithRepetition","OnChange","OnChangeWithRepetition","IfActive","IfActiveWithRepetition","OnWrite","NotUsed","NotUsed","NotUsed","NotUsed","NotUsed";
BA_DEF_ SG_  "GenSigStartValue" INT 0 2147483647;
BA_DEF_ SG_  "GenSigTimeoutTime_ALL" INT 0 65535;
BA_DEF_ SG_  "InvalidValue" STRING ;
BA_DEF_ SG_  "GenSigInactiveValue" INT 0 2147483647;
BA_DEF_ BU_  "ILUsed" ENUM  "No","Yes";
BA_DEF_ BU_  "NmStationAddress" HEX 0 0;
BA_DEF_ BU_  "Address" HEX 0 255;
BA_DEF_ BU_  "NmAsrCanMsgReducedTime" INT 320 640;
BA_DEF_ BU_  "NmAsrNode" ENUM  "No","Yes";
BA_DEF_ BU_  "NmAsrNodeIdentifier" HEX 0 255;
BA_DEF_ BU_  "TpSTMin" INT 0 255;
BA_DEF_  "Baudrate" INT 1000 1000000;
BA_DEF_  "BaudRateCANFD" FLOAT 1000 10000000;
BA_DEF_ BO_  "VFrameFormat" ENUM  "StandardCAN","ExtendedCAN","reserved","J1939PG","reserved","reserved","reserved","reserved","reserved","reserved","reserved","reserved","reserved","reserved","StandardCAN_FD","ExtendedCAN_FD";
BA_DEF_ BO_  "CANFD_BRS" ENUM  "0","1";
BA_DEF_  "DBName" STRING ;
BA_DEF_  "BusType" STRING ;
BA_DEF_  "Manufacturer" STRING ;
BA_DEF_  "NmAsrBaseAddress" HEX 0 2047;
BA_DEF_  "NmAsrCanMsgCycleTime" INT 0 65535;
BA_DEF_  "NmAsrMessageCount" INT 1 256;
BA_DEF_  "NmAsrRepeatMessageTime" INT 0 65535;
BA_DEF_  "NmAsrTimeoutTime" INT 0 65535;
BA_DEF_  "NmAsrWaitBusSleepTime" INT 0 65535;
BA_DEF_  "NmType" STRING ;
BA_DEF_ SG_  "SystemSignalLongSymbol" STRING ;
BA_DEF_ BO_  "SystemMessageLongSymbol" STRING ;
BA_DEF_DEF_  "DiagRequest" "No";
BA_DEF_DEF_  "DiagResponse" "No";
BA_DEF_DEF_  "DiagState" "No";
BA_DEF_DEF_  "GenMsgCycleTime" 0;
BA_DEF_DEF_  "GenMsgCycleTimeFast" 0;
BA_DEF_DEF_  "GenMsgDelayTime" 0;
BA_DEF_DEF_  "GenMsgILSupport" "Yes";
BA_DEF_DEF_  "GenMsgNrOfRepetition" 0;
BA_DEF_DEF_  "GenMsgSendType" "Cyclic";
BA_DEF_DEF_  "NmAsrMessage" "No";
BA_DEF_DEF_  "NmMessage" "No";
BA_DEF_DEF_  "GenSigSendType" "Cyclic";
BA_DEF_DEF_  "GenSigStartValue" 0;
BA_DEF_DEF_  "GenSigTimeoutTime_ALL" 0;
BA_DEF_DEF_  "InvalidValue" "";
BA_DEF_DEF_  "GenSigInactiveValue" 0;
BA_DEF_DEF_  "ILUsed" "Yes";
BA_DEF_DEF_  "NmStationAddress" 0;
BA_DEF_DEF_  "Address" 0;
BA_DEF_DEF_  "NmAsrCanMsgReducedTime" 320;
BA_DEF_DEF_  "NmAsrNode" "No";
BA_DEF_DEF_  "NmAsrNodeIdentifier" 0;
BA_DEF_DEF_  "TpSTMin" 20;
BA_DEF_DEF_  "Baudrate" 500000;
BA_DEF_DEF_  "BaudRateCANFD" 2000000;
BA_DEF_DEF_  "VFrameFormat" "StandardCAN_FD";
BA_DEF_DEF_  "CANFD_BRS" "1";
BA_DEF_DEF_  "DBName" "";
BA_DEF_DEF_  "BusType" "";
BA_DEF_DEF_  "Manufacturer" "LaunchDesign";
BA_DEF_DEF_  "NmAsrBaseAddress" 1280;
BA_DEF_DEF_  "NmAsrCanMsgCycleTime" 640;
BA_DEF_DEF_  "NmAsrMessageCount" 128;
BA_DEF_DEF_  "NmAsrRepeatMessageTime" 3200;
BA_DEF_DEF_  "NmAsrTimeoutTime" 2000;
BA_DEF_DEF_  "NmAsrWaitBusSleepTime" 1500;
BA_DEF_DEF_  "NmType" "NmAsr";
BA_DEF_DEF_  "SystemSignalLongSymbol" "";
BA_DEF_DEF_  "SystemMessageLongSymbol" "";
BA_ "Manufacturer" "VinFast";
BA_ "BusType" "CAN FD";
BA_ "DBName" "ICAN";
BA_ "NmStationAddress" BU_ CVC_I 2;
BA_ "Address" BU_ CVC_I 2;
BA_ "NmAsrNodeIdentifier" BU_ CVC_I 2;
BA_ "NmAsrNode" BU_ CVC_I 1;
BA_ "NmStationAddress" BU_ MHU 4;
BA_ "Address" BU_ MHU 4;
BA_ "NmAsrNodeIdentifier" BU_ MHU 4;
BA_ "NmAsrNode" BU_ MHU 1;
BA_ "NmStationAddress" BU_ TBOX 10;
BA_ "Address" BU_ TBOX 10;
BA_ "NmAsrNodeIdentifier" BU_ TBOX 10;
BA_ "NmAsrNode" BU_ TBOX 1;
BA_ "NmAsrNodeIdentifier" BU_ FCAM_I 22;
BA_ "Address" BU_ FCAM_I 22;
BA_ "NmStationAddress" BU_ FCAM_I 22;
BA_ "NmStationAddress" BU_ MRR 37;
BA_ "Address" BU_ MRR 37;
BA_ "NmAsrNodeIdentifier" BU_ MRR 37;
BA_ "NmAsrNodeIdentifier" BU_ SRR_RL 55;
BA_ "Address" BU_ SRR_RL 55;
BA_ "NmStationAddress" BU_ SRR_RL 55;
BA_ "NmAsrNodeIdentifier" BU_ SRR_RR 38;
BA_ "Address" BU_ SRR_RR 38;
BA_ "NmStationAddress" BU_ SRR_RR 38;
BA_ "NmAsrNodeIdentifier" BU_ SRR_FL 53;
BA_ "Address" BU_ SRR_FL 53;
BA_ "NmStationAddress" BU_ SRR_FL 53;
BA_ "NmAsrNodeIdentifier" BU_ SRR_FR 52;
BA_ "Address" BU_ SRR_FR 52;
BA_ "NmStationAddress" BU_ SRR_FR 52;
BA_ "NmAsrNodeIdentifier" BU_ ADCU_I 64;
BA_ "Address" BU_ ADCU_I 64;
BA_ "NmStationAddress" BU_ ADCU_I 64;
BA_ "NmStationAddress" BU_ AMP 5;
BA_ "Address" BU_ AMP 5;
BA_ "NmAsrNodeIdentifier" BU_ AMP 5;
BA_ "NmAsrNode" BU_ AMP 1;
BA_ "NmAsrNodeIdentifier" BU_ HUD 13;
BA_ "Address" BU_ HUD 13;
BA_ "NmStationAddress" BU_ HUD 13;
BA_ "GenMsgCycleTime" BO_ 133 20;
BA_ "GenMsgCycleTime" BO_ 169 100;
BA_ "GenMsgCycleTime" BO_ 201 10;
BA_ "GenMsgCycleTime" BO_ 203 10;
BA_ "GenMsgCycleTime" BO_ 217 40;
BA_ "GenMsgCycleTime" BO_ 258 100;
BA_ "GenMsgCycleTime" BO_ 260 100;
BA_ "GenMsgCycleTime" BO_ 262 100;
BA_ "GenMsgCycleTime" BO_ 264 50;
BA_ "GenMsgCycleTime" BO_ 265 20;
BA_ "GenMsgCycleTimeFast" BO_ 265 10;
BA_ "GenMsgNrOfRepetition" BO_ 265 3;
BA_ "GenMsgCycleTime" BO_ 266 100;
BA_ "GenMsgCycleTime" BO_ 180 100;
BA_ "GenMsgCycleTime" BO_ 530 100;
BA_ "GenMsgCycleTimeFast" BO_ 530 10;
BA_ "GenMsgNrOfRepetition" BO_ 530 3;
BA_ "GenMsgCycleTime" BO_ 267 100;
BA_ "GenMsgCycleTime" BO_ 273 10;
BA_ "GenMsgCycleTime" BO_ 274 100;
BA_ "GenMsgCycleTime" BO_ 279 20;
BA_ "GenMsgCycleTime" BO_ 289 20;
BA_ "GenMsgCycleTime" BO_ 290 20;
BA_ "GenMsgCycleTime" BO_ 291 500;
BA_ "GenMsgCycleTime" BO_ 292 20;
BA_ "GenMsgCycleTime" BO_ 293 500;
BA_ "GenMsgCycleTime" BO_ 306 20;
BA_ "GenMsgCycleTime" BO_ 311 20;
BA_ "GenMsgCycleTime" BO_ 357 50;
BA_ "GenMsgCycleTime" BO_ 372 20;
BA_ "GenMsgCycleTime" BO_ 382 10;
BA_ "GenMsgCycleTime" BO_ 466 20;
BA_ "GenMsgCycleTime" BO_ 507 200;
BA_ "GenMsgCycleTime" BO_ 522 100;
BA_ "GenMsgCycleTime" BO_ 524 100;
BA_ "GenMsgCycleTime" BO_ 525 20;
BA_ "GenMsgCycleTime" BO_ 533 50;
BA_ "GenMsgCycleTime" BO_ 534 50;
BA_ "GenMsgCycleTime" BO_ 542 100;
BA_ "GenMsgCycleTime" BO_ 560 40;
BA_ "GenMsgCycleTime" BO_ 561 20;
BA_ "GenMsgCycleTime" BO_ 565 100;
BA_ "GenMsgCycleTime" BO_ 562 20;
BA_ "GenMsgCycleTime" BO_ 571 200;
BA_ "GenMsgCycleTimeFast" BO_ 571 20;
BA_ "GenMsgNrOfRepetition" BO_ 571 2;
BA_ "GenMsgCycleTime" BO_ 581 20;
BA_ "GenMsgCycleTime" BO_ 584 20;
BA_ "GenMsgCycleTime" BO_ 624 20;
BA_ "GenMsgCycleTime" BO_ 662 100;
BA_ "GenMsgCycleTime" BO_ 674 80;
BA_ "GenMsgCycleTime" BO_ 746 200;
BA_ "GenMsgCycleTime" BO_ 760 1000;
BA_ "GenMsgSendType" BO_ 768 1;
BA_ "GenMsgCycleTime" BO_ 777 200;
BA_ "GenMsgCycleTimeFast" BO_ 777 20;
BA_ "GenMsgNrOfRepetition" BO_ 777 3;
BA_ "GenMsgCycleTime" BO_ 778 200;
BA_ "GenMsgCycleTimeFast" BO_ 778 20;
BA_ "GenMsgNrOfRepetition" BO_ 778 3;
BA_ "GenMsgCycleTime" BO_ 779 100;
BA_ "GenMsgCycleTimeFast" BO_ 779 20;
BA_ "GenMsgNrOfRepetition" BO_ 779 3;
BA_ "GenMsgCycleTime" BO_ 787 100;
BA_ "GenMsgCycleTime" BO_ 803 100;
BA_ "GenMsgCycleTime" BO_ 805 100;
BA_ "GenMsgCycleTime" BO_ 815 20;
BA_ "GenMsgCycleTime" BO_ 838 100;
BA_ "GenMsgCycleTime" BO_ 843 100;
BA_ "GenMsgCycleTime" BO_ 847 100;
BA_ "GenMsgCycleTime" BO_ 852 50;
BA_ "GenSigTimeoutTime_ALL" SG_ 133 CRC_ACU_CRASH_INFO 200;
BA_ "InvalidValue" SG_ 133 ALIVE_ACU_CRASH_INFO "Fh";
BA_ "GenSigTimeoutTime_ALL" SG_ 133 ALIVE_ACU_CRASH_INFO 200;
BA_ "InvalidValue" SG_ 133 ACU_Crash_Sts "3h";
BA_ "GenSigTimeoutTime_ALL" SG_ 133 ACU_Crash_Sts 200;
BA_ "InvalidValue" SG_ 133 ACU_Airbag_Deployment_Status "3h";
BA_ "GenSigTimeoutTime_ALL" SG_ 133 ACU_Airbag_Deployment_Status 200;
BA_ "InvalidValue" SG_ 133 ACU_Crash_Intensity "7h";
BA_ "GenSigTimeoutTime_ALL" SG_ 133 ACU_Crash_Intensity 200;
BA_ "InvalidValue" SG_ 133 ACU_Front_Crash "3h";
BA_ "GenSigTimeoutTime_ALL" SG_ 133 ACU_Front_Crash 200;
BA_ "InvalidValue" SG_ 133 ACU_DriverSide_Crash "3h";
BA_ "GenSigTimeoutTime_ALL" SG_ 133 ACU_DriverSide_Crash 200;
BA_ "InvalidValue" SG_ 133 ACU_PassSide_Crash "3h";
BA_ "GenSigTimeoutTime_ALL" SG_ 133 ACU_PassSide_Crash 200;
BA_ "InvalidValue" SG_ 133 ACU_Rear_Crash "3h";
BA_ "GenSigTimeoutTime_ALL" SG_ 133 ACU_Rear_Crash 200;
BA_ "InvalidValue" SG_ 133 ACU_Rollover_Crash "3h";
BA_ "GenSigTimeoutTime_ALL" SG_ 133 ACU_Rollover_Crash 200;
BA_ "InvalidValue" SG_ 169 ALIVE_BCMFL_Temperature "Fh";
BA_ "InvalidValue" SG_ 169 BCMFL_AmbientTemp "FFh";
BA_ "InvalidValue" SG_ 169 BCMFL_CabinHeat_TempSensor "FFh";
BA_ "InvalidValue" SG_ 169 BCMFL_AmbientTempSts "3h";
BA_ "InvalidValue" SG_ 169 BCMFL_CoolantTemp_EDS_In_Sts "3h";
BA_ "InvalidValue" SG_ 169 BCMFL_CoolantTemp_EDS_Out_Sts "3h";
BA_ "InvalidValue" SG_ 169 BCMFL_CoolantTemp_LTR_Out_Sts "3h";
BA_ "InvalidValue" SG_ 169 BCMFL_ACLowSideTemperatureSts "3h";
BA_ "InvalidValue" SG_ 169 BCMFL_ACLowSidePressureSts "3h";
BA_ "InvalidValue" SG_ 169 BCMFL_ACHighSideTemperatureSts "3h";
BA_ "InvalidValue" SG_ 169 BCMFL_ACHighSidePressureSts "3h";
BA_ "InvalidValue" SG_ 169 BCMFL_CoolantTemp_HtrCore_In_Sts "3h";
BA_ "InvalidValue" SG_ 169 BCMFL_Refrigerant_Temp_Sensor_St "3h";
BA_ "SystemSignalLongSymbol" SG_ 169 BCMFL_Refrigerant_Temp_Sensor_St "BCMFL_Refrigerant_Temp_Sensor_Sts";
BA_ "InvalidValue" SG_ 169 BCMFL_PT_Sensor1_Pressure_Sts "3h";
BA_ "InvalidValue" SG_ 169 BCMFL_PT_Sensor2_Pressure_Sts "3h";
BA_ "InvalidValue" SG_ 201 ALIVE_FMCU_Status "Fh";
BA_ "InvalidValue" SG_ 201 FMCU_MotorTq "FFFFh";
BA_ "GenSigStartValue" SG_ 201 FMCU_MotorTq 4000;
BA_ "InvalidValue" SG_ 201 FMCU_MotorSpd "FFFFh";
BA_ "GenSigStartValue" SG_ 201 FMCU_MotorSpd 20000;
BA_ "InvalidValue" SG_ 201 FMCU_StsMCUFault "Fh";
BA_ "InvalidValue" SG_ 201 FMCU_MotorSpdSts "1h";
BA_ "InvalidValue" SG_ 201 FMCU_MotorTqSts "1h";
BA_ "InvalidValue" SG_ 201 FMCU_CVC_CtrlMode "Fh";
BA_ "InvalidValue" SG_ 201 FMCU_CVC_StsMode "Fh";
BA_ "InvalidValue" SG_ 203 ALIVE_RMCU_Status "Fh";
BA_ "GenSigStartValue" SG_ 203 RMCU_MotorTq 4000;
BA_ "GenSigStartValue" SG_ 203 RMCU_MotorSpd 20000;
BA_ "InvalidValue" SG_ 203 RMCU_StsMCUFault "Fh";
BA_ "InvalidValue" SG_ 203 RMCU_MotorSpdValid "1h";
BA_ "InvalidValue" SG_ 203 RMCU_MotorTqValid "1h";
BA_ "InvalidValue" SG_ 203 RMCU_CVC_CtrlMode "Fh";
BA_ "InvalidValue" SG_ 203 RMCU_CVC_StsMode "Fh";
BA_ "InvalidValue" SG_ 217 ALIVE_CVC_HV_DrvSys_status "Fh";
BA_ "InvalidValue" SG_ 217 CVC_HVsystem_status "7h";
BA_ "InvalidValue" SG_ 217 CVC_ACPD_Percent "FFFh";
BA_ "InvalidValue" SG_ 217 CVC_ACPD_Percent_Valid "1h";
BA_ "InvalidValue" SG_ 217 CVC_ACTGearValid "1h";
BA_ "InvalidValue" SG_ 217 CVC_ACT_DriveMode_Valid "1h";
BA_ "GenSigStartValue" SG_ 217 CVC_ACT_DriveMode_Valid 1;
BA_ "InvalidValue" SG_ 217 CVC_HV_DRVsystem_status "7h";
BA_ "InvalidValue" SG_ 258 ALIVE_CVC_LOGICAL_CLAMP "Fh";
BA_ "InvalidValue" SG_ 258 STAT_CrankRelayHW_BCM "3h";
BA_ "InvalidValue" SG_ 258 CVC_Transport_Mode "3h";
BA_ "InvalidValue" SG_ 258 CVC_Vehicle_Special_Mode "7h";
BA_ "InvalidValue" SG_ 258 CVC_Acc_Mode_Req "3h";
BA_ "InvalidValue" SG_ 258 CVC_CL30s_Req "3h";
BA_ "GenSigStartValue" SG_ 258 CVC_CL30s_Req 3;
BA_ "InvalidValue" SG_ 258 CVC_CL30c_Req "3h";
BA_ "GenSigStartValue" SG_ 258 CVC_CL30c_Req 3;
BA_ "InvalidValue" SG_ 258 CVC_CLR_Req "3h";
BA_ "GenSigStartValue" SG_ 258 CVC_CLR_Req 3;
BA_ "InvalidValue" SG_ 258 CVC_CL15_Req "3h";
BA_ "GenSigStartValue" SG_ 258 CVC_CL15_Req 3;
BA_ "InvalidValue" SG_ 258 CVC_CL58_Req "3h";
BA_ "GenSigStartValue" SG_ 258 CVC_CL58_Req 3;
BA_ "InvalidValue" SG_ 260 ALIVE_BCM_FL_Measured_Data "Fh";
BA_ "InvalidValue" SG_ 260 SOH_SUL "FFh";
BA_ "GenSigStartValue" SG_ 260 SOH_SUL 100;
BA_ "InvalidValue" SG_ 260 SOH_SUL_STATE "3h";
BA_ "GenSigStartValue" SG_ 260 SOH_SUL_STATE 3;
BA_ "InvalidValue" SG_ 260 SOC_STATE "3h";
BA_ "GenSigStartValue" SG_ 260 SOC_STATE 3;
BA_ "InvalidValue" SG_ 262 ALIVE_CVC_Body_LIGHT "Fh";
BA_ "InvalidValue" SG_ 262 Body_DayRunningLampSts "3h";
BA_ "InvalidValue" SG_ 262 Body_ReverseLightSts "3h";
BA_ "InvalidValue" SG_ 262 Body_StopLightSts "3h";
BA_ "InvalidValue" SG_ 262 Body_LicensePlateLightSts "3h";
BA_ "InvalidValue" SG_ 262 Body_Fr_Dimming_dome_lampSts "3h";
BA_ "InvalidValue" SG_ 262 Body_Rr_Dimming_dome_lampSts "3h";
BA_ "InvalidValue" SG_ 262 Body_STAT_InteriorLight "3h";
BA_ "GenSigStartValue" SG_ 262 Body_STAT_InteriorLight 3;
BA_ "InvalidValue" SG_ 262 Body_STAT_LightActivation "7h";
BA_ "GenSigStartValue" SG_ 262 Body_STAT_LightActivation 7;
BA_ "InvalidValue" SG_ 262 Body_HighBeamSts "3h";
BA_ "InvalidValue" SG_ 262 Body_STAT_SwitchLightBrightness "FFh";
BA_ "GenSigStartValue" SG_ 262 Body_STAT_SwitchLightBrightness 80;
BA_ "InvalidValue" SG_ 262 Body_LowBeamSts "3h";
BA_ "InvalidValue" SG_ 262 Body_RearFogLmpSts "3h";
BA_ "InvalidValue" SG_ 262 Body_FrntFogLmpSts "3h";
BA_ "InvalidValue" SG_ 262 Body_PosLmpSts "3h";
BA_ "InvalidValue" SG_ 262 Body_HornSts "3h";
BA_ "InvalidValue" SG_ 264 ALIVE_SS_DriveReq_0x108 "Fh";
BA_ "InvalidValue" SG_ 264 SS_P_Button "3h";
BA_ "InvalidValue" SG_ 264 SS_TargetGearReq "7h";
BA_ "InvalidValue" SG_ 264 SS_ADAS_Req "7h";
BA_ "InvalidValue" SG_ 264 SS_DrvMd_RgnLvl_Req "3h";
BA_ "InvalidValue" SG_ 264 SS_HighBeam_Req "3h";
BA_ "InvalidValue" SG_ 264 SS_Lane_Change_Indicator_Req "7h";
BA_ "InvalidValue" SG_ 264 SS_FR_RR_WashAndMist_Req "7h";
BA_ "InvalidValue" SG_ 264 SS_RR_WiperControl_Req "3h";
BA_ "InvalidValue" SG_ 264 SS_FR_Wipercontrol_Req "4h";
BA_ "InvalidValue" SG_ 264 SS_HardNumLow "Fh";
BA_ "InvalidValue" SG_ 264 SS_HardNumHigh "Fh";
BA_ "InvalidValue" SG_ 264 SS_SoftNumLow "Fh";
BA_ "InvalidValue" SG_ 264 SS_SoftNumHigh "Fh";
BA_ "GenSigTimeoutTime_ALL" SG_ 265 CRC_CVC_Body_SwitchSts 500;
BA_ "InvalidValue" SG_ 265 ALIVE_CVC_Body_SwitchSts "Fh";
BA_ "GenSigTimeoutTime_ALL" SG_ 265 ALIVE_CVC_Body_SwitchSts 500;
BA_ "InvalidValue" SG_ 265 Body_STAT_BrakeSwitch "3h";
BA_ "GenSigTimeoutTime_ALL" SG_ 265 Body_STAT_BrakeSwitch 500;
BA_ "GenSigSendType" SG_ 265 Body_STAT_BrakeSwitch 4;
BA_ "InvalidValue" SG_ 265 Body_STAT_HazardWarn "3h";
BA_ "GenSigTimeoutTime_ALL" SG_ 265 Body_STAT_HazardWarn 500;
BA_ "GenSigSendType" SG_ 265 Body_STAT_HazardWarn 4;
BA_ "InvalidValue" SG_ 265 Body_STAT_Autowiping "3h";
BA_ "GenSigTimeoutTime_ALL" SG_ 265 Body_STAT_Autowiping 500;
BA_ "GenSigSendType" SG_ 265 Body_STAT_Autowiping 4;
BA_ "InvalidValue" SG_ 265 Body_TurnIndicator "3h";
BA_ "GenSigTimeoutTime_ALL" SG_ 265 Body_TurnIndicator 500;
BA_ "InvalidValue" SG_ 266 ALIVE_BCM_VOLTAGE "Fh";
BA_ "InvalidValue" SG_ 266 LV_BatteryType "3h";
BA_ "GenSigStartValue" SG_ 266 UBatt 9205;
BA_ "InvalidValue" SG_ 266 LV_Batt_Temp_Reserved "FFh";
BA_ "GenSigStartValue" SG_ 266 LV_Batt_Temp_Reserved 40;
BA_ "InvalidValue" SG_ 266 LV_SOC_Reserved "FFh";
BA_ "GenSigStartValue" SG_ 266 LV_Batt_Current_Reserved 49152;
BA_ "InvalidValue" SG_ 180 ALIVE_BCM_WindowsFL_Status "Fh";
BA_ "InvalidValue" SG_ 180 Window_Position_FL "Fh";
BA_ "InvalidValue" SG_ 180 Window_Position_RL "Fh";
BA_ "InvalidValue" SG_ 530 ALIVE_BCMFR_ExteriorLight_STS "Fh";
BA_ "InvalidValue" SG_ 530 BCM_SideMarkerSts "3h";
BA_ "InvalidValue" SG_ 530 BCM_TurnIndicator_FR_STS "3h";
BA_ "GenSigSendType" SG_ 530 BCM_TurnIndicator_FR_STS 2;
BA_ "InvalidValue" SG_ 530 BCM_PositionLight_FR_STS "3h";
BA_ "GenSigSendType" SG_ 530 BCM_PositionLight_FR_STS 2;
BA_ "InvalidValue" SG_ 530 BCM_FrontFogLamp_FR_STS "3h";
BA_ "GenSigSendType" SG_ 530 BCM_FrontFogLamp_FR_STS 2;
BA_ "InvalidValue" SG_ 530 BCM_DaytimeRunningLight_FR_Sts "3h";
BA_ "GenSigSendType" SG_ 530 BCM_DaytimeRunningLight_FR_Sts 2;
BA_ "InvalidValue" SG_ 530 BCM_MirrorLED_FR_STS "3h";
BA_ "GenSigSendType" SG_ 530 BCM_MirrorLED_FR_STS 2;
BA_ "InvalidValue" SG_ 530 BCM_LowBeam_FR_Sts "3h";
BA_ "GenSigSendType" SG_ 530 BCM_LowBeam_FR_Sts 2;
BA_ "InvalidValue" SG_ 530 BCM_HighBeam_FR_Sts "3h";
BA_ "GenSigSendType" SG_ 530 BCM_HighBeam_FR_Sts 2;
BA_ "InvalidValue" SG_ 267 ALIVE_TRM_LIGHT "Fh";
BA_ "InvalidValue" SG_ 267 TrailerInput "3h";
BA_ "GenSigStartValue" SG_ 267 TrailerInput 3;
BA_ "InvalidValue" SG_ 267 TrailerSystemError "3h";
BA_ "GenSigStartValue" SG_ 267 TrailerSystemError 3;
BA_ "InvalidValue" SG_ 267 TRM_VoltageStatus "3h";
BA_ "InvalidValue" SG_ 267 TRM_STAT_BrakeLight "3h";
BA_ "InvalidValue" SG_ 267 TRM_STAT_FogLampRear "3h";
BA_ "InvalidValue" SG_ 267 TRM_STAT_PositionLight "3h";
BA_ "InvalidValue" SG_ 267 TRM_STAT_TurnIndicators "Fh";
BA_ "InvalidValue" SG_ 267 TRM_STAT_ReverseLight "3h";
BA_ "InvalidValue" SG_ 267 TRM_STAT_HWBrakeLightInput "3h";
BA_ "InvalidValue" SG_ 267 TRM_STAT_HWIndicatorInput "3h";
BA_ "InvalidValue" SG_ 267 TRM_STAT_HWPosLightInput "3h";
BA_ "InvalidValue" SG_ 273 ALIVE_CVC_WCBS01 "Fh";
BA_ "InvalidValue" SG_ 273 CVC_F_RegenTrqMax "FFFh";
BA_ "GenSigStartValue" SG_ 273 CVC_F_RegenTrqMax 4000;
BA_ "InvalidValue" SG_ 273 CVC_R_RegenTrqMax "FFFh";
BA_ "GenSigStartValue" SG_ 273 CVC_R_RegenTrqMax 4000;
BA_ "InvalidValue" SG_ 273 CVC_F_BrkRegenTrqActual "FFFh";
BA_ "GenSigStartValue" SG_ 273 CVC_F_BrkRegenTrqActual 4000;
BA_ "InvalidValue" SG_ 273 CVC_R_BrkRegenTrqActual "FFFh";
BA_ "GenSigStartValue" SG_ 273 CVC_R_BrkRegenTrqActual 4000;
BA_ "InvalidValue" SG_ 273 CVC_OnePedalModeSts "3h";
BA_ "InvalidValue" SG_ 273 CVC_OnePedalModeEnable "3h";
BA_ "InvalidValue" SG_ 273 CVC_TargetBrkTq "FFFh";
BA_ "InvalidValue" SG_ 274 ALIVE_CVC_CLAMP_STAT "Fh";
BA_ "InvalidValue" SG_ 274 CVC_STAT_BLS "3h";
BA_ "InvalidValue" SG_ 274 Vehicle_Operation_State "7h";
BA_ "InvalidValue" SG_ 279 ALIVE_WCBS_Pressure "Fh";
BA_ "InvalidValue" SG_ 279 WCBS_CircuitPressValid "1h";
BA_ "InvalidValue" SG_ 279 WCBS_EstWhlPress_FL "7FFFh";
BA_ "InvalidValue" SG_ 279 WCBS_EstWhlPress_FR "7FFFh";
BA_ "InvalidValue" SG_ 279 WCBS_EstWhlPress_RL "7FFFh";
BA_ "InvalidValue" SG_ 279 WCBS_EstWhlPress_RR "7FFFh";
BA_ "InvalidValue" SG_ 279 WCBS_EstWhlPressValid "1h";
BA_ "InvalidValue" SG_ 279 WCBS_MainCylinderPressValid "1h";
BA_ "InvalidValue" SG_ 289 ALIVE_WCBS_WheelSpeedKPH_R "Fh";
BA_ "InvalidValue" SG_ 289 WCBS_RRWheelSpeedKPH "1FFFh";
BA_ "InvalidValue" SG_ 289 WCBS_RRWheelSpeedValid "1h";
BA_ "InvalidValue" SG_ 289 WCBS_RLWheelSpeedKPH "1FFFh";
BA_ "InvalidValue" SG_ 289 WCBS_RLWheelSpeedValid "1h";
BA_ "InvalidValue" SG_ 290 ALIVE_WCBS_WheelSpeedKPH_F "Fh";
BA_ "InvalidValue" SG_ 290 WCBS_FRWheelSpeedKPH "1FFFh";
BA_ "InvalidValue" SG_ 290 WCBS_FRWheelSpeedValid "1h";
BA_ "InvalidValue" SG_ 290 WCBS_FLWheelSpeedKPH "1FFFh";
BA_ "InvalidValue" SG_ 290 WCBS_FLWheelSpeedValid "1h";
BA_ "InvalidValue" SG_ 291 ALIVE_CVC_ACCharging_Info "Fh";
BA_ "InvalidValue" SG_ 292 ALIVE_WCBS_WheelSpeedRC "Fh";
BA_ "InvalidValue" SG_ 292 WCBS_FLWheelSpeedRCSts "1h";
BA_ "InvalidValue" SG_ 292 WCBS_RLWheelSpeedRCSts "1h";
BA_ "InvalidValue" SG_ 292 WCBS_FRWheelSpeedRCSts "1h";
BA_ "InvalidValue" SG_ 292 WCBS_RRWheelSpeedRCSts "1h";
BA_ "InvalidValue" SG_ 292 WCBS_RLWheelSpeedRC "-";
BA_ "InvalidValue" SG_ 292 WCBS_RRWheelSpeedRC "-";
BA_ "InvalidValue" SG_ 292 WCBS_FLWheelSpeedRC "-";
BA_ "InvalidValue" SG_ 292 WCBS_FRWheelSpeedRC "-";
BA_ "InvalidValue" SG_ 293 ALIVE_CVC_DCCharging_Info "Fh";
BA_ "InvalidValue" SG_ 306 ALIVE_WCBS_ESC_Status "Fh";
BA_ "InvalidValue" SG_ 306 ESC_SlopeGrade "FFh";
BA_ "InvalidValue" SG_ 311 ALIVE_EAS_CDC_WorkState "Fh";
BA_ "GenSigStartValue" SG_ 311 EAS_SuspensionMode 1;
BA_ "InvalidValue" SG_ 311 EAS_ValveValue_FL "7h";
BA_ "InvalidValue" SG_ 311 EAS_ValveValue_FR "7h";
BA_ "InvalidValue" SG_ 311 EAS_ValveValue_RL "7h";
BA_ "InvalidValue" SG_ 311 EAS_ValveValue_RR "7h";
BA_ "InvalidValue" SG_ 311 EAS_LiftModFb "3h";
BA_ "InvalidValue" SG_ 357 ALIVE_CVC_ChargingConnection "Fh";
BA_ "GenSigStartValue" SG_ 357 CVC_ACChargingVoltage 1;
BA_ "GenSigStartValue" SG_ 357 CVC_MinCurrentOfACCharging 1;
BA_ "InvalidValue" SG_ 372 ALIVE_BMS_CurMeas "Fh";
BA_ "GenSigStartValue" SG_ 372 BMS_PackCur_MEAS 32768;
BA_ "GenSigStartValue" SG_ 372 BMS_PackInsuRes 5535;
BA_ "InvalidValue" SG_ 382 ALIVE_EPS_SAS_Sensor "Fh";
BA_ "GenSigStartValue" SG_ 382 SAS_SteerWhlRotSpd 8000;
BA_ "InvalidValue" SG_ 382 SAS_SteerWheelAngleValid "1h";
BA_ "GenSigTimeoutTime_ALL" SG_ 466 CRC_FCAM_DEBUG 250;
BA_ "InvalidValue" SG_ 466 ALIVE_FCAM_DEBUG "Fh";
BA_ "GenSigTimeoutTime_ALL" SG_ 466 ALIVE_FCAM_DEBUG 250;
BA_ "InvalidValue" SG_ 466 FCAM_ACC_AdtUpperJerkLimit "0h";
BA_ "InvalidValue" SG_ 466 FCAM_ACC_AdtLowerJerkLimit "0h";
BA_ "InvalidValue" SG_ 507 ALIVE_CVC_ACU_Info1 "Fh";
BA_ "GenSigStartValue" SG_ 522 ETG_Lift_Gate_Status 9;
BA_ "GenSigStartValue" SG_ 522 ETG_Power_Latch_Status 7;
BA_ "GenSigStartValue" SG_ 522 ETG_Latch_Segment 3;
BA_ "GenSigStartValue" SG_ 522 ETG_AJR_Status 1;
BA_ "InvalidValue" SG_ 522 ETG_ERR_Voltage "3h";
BA_ "InvalidValue" SG_ 522 ETG_ERR_Left_Motor "3h";
BA_ "InvalidValue" SG_ 522 ETG_ERR_Right_Motor "3h";
BA_ "InvalidValue" SG_ 522 ETG_ERR_Latch "3h";
BA_ "InvalidValue" SG_ 524 ALIVE_CVC_ODO "Fh";
BA_ "InvalidValue" SG_ 524 CVC_Odometer "FFFFFh";
BA_ "InvalidValue" SG_ 524 CVC_OdometerV "1h";
BA_ "GenSigTimeoutTime_ALL" SG_ 525 CRC_WCBS_STATUS 200;
BA_ "InvalidValue" SG_ 525 ALIVE_WCBS_STATUS "Fh";
BA_ "GenSigTimeoutTime_ALL" SG_ 525 ALIVE_WCBS_STATUS 200;
BA_ "GenSigTimeoutTime_ALL" SG_ 525 ABSFailed 200;
BA_ "GenSigTimeoutTime_ALL" SG_ 525 ABSActive 200;
BA_ "GenSigTimeoutTime_ALL" SG_ 525 WCBS_VehicleSpeed 200;
BA_ "GenSigTimeoutTime_ALL" SG_ 525 ESC_VehicleStandstill 200;
BA_ "InvalidValue" SG_ 525 WCBS_VehicleSpeedValid "1h";
BA_ "GenSigTimeoutTime_ALL" SG_ 525 WCBS_VehicleSpeedValid 200;
BA_ "GenSigTimeoutTime_ALL" SG_ 525 ESC_VehicleHoldStat 200;
BA_ "InvalidValue" SG_ 525 WCBS_Veh_DriveCondition "7h";
BA_ "InvalidValue" SG_ 533 ALIVE_BMS_Sts "Fh";
BA_ "GenSigStartValue" SG_ 533 BMS_SOH 54;
BA_ "GenSigStartValue" SG_ 533 BMS_SOE 54;
BA_ "InvalidValue" SG_ 533 BMS_HV_Sts "FFh";
BA_ "InvalidValue" SG_ 534 ALIVE_BMS_ChgParamReq "Fh";
BA_ "InvalidValue" SG_ 542 CVC_RearFogLampSts "3h";
BA_ "InvalidValue" SG_ 542 CVC_ExteriorLightSts "4h";
BA_ "InvalidValue" SG_ 542 CVC_FollowMeHomeSts "5h";
BA_ "InvalidValue" SG_ 542 CVC_WelcomeLightSts "3h";
BA_ "InvalidValue" SG_ 542 CVC_FrontFogLampSts "3h";
BA_ "GenSigTimeoutTime_ALL" SG_ 560 CRC_WCBS_VAFS 400;
BA_ "InvalidValue" SG_ 560 ALIVE_WCBS_VAFS "Fh";
BA_ "GenSigTimeoutTime_ALL" SG_ 560 ALIVE_WCBS_VAFS 400;
BA_ "GenSigTimeoutTime_ALL" SG_ 560 WCBS_BrkLampReq 400;
BA_ "GenSigTimeoutTime_ALL" SG_ 560 EPB_SysWrnIndReq 400;
BA_ "GenSigTimeoutTime_ALL" SG_ 560 EPB_SysStatIndReq 400;
BA_ "GenSigTimeoutTime_ALL" SG_ 560 EPB_SysDspMsgReq 400;
BA_ "InvalidValue" SG_ 560 EPB_Sts "7h";
BA_ "GenSigTimeoutTime_ALL" SG_ 560 EPB_Sts 400;
BA_ "GenSigTimeoutTime_ALL" SG_ 560 WCBS_TSMActive 400;
BA_ "InvalidValue" SG_ 560 EPB_CDPActive "Fh";
BA_ "GenSigTimeoutTime_ALL" SG_ 560 EPB_CDPActive 400;
BA_ "GenSigTimeoutTime_ALL" SG_ 560 EPB_Swch_Mafnc 400;
BA_ "GenSigTimeoutTime_ALL" SG_ 560 WCBS_Avh_Available 400;
BA_ "GenSigTimeoutTime_ALL" SG_ 560 WCBS_AVH_DispMsg 400;
BA_ "InvalidValue" SG_ 560 WCBS_AVH_Status "Fh";
BA_ "GenSigTimeoutTime_ALL" SG_ 560 WCBS_AVH_Status 400;
BA_ "GenSigTimeoutTime_ALL" SG_ 560 WCBS_EPB_Fault 400;
BA_ "GenSigTimeoutTime_ALL" SG_ 560 WCBS_ROMActive 400;
BA_ "GenSigTimeoutTime_ALL" SG_ 560 WCBS_ROMFailure 400;
BA_ "GenSigTimeoutTime_ALL" SG_ 560 WCBS_TrailerDetected 400;
BA_ "GenSigTimeoutTime_ALL" SG_ 560 WCBS_TSMFailure 400;
BA_ "GenSigTimeoutTime_ALL" SG_ 560 WCBS_OnePedalAvailable 400;
BA_ "InvalidValue" SG_ 560 WCBS_BrkFricTqTotAtWhls "3FFFh";
BA_ "GenSigTimeoutTime_ALL" SG_ 560 WCBS_BrkFricTqTotAtWhls 400;
BA_ "InvalidValue" SG_ 560 WCBS_HDCCtrlsts "3h";
BA_ "GenSigTimeoutTime_ALL" SG_ 560 WCBS_HDCCtrlsts 400;
BA_ "GenSigTimeoutTime_ALL" SG_ 560 WCBS_HDC_displayWarnMsg 400;
BA_ "InvalidValue" SG_ 560 WCBS_VehicleSteerSts "3h";
BA_ "GenSigTimeoutTime_ALL" SG_ 560 WCBS_VehicleSteerSts 400;
BA_ "GenSigTimeoutTime_ALL" SG_ 560 WCBS_HDC_available 400;
BA_ "GenSigTimeoutTime_ALL" SG_ 560 WCBS_HDC_SwitchSts 400;
BA_ "GenSigTimeoutTime_ALL" SG_ 560 WCBS_DTCFailure 400;
BA_ "GenSigTimeoutTime_ALL" SG_ 560 WCBS_TowMode_Feedback 400;
BA_ "InvalidValue" SG_ 560 WCBS_SCM_available "0h";
BA_ "GenSigTimeoutTime_ALL" SG_ 560 WCBS_SCM_available 400;
BA_ "GenSigTimeoutTime_ALL" SG_ 560 WCBS_OnePedal_Active 400;
BA_ "GenSigTimeoutTime_ALL" SG_ 560 WCBS_OnePedal_hold_state 400;
BA_ "GenSigTimeoutTime_ALL" SG_ 560 WCBS_CDPFailSts 400;
BA_ "InvalidValue" SG_ 560 WCBS_CBC_Active "0h";
BA_ "GenSigTimeoutTime_ALL" SG_ 560 WCBS_CBC_Active 400;
BA_ "InvalidValue" SG_ 560 WCBS_CBC_Available "0h";
BA_ "GenSigTimeoutTime_ALL" SG_ 560 WCBS_CBC_Available 400;
BA_ "InvalidValue" SG_ 560 WCBS_SLS_Active "0h";
BA_ "GenSigTimeoutTime_ALL" SG_ 560 WCBS_SLS_Active 400;
BA_ "InvalidValue" SG_ 560 WCBS_SLS_Available "0h";
BA_ "GenSigTimeoutTime_ALL" SG_ 560 WCBS_SLS_Available 400;
BA_ "InvalidValue" SG_ 560 WCBS_TVBB_Active "0h";
BA_ "GenSigTimeoutTime_ALL" SG_ 560 WCBS_TVBB_Active 400;
BA_ "InvalidValue" SG_ 560 WCBS_TVBB_Available "0h";
BA_ "GenSigTimeoutTime_ALL" SG_ 560 WCBS_TVBB_Available 400;
BA_ "InvalidValue" SG_ 560 WCBS_BDW_Active "0h";
BA_ "GenSigTimeoutTime_ALL" SG_ 560 WCBS_BDW_Active 400;
BA_ "InvalidValue" SG_ 560 WCBS_BDW_Available "0h";
BA_ "GenSigTimeoutTime_ALL" SG_ 560 WCBS_BDW_Available 400;
BA_ "GenSigTimeoutTime_ALL" SG_ 560 WCBS_SCMActive 400;
BA_ "InvalidValue" SG_ 561 ALIVE_DoorFLStatus "Fh";
BA_ "InvalidValue" SG_ 561 DOW_DoorAjarStatusRL "3h";
BA_ "InvalidValue" SG_ 561 DOW_DoorAjarStatusFL "3h";
BA_ "InvalidValue" SG_ 561 CVC_ADAS_BonnetAjarStatus "3h";
BA_ "InvalidValue" SG_ 561 CVC_ADAS_TailgateAjarStatus "3h";
BA_ "InvalidValue" SG_ 565 ALIVE_TRM_STATUS "Fh";
BA_ "InvalidValue" SG_ 565 TRM_TowingDetected "3h";
BA_ "InvalidValue" SG_ 565 TRM_TrailerDetected "3h";
BA_ "InvalidValue" SG_ 562 ALIVE_CVC_Door_Status "Fh";
BA_ "GenSigStartValue" SG_ 562 DriverDoor_Lock_Sts 3;
BA_ "GenSigStartValue" SG_ 562 CoDriverDoor_Lock_Sts 3;
BA_ "GenSigStartValue" SG_ 562 RearLeftDoor_Lock_Sts 3;
BA_ "GenSigStartValue" SG_ 562 RearRightDoor_Lock_Sts 3;
BA_ "GenSigStartValue" SG_ 562 STAT_CDL_LED 3;
BA_ "InvalidValue" SG_ 571 ALIVE_CVC_ACPE "Fh";
BA_ "InvalidValue" SG_ 571 CVC_ACPE_Actuator "7h";
BA_ "GenSigStartValue" SG_ 571 CVC_ACPE_Actuator 7;
BA_ "GenSigSendType" SG_ 571 CVC_ACPE_Actuator 2;
BA_ "InvalidValue" SG_ 571 CVC_ACPE_PedalErrorEvent "3h";
BA_ "GenSigStartValue" SG_ 571 CVC_ACPE_PedalErrorEvent 3;
BA_ "GenSigSendType" SG_ 571 CVC_ACPE_PedalErrorEvent 2;
BA_ "InvalidValue" SG_ 571 CVC_ACPE_Available_Flag "3h";
BA_ "GenSigStartValue" SG_ 571 CVC_ACPE_Available_Flag 3;
BA_ "GenSigSendType" SG_ 571 CVC_ACPE_Available_Flag 2;
BA_ "InvalidValue" SG_ 571 CVC_ACPE_Active_Flag "0h";
BA_ "GenSigStartValue" SG_ 571 CVC_ACPE_Active_Flag 1;
BA_ "GenSigSendType" SG_ 571 CVC_ACPE_Active_Flag 2;
BA_ "InvalidValue" SG_ 571 CVC_ACPE_HeathCheck "3h";
BA_ "GenSigStartValue" SG_ 571 CVC_ACPE_HeathCheck 3;
BA_ "GenSigSendType" SG_ 571 CVC_ACPE_HeathCheck 2;
BA_ "InvalidValue" SG_ 581 ALIVE_BMS_CellTemp "Fh";
BA_ "GenSigStartValue" SG_ 581 BMS_ProbeNumMaxCellTemp 1;
BA_ "GenSigStartValue" SG_ 581 BMS_MinCellTemp 80;
BA_ "GenSigStartValue" SG_ 581 BMS_PackTemp 80;
BA_ "GenSigStartValue" SG_ 581 BMS_MaxCellTemp 80;
BA_ "GenSigStartValue" SG_ 581 BMS_MaxMinDiffCellTemp 80;
BA_ "InvalidValue" SG_ 584 ALIVE_DoorFRStatus "Fh";
BA_ "InvalidValue" SG_ 584 DOW_DoorAjarStatusRR "3h";
BA_ "InvalidValue" SG_ 584 DOW_DoorAjarStatusFR "3h";
BA_ "InvalidValue" SG_ 624 ALIVE_WCBS_Info "Fh";
BA_ "InvalidValue" SG_ 624 WCBS_Fault_Status "7h";
BA_ "InvalidValue" SG_ 624 FBW_WarningSts "3h";
BA_ "GenSigTimeoutTime_ALL" SG_ 624 FBW_WarningSts 200;
BA_ "GenSigTimeoutTime_ALL" SG_ 624 Brake_Disc_Temp_FL 200;
BA_ "GenSigTimeoutTime_ALL" SG_ 624 Brake_Disc_Temp_FR 200;
BA_ "GenSigTimeoutTime_ALL" SG_ 624 Brake_Disc_Temp_RL 200;
BA_ "GenSigTimeoutTime_ALL" SG_ 624 Brake_Disc_Temp_RR 200;
BA_ "InvalidValue" SG_ 624 WCBS_BrakesystemFailSts "7h";
BA_ "InvalidValue" SG_ 662 ALIVE_POD_DCDC_Status "Fh";
BA_ "InvalidValue" SG_ 662 PDU_DCDC_StsCtrl "Fh";
BA_ "InvalidValue" SG_ 674 DrvSeatMsgModeStat "6h";
BA_ "GenSigStartValue" SG_ 674 DrvSeatMsgStrLvlStat 1;
BA_ "InvalidValue" SG_ 674 PassSeatMsgModeStat "6h";
BA_ "GenSigStartValue" SG_ 674 PassSeatMsgStrLvlStat 1;
BA_ "InvalidValue" SG_ 674 DrvSeatMsgModeStat_sec "6h";
BA_ "GenSigStartValue" SG_ 674 DrvSeatMsgStrLvlStat_sec 1;
BA_ "InvalidValue" SG_ 674 PsSeatMsgModeStat_sec "6h";
BA_ "GenSigStartValue" SG_ 674 PsSeatMsgStrLvlStat_sec 1;
BA_ "GenSigTimeoutTime_ALL" SG_ 746 InteriorTemperature 500;
BA_ "GenSigStartValue" SG_ 746 CVC_DCChgPosTemp 40;
BA_ "GenSigStartValue" SG_ 746 CVC_DCChgNegTemp 40;
BA_ "GenSigStartValue" SG_ 746 CVC_ACChgLTerminalTemp 40;
BA_ "GenSigStartValue" SG_ 746 CVC_ACChgNTerminalTemp_Reserve 40;
BA_ "GenSigStartValue" SG_ 760 DISP_DATE_DAY 1;
BA_ "GenSigStartValue" SG_ 760 DISP_DATE_MON 1;
BA_ "GenSigStartValue" SG_ 760 DISP_DATE_YR 1;
BA_ "InvalidValue" SG_ 768 CVC_STAT_SyncClimateZone "3h";
BA_ "GenSigSendType" SG_ 768 CVC_STAT_SyncClimateZone 1;
BA_ "InvalidValue" SG_ 768 CVC_STAT_Auto "3h";
BA_ "GenSigSendType" SG_ 768 CVC_STAT_Auto 1;
BA_ "InvalidValue" SG_ 768 CVC_STAT_Aircondition "3h";
BA_ "GenSigSendType" SG_ 768 CVC_STAT_Aircondition 1;
BA_ "InvalidValue" SG_ 768 CVC_STAT_IonButton "3h";
BA_ "GenSigSendType" SG_ 768 CVC_STAT_IonButton 1;
BA_ "InvalidValue" SG_ 768 CVC_STAT_MaxAc "3h";
BA_ "GenSigSendType" SG_ 768 CVC_STAT_MaxAc 1;
BA_ "InvalidValue" SG_ 768 CVC_STAT_ClimateOnOff "3h";
BA_ "GenSigStartValue" SG_ 768 CVC_STAT_ClimateOnOff 3;
BA_ "GenSigSendType" SG_ 768 CVC_STAT_ClimateOnOff 1;
BA_ "InvalidValue" SG_ 768 CVC_STAT_FanSpeed "Fh";
BA_ "GenSigSendType" SG_ 768 CVC_STAT_FanSpeed 1;
BA_ "InvalidValue" SG_ 768 CVC_STAT_RecircFlap "3h";
BA_ "GenSigStartValue" SG_ 768 CVC_STAT_RecircFlap 1;
BA_ "GenSigSendType" SG_ 768 CVC_STAT_RecircFlap 1;
BA_ "InvalidValue" SG_ 768 CVC_STAT_AirDistributionMode "7h";
BA_ "GenSigSendType" SG_ 768 CVC_STAT_AirDistributionMode 1;
BA_ "InvalidValue" SG_ 768 CVC_STAT_Defrost "3h";
BA_ "GenSigSendType" SG_ 768 CVC_STAT_Defrost 1;
BA_ "InvalidValue" SG_ 768 CVC_STAT_PTC_Heater "7h";
BA_ "GenSigSendType" SG_ 768 CVC_STAT_PTC_Heater 1;
BA_ "GenSigStartValue" SG_ 768 CVC_STAT_TempDriver 40;
BA_ "GenSigSendType" SG_ 768 CVC_STAT_TempDriver 1;
BA_ "GenSigStartValue" SG_ 768 CVC_STAT_TempPassenger 40;
BA_ "GenSigSendType" SG_ 768 CVC_STAT_TempPassenger 1;
BA_ "InvalidValue" SG_ 768 CVC_CoolSysWarnLvl "7h";
BA_ "GenSigSendType" SG_ 768 CVC_CoolSysWarnLvl 1;
BA_ "InvalidValue" SG_ 777 ALIVE_CVC_CPD_Warn_Sts "Fh";
BA_ "InvalidValue" SG_ 778 ALIVE_CVC_DKCU_CommandRequest "Fh";
BA_ "GenSigSendType" SG_ 778 CVC_DKCU_PhoneLocationReq 4;
BA_ "GenSigSendType" SG_ 779 CVC_DKCU_Temp_Intervention_Fdbk 4;
BA_ "GenSigSendType" SG_ 779 CVC_DKCU_Remote_Phone_Interventi 4;
BA_ "SystemSignalLongSymbol" SG_ 779 CVC_DKCU_Remote_Phone_Interventi "CVC_DKCU_Remote_Phone_Intervention_Fdbk";
BA_ "InvalidValue" SG_ 787 ALIVE_POD_OBC_StatusCharger1 "Fh";
BA_ "InvalidValue" SG_ 787 POD_GTW_statusOBC "Fh";
BA_ "GenSigStartValue" SG_ 787 POD_GTW_statusOBC 7;
BA_ "InvalidValue" SG_ 803 ALIVE_POD_OBC_StatusCharger2 "Fh";
BA_ "GenSigStartValue" SG_ 803 POD_GW_PhaseACInput 1;
BA_ "InvalidValue" SG_ 803 POD_tempACCharger "FFh";
BA_ "GenSigStartValue" SG_ 803 POD_tempACCharger 40;
BA_ "InvalidValue" SG_ 803 POD_tempColdplate "FFh";
BA_ "GenSigStartValue" SG_ 803 POD_tempColdplate 40;
BA_ "GenSigStartValue" SG_ 805 BCMFL_STAT_SteerPosX 50;
BA_ "GenSigStartValue" SG_ 805 BCMFL_STAT_SteerPosY 50;
BA_ "GenSigStartValue" SG_ 805 Steering_Wheel_Telescope_Positio 20;
BA_ "SystemSignalLongSymbol" SG_ 805 Steering_Wheel_Telescope_Positio "Steering_Wheel_Telescope_Position_Status";
BA_ "InvalidValue" SG_ 805 Steering_Wheel_Convenience_Acces "3h";
BA_ "SystemSignalLongSymbol" SG_ 805 Steering_Wheel_Convenience_Acces "Steering_Wheel_Convenience_Access";
BA_ "GenSigStartValue" SG_ 805 Steering_Wheel_Angle_Status 21;
BA_ "InvalidValue" SG_ 805 BCMFL_STS_SteerAdjust "3h";
BA_ "InvalidValue" SG_ 805 SWHC_SterringWheelHeatFaultReaso "1h";
BA_ "SystemSignalLongSymbol" SG_ 805 SWHC_SterringWheelHeatFaultReaso "SWHC_SterringWheelHeatFaultReason";
BA_ "GenSigTimeoutTime_ALL" SG_ 815 CRC_WCBS_ADAS_Info 200;
BA_ "InvalidValue" SG_ 815 ALIVE_WCBS_ADAS_Info "Fh";
BA_ "GenSigTimeoutTime_ALL" SG_ 815 ALIVE_WCBS_ADAS_Info 200;
BA_ "GenSigTimeoutTime_ALL" SG_ 815 WCBS_ACC_Available_Flag 200;
BA_ "GenSigTimeoutTime_ALL" SG_ 815 WCBS_ACC_Deceleration_Flag 200;
BA_ "GenSigTimeoutTime_ALL" SG_ 815 WCBS_ACC_Acceleration_Flag 200;
BA_ "GenSigTimeoutTime_ALL" SG_ 815 WCBS_RAEB_Active_Flag 200;
BA_ "GenSigTimeoutTime_ALL" SG_ 815 WCBS_RAEB_Available_Flag 200;
BA_ "GenSigTimeoutTime_ALL" SG_ 815 WCBS_AEB_Active_Flag 200;
BA_ "GenSigTimeoutTime_ALL" SG_ 815 WCBS_AEB_Available_Flag 200;
BA_ "GenSigTimeoutTime_ALL" SG_ 815 WCBS_ACC_DriverOverride 200;
BA_ "InvalidValue" SG_ 815 WCBS_ACC_TargetWheel_Torque "FFFFh";
BA_ "GenSigStartValue" SG_ 815 WCBS_ACC_TargetWheel_Torque 8000;
BA_ "GenSigTimeoutTime_ALL" SG_ 815 WCBS_RAEB_BrakeActuator 200;
BA_ "InvalidValue" SG_ 838 ALIVE_POD_StatusDCDC2 "Fh";
BA_ "InvalidValue" SG_ 843 ALIVE_EVCC_EVSE_Info_1 "Fh";
BA_ "InvalidValue" SG_ 847 ALIVE_EVCC_EVSE_Info_2 "Fh";
BA_ "InvalidValue" SG_ 852 ALIVE_CVC_FCAM_req "Fh";
BA_ "InvalidValue" SG_ 852 CVC_RAEB_Mode "3h";
BA_ "GenSigStartValue" SG_ 852 CVC_RAEB_Mode 1;
BA_ "InvalidValue" SG_ 852 CVC_LA_AudWarning "3h";
BA_ "InvalidValue" SG_ 852 CVC_BSD_On "3h";
BA_ "GenSigStartValue" SG_ 852 CVC_BSD_On 1;
BA_ "InvalidValue" SG_ 852 CVC_BSD_sens "3h";
BA_ "GenSigStartValue" SG_ 852 CVC_BSD_sens 1;
BA_ "InvalidValue" SG_ 852 CVC_BSD_AudWarning "3h";
BA_ "InvalidValue" SG_ 852 CVC_RCTA_On "3h";
BA_ "GenSigStartValue" SG_ 852 CVC_RCTA_On 1;
BA_ "InvalidValue" SG_ 852 CVC_RCTA_sens "3h";
BA_ "GenSigStartValue" SG_ 852 CVC_RCTA_sens 1;
BA_ "InvalidValue" SG_ 852 CVC_PA_On "3h";
BA_ "GenSigStartValue" SG_ 852 CVC_PA_On 1;
BA_ "InvalidValue" SG_ 852 CVC_AHB_On "3h";
BA_ "InvalidValue" SG_ 852 CVC_IA_Mode "3h";
BA_ "InvalidValue" SG_ 852 CVC_TSR_Mode "3h";
BA_ "GenSigStartValue" SG_ 852 CVC_TSR_Mode 1;
BA_ "InvalidValue" SG_ 852 CVC_DOW_Mode "3h";
BA_ "GenSigStartValue" SG_ 852 CVC_DOW_Mode 2;
BA_ "InvalidValue" SG_ 852 CVC_AHB_sens "3h";
BA_ "GenSigStartValue" SG_ 852 CVC_AHB_sens 1;
BA_ "InvalidValue" SG_ 852 CVC_FCW_sens "3h";
BA_ "GenSigStartValue" SG_ 852 CVC_FCW_sens 1;
BA_ "InvalidValue" SG_ 852 CVC_LA_Mode "3h";
BA_ "GenSigStartValue" SG_ 852 CVC_LA_Mode 3;
BA_ "InvalidValue" SG_ 852 CVC_FCW_Mode "3h";
BA_ "GenSigStartValue" SG_ 852 CVC_FCW_Mode 1;
BA_ "InvalidValue" SG_ 852 CVC_SET_TSR_AudWarn "3h";
BA_ "GenSigStartValue" SG_ 852 CVC_SET_TSR_AudWarn 1;
BA_ "GenSigStartValue" SG_ 852 CVC_SET_TSR_SLAert 1;
BA_ "InvalidValue" SG_ 852 CVC_LA_sens "3h";
BA_ "GenSigStartValue" SG_ 852 CVC_LA_sens 1;
BA_ "InvalidValue" SG_ 852 CVC_AEB_Mode "3h";
BA_ "GenSigStartValue" SG_ 852 CVC_AEB_Mode 1;
BA_ "GenSigStartValue" SG_ 852 CVC_ELKA_ON 1;
BA_ "GenSigStartValue" SG_ 852 CVC_ALC_ON 1;
BA_ "InvalidValue" SG_ 852 CVC_DashCam_Setting "2h";
BA_ "GenSigStartValue" SG_ 852 CVC_DashCam_Setting 1;
BA_ "GenSigTimeoutTime_ALL" SG_ 852 CVC_HWA_Mode 50;
BA_ "InvalidValue" SG_ 852 CVC_Option_feed "3h";
BA_ "InvalidValue" SG_ 852 CVC_ALCA_LaneChange_confir "3h";
BA_ "InvalidValue" SG_ 852 CVC_ACPE_Setting "3h";
BA_ "GenSigStartValue" SG_ 852 CVC_ACPE_Setting 3;
BA_ "GenSigTimeoutTime_ALL" SG_ 852 CVC_ACPE_Setting 250;
BA_ "InvalidValue" SG_ 852 CVC_ACPE_Sens "3h";
BA_ "GenSigStartValue" SG_ 852 CVC_ACPE_Sens 3;
BA_ "GenSigTimeoutTime_ALL" SG_ 852 CVC_ACPE_Sens 250;
BA_ "InvalidValue" SG_ 852 CVC_SVM_Setting_Guideline "3h";
BA_ "GenSigStartValue" SG_ 852 CVC_SVM_Setting_Guideline 3;
BA_ "GenSigTimeoutTime_ALL" SG_ 852 CVC_SVM_Setting_Guideline 250;
BA_ "InvalidValue" SG_ 852 CVC_SVM_Setting_ObjOverlay "3h";
BA_ "GenSigStartValue" SG_ 852 CVC_SVM_Setting_ObjOverlay 3;
BA_ "GenSigTimeoutTime_ALL" SG_ 852 CVC_SVM_Setting_ObjOverlay 250;
BA_ "InvalidValue" SG_ 852 CVC_SVM_Setting_TrailerGuideline "3h";
BA_ "GenSigStartValue" SG_ 852 CVC_SVM_Setting_TrailerGuideline 3;
BA_ "GenSigTimeoutTime_ALL" SG_ 852 CVC_SVM_Setting_TrailerGuideline 250;
BA_ "InvalidValue" SG_ 852 CVC_SVM_Setting_MaxDoorOverlay "3h";
BA_ "GenSigStartValue" SG_ 852 CVC_SVM_Setting_MaxDoorOverlay 3;
BA_ "GenSigTimeoutTime_ALL" SG_ 852 CVC_SVM_Setting_MaxDoorOverlay 250;
BA_ "InvalidValue" SG_ 852 CVC_SVM_TransparentRequest "3h";
BA_ "GenSigStartValue" SG_ 852 CVC_SVM_TransparentRequest 3;
BA_ "GenSigTimeoutTime_ALL" SG_ 852 CVC_SVM_TransparentRequest 250;
BA_ "InvalidValue" SG_ 852 CVC_SVM_Setting_BlindSpotView "3h";
BA_ "GenSigStartValue" SG_ 852 CVC_SVM_Setting_BlindSpotView 3;
BA_ "GenSigTimeoutTime_ALL" SG_ 852 CVC_SVM_Setting_BlindSpotView 250;
BA_ "InvalidValue" SG_ 852 CVC_NOP_Mode "3h";
BA_ "GenSigTimeoutTime_ALL" SG_ 852 CVC_NOP_Mode 250;
BA_ "InvalidValue" SG_ 852 CVC_NOP_Type "3h";
BA_ "GenSigTimeoutTime_ALL" SG_ 852 CVC_NOP_Type 250;
BA_ "GenSigTimeoutTime_ALL" SG_ 852 CVC_ALC_Recommend 250;
BA_ "InvalidValue" SG_ 852 CVC_TLD_On "3h";
VAL_ 133 ACU_Crash_Sts 0 "No_Event" 1 "Crash_Detected" ;
VAL_ 133 ACU_Airbag_Deployment_Status 0 "No_Airbag_Deployment" 1 "Airbag_Deployment" ;
VAL_ 133 ACU_Crash_Intensity 0 "No_Crash" 1 "Crash_Intensity_1" 2 "Crash_Intensity_2" 3 "Crash_Intensity_3" ;
VAL_ 133 ACU_Front_Crash 0 "No_Event" 1 "Front_Crash_Detected" ;
VAL_ 133 ACU_DriverSide_Crash 0 "No_Event" 1 "Driverside_Crash_Detected" ;
VAL_ 133 ACU_PassSide_Crash 0 "No_Event" 1 "PasSide_Crash_Detected" ;
VAL_ 133 ACU_Rear_Crash 0 "No_Event" 1 "Rear_Crash_Detected" ;
VAL_ 133 ACU_Rollover_Crash 0 "No_Event" 1 "Rollover_Crash_Detected" ;
VAL_ 169 BCMFL_AmbientTempSts 0 "Normal" 1 "Short circuit Battery" 2 "Short circuit GND" 3 "Invalid" ;
VAL_ 169 BCMFL_CoolantTemp_EDS_In_Sts 0 "Normal" 1 "Short circuit Battery" 2 "Short circuit GND" 3 "Invalid" ;
VAL_ 169 BCMFL_CoolantTemp_EDS_Out_Sts 0 "Normal" 1 "Short circuit Battery" 2 "Short circuit GND" 3 "Invalid" ;
VAL_ 169 BCMFL_CoolantTemp_LTR_Out_Sts 0 "Normal" 1 "Short circuit Battery" 2 "Short circuit GND" 3 "Invalid" ;
VAL_ 169 BCMFL_ACLowSideTemperatureSts 0 "Normal" 1 "Short circuit Battery" 2 "Short circuit GND" 3 "Invalid" ;
VAL_ 169 BCMFL_ACLowSidePressureSts 0 "Normal" 1 "Short circuit Battery" 2 "Short circuit GND" 3 "Invalid" ;
VAL_ 169 BCMFL_ACHighSideTemperatureSts 0 "Normal" 1 "Short circuit Battery" 2 "Short circuit GND" 3 "Invalid" ;
VAL_ 169 BCMFL_ACHighSidePressureSts 0 "Normal" 1 "Short circuit Battery" 2 "Short circuit GND" 3 "Invalid" ;
VAL_ 169 BCMFL_CoolantTemp_HtrCore_In_Sts 0 "Normal" 1 "Short circuit Battery" 2 "Short circuit GND" 3 "Invalid" ;
VAL_ 169 BCMFL_Refrigerant_Temp_Sensor_St 0 "Normal" 1 "Short circuit Battery" 2 "Short circuit GND" 3 "Invalid" ;
VAL_ 169 BCMFL_PT_Sensor1_Pressure_Sts 0 "Normal" 1 "Short circuit Battery" 2 "Short circuit GND" 3 "Invalid" ;
VAL_ 169 BCMFL_PT_Sensor2_Pressure_Sts 0 "Normal" 1 "Short circuit Battery" 2 "Short circuit GND" 3 "Invalid" ;
VAL_ 201 FMCU_StsMCUFault 0 "No Fault" 1 "Fault level 1" 2 "Fault level 2" 3 "Fault level 3" 4 "Fault level 4" 5 "Fault level 5" 6 "Fault level 6" ;
VAL_ 201 FMCU_MotorSpdSts 0 "Valid" 1 "Invalid" ;
VAL_ 201 FMCU_MotorTqSts 0 "Valid" 1 "Invalid" ;
VAL_ 201 FMCU_CVC_CtrlMode 0 "Inactive" 1 "Torque control mode" 2 "Speed Control mode" 3 "Limphome" 4 "crawling" ;
VAL_ 201 FMCU_CVC_StsMode 0 "Init" 1 "LvStandby 12V" 5 "Standby" 6 "Torq" 7 "Speed" 9 "ActiveDischarge" 10 "Fault" 11 "PowerOff" 12 "AfterRun" ;
VAL_ 203 RMCU_StsMCUFault 0 "No Fault" 1 "Fault level 1" 2 "Fault level 2" 3 "Fault level 3" 4 "Fault level 4" 5 "Fault level 5" 6 "Fault level 6" ;
VAL_ 203 RMCU_MotorSpdValid 0 "Valid" 1 "Invalid" ;
VAL_ 203 RMCU_MotorTqValid 0 "Valid" 1 "Invalid" ;
VAL_ 203 RMCU_CVC_CtrlMode 0 "Inactive" 1 "Torque control mode" 2 "Speed Control mode" 3 "Limphome" 4 "crawling" ;
VAL_ 203 RMCU_CVC_StsMode 0 "Init" 1 "LvStandby 12V" 5 "Standby" 6 "Torq" 7 "Speed" 9 "ActiveDischarge" 10 "Fault" 11 "PowerOff" 12 "AfterRun" ;
VAL_ 217 CVC_HVsystem_status 0 "Not ready" 1 "HV On" 2 "ReadyToDrive" 3 "Charging" 4 "Error" 5 "Reserved" 6 "Reserved" 7 "Reserved" ;
VAL_ 217 CVC_ACPD_Percent_Valid 0 "Valid" 1 "Invalid" ;
VAL_ 217 CVC_ACTGear 0 "P" 1 "R" 2 "N" 3 "D" 4 "Reserved" 5 "Reserved" 6 "Reserved" 7 "Fault" ;
VAL_ 217 CVC_ACTGearValid 0 "Valid" 1 "Invalid" ;
VAL_ 217 CVC_ACT_DriveMode 0 "Normal mode" 1 "ECO mode" 2 "Sport mode" 3 "Reserved" 4 "Reserved" 5 "Reserved" 6 "Reserved" 7 "Invalid" ;
VAL_ 217 CVC_ACT_DriveMode_Valid 0 "Valid" 1 "Invalid" ;
VAL_ 217 CVC_HV_DRVsystem_status 0 "Not available" 1 "Normal" 2 "Degration" 3 "Limphome" 4 "Error" 5 "Reserved" 6 "Reserved" 7 "Reserved" ;
VAL_ 217 CVC_Recu_BrakeLight_ON_Req 0 "Brake light OFF" 1 "Brake light ON" 2 "Reserved" 3 "Signal not available" ;
VAL_ 258 STAT_CrankRelayHW_BCM 0 "OFF" 1 "ON" 2 "Reserved" 3 "Signal invalid" ;
VAL_ 258 CVC_Transport_Mode 0 "OFF" 1 "ON" 2 "Reserved" 3 "Invalid" ;
VAL_ 258 CVC_Vehicle_Special_Mode 0 "None" 1 "Camp mode" 2 "Pet mode" 3 "Showroom mode" 4 "Tow mode" 5 "Reserved" 6 "Reserved" 7 "Signal invalid" ;
VAL_ 258 CVC_Acc_Mode_Req 0 "No request" 1 "ACC state request" 2 "Reserved" 3 "Signal invalid" ;
VAL_ 258 CVC_CL30s_Req 0 "OFF" 1 "ON" 2 "Reserved" 3 "Invalid" ;
VAL_ 258 CVC_CL30c_Req 0 "OFF" 1 "ON" 2 "Reserved" 3 "Invalid" ;
VAL_ 258 CVC_CLR_Req 0 "OFF" 1 "ON" 2 "Reserved" 3 "Invalid" ;
VAL_ 258 CVC_CL15_Req 0 "OFF" 1 "ON" 2 "Reserved" 3 "Invalid" ;
VAL_ 258 Warning_Clamp_Incompatible 0 "None" 1 "Alert" 2 "Reserved" 3 "Reserved" ;
VAL_ 258 CVC_CL58_Req 0 "OFF" 1 "ON" 2 "Reserved" 3 "Invalid" ;
VAL_ 260 SOH_SUL_STATE 0 "Not learned" 1 "Learned" 2 "Reserved" 3 "Signal invalid" ;
VAL_ 260 SOC_STATE 0 "deviation > 15%" 1 "deviation < 15%" 2 "deviation < 10%" 3 "invalid" ;
VAL_ 260 Resp_Error 0 "No Error" 1 "Error" ;
VAL_ 260 FLAG_INCONSTENCY 0 "No battery inconsistency" 1 "Battery inconsistency" ;
VAL_ 260 EBS_error 0 "No Error" 1 "Error" ;
VAL_ 260 FLAG_DISCONNECT 0 "No battery disconnection" 1 "Battery disconnection" ;
VAL_ 262 Body_DayRunningLampSts 0 "OFF" 1 "ON" 2 "Fault (Reserved)" 3 "Signal Invalid" ;
VAL_ 262 Body_ReverseLightSts 0 "OFF" 1 "ON" 2 "Fault (Reserved)" 3 "Signal Invalid" ;
VAL_ 262 Body_StopLightSts 0 "OFF" 1 "ON" 2 "Fault (Reserved)" 3 "Signal Invalid" ;
VAL_ 262 Body_LicensePlateLightSts 0 "OFF" 1 "ON" 2 "Fault (Reserved)" 3 "Signal Invalid" ;
VAL_ 262 Body_Fr_Dimming_dome_lampSts 0 "OFF" 1 "ON" 2 "Fault (Reserved)" 3 "Signal Invalid" ;
VAL_ 262 Body_Rr_Dimming_dome_lampSts 0 "OFF" 1 "ON" 2 "Fault (Reserved)" 3 "Signal Invalid" ;
VAL_ 262 Body_STAT_InteriorLight 0 "OFF" 1 "ON" 2 "Reserved" 3 "Signal invalid" ;
VAL_ 262 Body_STAT_LightActivation 0 "OFF" 1 "PositionLight" 2 "LowBeam" 3 "AutoLight" 4 "Reserved" 5 "Reserved" 6 "Reserved" 7 "Signal invalid" ;
VAL_ 262 Body_HighBeamSts 0 "OFF" 1 "ON" 2 "Fault (Reserved)" 3 "Signal Invalid" ;
VAL_ 262 Body_LowBeamSts 0 "OFF" 1 "ON" 2 "Fault (Reserved)" 3 "Signal Invalid" ;
VAL_ 262 Body_RearFogLmpSts 0 "OFF" 1 "ON" 2 "Fault (Reserved)" 3 "Signal Invalid" ;
VAL_ 262 Body_FrntFogLmpSts 0 "OFF" 1 "ON" 2 "Fault (Reserved)" 3 "Signal Invalid" ;
VAL_ 262 Body_PosLmpSts 0 "OFF" 1 "ON" 2 "Fault (Reserved)" 3 "Signal Invalid" ;
VAL_ 262 Body_HornSts 0 "OFF" 1 "ON" 2 "Fault (Reserved)" 3 "Signal Invalid" ;
VAL_ 262 Body_TurnIndicatorSts 0 "OFF" 1 "Left On" 2 "Right On" 3 "Left and Right On" ;
VAL_ 264 SS_P_Button 0 "Not Pressed" 1 "Pressed" 2 "Reserved" 3 "Invalid" ;
VAL_ 264 SS_TargetGearReq 0 "No Request" 1 "N1" 2 "N2" 3 "R" 4 "D" 5 "Reserved" 6 "Reserved" 7 "Invalid" ;
VAL_ 264 SS_ADAS_Req 0 "No Request" 1 "Action 1 request" 2 "Action 2 request" 3 "Action 3 request" 4 "Action 4 request" 5 "Reserved" 6 "Reserved" 7 "Invalid" ;
VAL_ 264 SS_DrvMd_RgnLvl_Req 0 "No Request" 1 "Revole UP" 2 "Revole DOWN" 3 "Revole Invalid" ;
VAL_ 264 SS_Fault 0 "normal" 1 "Shifter failure" 2 "CAN communication fail" 3 "Position sensor failure" 4 "Supply voltage failure" 5 "P button fault" 6 "Received Date from BCM is invalid" 7 "MCU FAULT" 8 "Reserved" 9 "Reserved" 10 "Reserved" 11 "Reserved" 12 "Reserved" 13 "Reserved" 14 "Reserved" 15 "Reserved" ;
VAL_ 264 SS_HighBeam_Req 0 "No Request" 1 "Manual High beam Request" 2 "Flashing high beam" 3 "Invalid" ;
VAL_ 264 SS_Lane_Change_Indicator_Req 0 "OFF" 1 "Left lane change" 2 "Right lane change" 3 "Left On" 4 "Right On" 5 "Reserved" 6 "Reserved" 7 "Invalid" ;
VAL_ 264 SS_FR_RR_WashAndMist_Req 0 "No request" 1 "Rotate Upward Short Hold" 2 "Rotate Upward Long Hold" 3 "Rotate Downward Short Hold" 4 "Rotate Downward Long Hold" 5 "Reserved" 6 "Reserved" 7 "Invalid" ;
VAL_ 264 SS_RR_WiperControl_Req 0 " No action" 1 "Button push" 2 "Reserved" 3 "Invalid" ;
VAL_ 264 SS_FR_Wipercontrol_Req 0 "OFF" 1 "Mode 1" 2 "Mode 2" 3 "Mode 3" 4 "Invalid" ;
VAL_ 265 Body_STAT_BrakeSwitch 0 "Brake not pressed" 1 "Brake Pressed" 2 "Reserved" 3 "Signal invalid" ;
VAL_ 265 Body_STAT_HazardWarn 0 "Not active" 1 "Active" 2 "Reserved" 3 "Signal invalid" ;
VAL_ 265 Body_STAT_Autowiping 0 "OFF" 1 "ON" 2 "Reserved" 3 "Signal invalid" ;
VAL_ 265 Body_TurnIndicator 0 "OFF" 1 "Left" 2 "Right" 3 "Signal invalid" ;
VAL_ 266 LV_BatteryType 0 "Lead Acid Battery" 1 "Lithium Battery" 2 "Reversed" 3 "Invalid" ;
VAL_ 180 BCMFL_WindowsFL_AntiPinch_Warn 0 "No error" 1 "Anti-pinch FL window" 2 "Error" 3 "Invalid" ;
VAL_ 180 BCMFL_WindowFL_Learning_Sts 0 "Invalid" 1 "FL window done" 2 "FL window failure" 3 "FL window learning" ;
VAL_ 180 BCMFL_WindowFL_Suppression_Warn 0 "OFF" 1 "Suppressed" 2 "Not suppressed" ;
VAL_ 180 BCMFL_WindowFL_LockActive 0 "Not Activate" 1 "Activated" ;
VAL_ 180 BCMFL_WindowFL_ThermalProtect 0 "OFF" 1 "Level 1" 2 "Level 2" ;
VAL_ 180 BCMFL_WindowFL_Error 0 "None" 1 "Window Error FL" ;
VAL_ 180 BCMFL_WindowsRL_AntiPinch_Warn 0 "No error" 1 "Anti-pinch RL window" 2 "Error" 3 "Invalid" ;
VAL_ 180 BCMFL_WindowRL_LockActive 0 "Not Activate" 1 "Activated" ;
VAL_ 180 BCMFL_WindowRL_Error 0 "None" 1 "Window Error RL" ;
VAL_ 180 BCMFL_WindowRL_Learning_Sts 0 "Invalid" 1 "RL window done" 2 "RL window failure" 3 "RL window learning" ;
VAL_ 180 BCMFL_WindowRL_Suppression_Warn 0 "OFF" 1 "Suppressed" 2 "Not suppressed" ;
VAL_ 180 BCMFL_WindowRL_ThermalProtect 0 "OFF" 1 "Level 1" 2 "Level 2" ;
VAL_ 180 Window_Position_FL 0 "Unknown" 1 "Closed (top) 0%" 2 "Position2(10%)" 3 "Position3(20%)" 4 "Position4(30%)" 5 "Position5(40%)" 6 "Position6(50%)" 7 "Position7(60%)" 8 "Position8(70%)" 9 "Position9(80%)" 10 "Position10(90%)" 11 "Soft Stop(95%)" 12 "Open (bottom) 100%" 13 "Reserved" 14 "Reserved" 15 "Signal Invalid" ;
VAL_ 180 Window_Position_RL 0 "Unknown" 1 "Closed (top) 0%" 2 "Position2(10%)" 3 "Position3(20%)" 4 "Position4(30%)" 5 "Position5(40%)" 6 "Position6(50%)" 7 "Position7(60%)" 8 "Position8(70%)" 9 "Position9(80%)" 10 "Position10(90%)" 11 "Soft Stop(95%)" 12 "Open (bottom) 100%" 13 "Reserved" 14 "Reserved" 15 "Signal Invalid" ;
VAL_ 180 BCMFL_WindowBtnPress_RL 0 "No action" 1 "Pull up 1st stage" 2 "Pull up 2nd stage" 3 "Press down 1st stage" 4 "Press down 2nd stage" ;
VAL_ 180 BCMFL_WindowBtnPress_FL 0 "No action" 1 "Pull up 1st stage" 2 "Pull up 2nd stage" 3 "Press down 1st stage" 4 "Press down 2nd stage" ;
VAL_ 180 BCMFL_WindowFL_Malfunction_Warn 0 "No Error" 1 "Error" 2 "Reserved" 3 "Invalid" ;
VAL_ 180 BCMFL_WindowRL_Malfunction_Warn 0 "No Error" 1 "Error" 2 "Reserved" 3 "Invalid" ;
VAL_ 530 BCM_SideMarkerSts 0 "OFF" 1 "ON" 2 "Reserved" 3 "Invalid" ;
VAL_ 530 BCM_TurnIndicator_FR_STS 0 "OFF" 1 "ON" 2 "Reserved" 3 "Signal Invalid" 4 "Fault" ;
VAL_ 530 BCM_PositionLight_FR_STS 0 "OFF" 1 "ON" 2 "Reserved" 3 "Signal Invalid" 4 "Fault" ;
VAL_ 530 BCM_FrontFogLamp_FR_STS 0 "OFF" 1 "ON" 2 "Reserved" 3 "Signal Invalid" 4 "Fault" ;
VAL_ 530 BCM_DaytimeRunningLight_FR_Sts 0 "OFF" 1 "ON" 2 "Reserved" 3 "Signal Invalid" 4 "Fault" ;
VAL_ 530 BCM_MirrorLED_FR_STS 0 "OFF" 1 "ON" 2 "Reserved" 3 "Signal Invalid" 4 "Fault" ;
VAL_ 530 BCM_LowBeam_FR_Sts 0 "OFF" 1 "ON" 2 "Reserved" 3 "Signal Invalid" 4 "Fault" ;
VAL_ 530 BCM_HighBeam_FR_Sts 0 "OFF" 1 "ON" 2 "Reserved" 3 "Signal Invalid" 4 "Fault" ;
VAL_ 267 TrailerInput 0 "Trailer synchronous with CAN" 1 "Trailer synchronous with HW input" 2 "Reserved" 3 "Invalid" ;
VAL_ 267 TrailerSystemError 0 "No error" 1 "Error" 2 "Reserved" 3 "Invalid" ;
VAL_ 267 TRM_VoltageStatus 0 "No failure" 1 "Overvoltage" 2 "Undervoltage" 3 "Invalid" ;
VAL_ 267 TRM_STAT_BrakeLight 0 "OFF" 1 "ON" 2 "Reserved" 3 "Signal invalid" ;
VAL_ 267 TRM_STAT_FogLampRear 0 "OFF" 1 "ON" 2 "Failure" 3 "Signal invalid" ;
VAL_ 267 TRM_STAT_PositionLight 0 "PositionLight OFF" 1 "PositionLight ON" 2 "PositionLight failure" 3 "Signal invalid" ;
VAL_ 267 TRM_STAT_TurnIndicators 0 "OFF" 1 "Left turn lamp ON" 2 "Right turn lamp ON" 3 "Both turn lamps ON" 4 "Left turn lamp defect" 5 "Right turn lamp defect" 6 "Both turn lamp defect" 15 "Signal invalid" ;
VAL_ 267 TRM_STAT_ReverseLight 0 "OFF" 1 "ON" 2 "Reserved" 3 "Signal invalid" ;
VAL_ 267 TRM_STAT_HWBrakeLightInput 0 "Brakel Light Input not active TRM" 1 "Brakel Light Input active TRM" 2 "Reserved" 3 "Signal invalid" ;
VAL_ 267 TRM_STAT_HWIndicatorInput 0 "Indicator Input not active TRM" 1 "Indicator Input active TRM" 2 "Reserved" 3 "Signal invalid" ;
VAL_ 267 TRM_STAT_HWPosLightInput 0 "PosLight nput not active TRM" 1 "PosLight input active TRM" 2 "Reserved" 3 "Signal invalid" ;
VAL_ 273 CVC_F_RegenTrqMaxValid 0 "Invalid" 1 "valid" ;
VAL_ 273 CVC_R_RegenTrqMaxValid 0 "Invalid" 1 "valid" ;
VAL_ 273 CVC_F_BrkRegenTrqActualValid 0 "Invalid" 1 "valid" ;
VAL_ 273 CVC_R_BrkRegenTrqActualValid 0 "Invalid" 1 "valid" ;
VAL_ 273 CVC_OnePedalModeSts 0 "Inactive" 1 "Standby" 2 "Active" 3 "Invalid" ;
VAL_ 273 CVC_OnePedalModeEnable 0 "Disable" 1 "Enable" 2 "Reserved" 3 "Invalid" ;
VAL_ 274 CVC_STAT_BLS 0 "BLS not pressed" 1 "BLS pressed" 2 "Reserved" 3 "Signal invalid" ;
VAL_ 274 Vehicle_Operation_State 0 "OFF(Comfort Enable)" 1 "ACC (Park)" 2 "ON (Driver Present)" 3 "Engine start (eMotor running)" 4 "SW Update OTA" 5 "Reserved" 6 "Reserved" 7 "Signal Invalid" ;
VAL_ 279 WCBS_CircuitPressValid 0 "Valid" 1 "Invalid" ;
VAL_ 279 WCBS_EstWhlPressValid 0 "Valid" 1 "Invalid" ;
VAL_ 279 WCBS_MainCylinderPressValid 0 "Valid" 1 "Invalid" ;
VAL_ 289 WCBS_RRWheelSpeedValid 0 "Valid" 1 "Invalid" ;
VAL_ 289 WCBS_RRWheelDirection 0 "Invalid" 1 "Forward" 2 "Backward" 3 "Stop" ;
VAL_ 289 WCBS_RLWheelDirection 0 "Invalid" 1 "Forward" 2 "Backward" 3 "Stop" ;
VAL_ 289 WCBS_RLWheelSpeedValid 0 "Valid" 1 "Invalid" ;
VAL_ 290 WCBS_FRWheelSpeedValid 0 "Valid" 1 "Invalid" ;
VAL_ 290 WCBS_FRWheelDirection 0 "Invalid" 1 "Forward" 2 "Backward" 3 "Stop" ;
VAL_ 290 WCBS_FLWheelDirection 0 "Invalid" 1 "Forward" 2 "Backward" 3 "Stop" ;
VAL_ 290 WCBS_FLWheelSpeedValid 0 "Valid" 1 "Invalid" ;
VAL_ 292 WCBS_FLWheelSpeedRCSts 0 "Valid" 1 "Invalid" ;
VAL_ 292 WCBS_RLWheelSpeedRCSts 0 "Valid" 1 "Invalid" ;
VAL_ 292 WCBS_FRWheelSpeedRCSts 0 "Valid" 1 "Invalid" ;
VAL_ 292 WCBS_RRWheelSpeedRCSts 0 "Valid" 1 "Invalid" ;
VAL_ 306 ESC_HSA_Control_Status 0 "Inactive" 1 "Active" ;
VAL_ 306 ESC_HSA_Status_Fault 0 "HSA Normale" 1 "HSA Defective" ;
VAL_ 306 ESC_TcsEnableSts 0 "Enabled" 1 "Disabled" ;
VAL_ 306 ESC_EscCtrlActv 0 "Inactive" 1 "Active" ;
VAL_ 306 ESC_TcsCtrlActv 0 "Inactive" 1 "Active" ;
VAL_ 306 ESC_EscFlgFlt 0 "No failure" 1 "Failure" ;
VAL_ 306 ESC_TcsFlgFlt 0 "No failure" 1 "Failure" ;
VAL_ 306 ESC_EscEnableSts 0 "Enabled" 1 "Disabled" ;
VAL_ 306 ESC_HBAFlgFlt 0 "No failure" 1 "Failure" ;
VAL_ 306 ESC_HbaCtrlActv 0 "Inactive" 1 "Active" ;
VAL_ 306 ESC_DTC_Active 0 "Inactive" 1 "Active" ;
VAL_ 306 ESC_BTCSCtrlActv 0 "Inactive" 1 "Active" ;
VAL_ 306 ESC_EngineCtrlActv 0 "Inactive" 1 "Active" ;
VAL_ 311 EAS_StiffStsFL 0 "soft" 1 "hard" ;
VAL_ 311 EAS_StiffStsFR 0 "soft" 1 "hard" ;
VAL_ 311 EAS_StiffStsRL 0 "soft" 1 "hard" ;
VAL_ 311 EAS_StiffStsRR 0 "soft" 1 "hard" ;
VAL_ 311 EAS_WorkSts 0 "Normal" 1 "warning" 2 "Limited" 3 "Stop" ;
VAL_ 311 CDC_WorkSts 0 "Normal" 1 "warning" 2 "Limited" 3 "Stop" ;
VAL_ 311 EAS_CDC_SystemWorkMode 0 "Normal" 1 "Transportation mode" 2 "Maintenance mode" 3 "Reserved" ;
VAL_ 311 EAS_SuspensionMode 0 "Low" 1 "Standard" 2 "High" 3 "Auto" ;
VAL_ 311 EAS_EasyAccessSts 0 "ON" 1 "OFF" 2 "Invalid" 3 "Invalid" ;
VAL_ 311 CDC_DamperMode 0 "Comfort" 1 "Standard" 2 "Sport" 3 "Reserved" ;
VAL_ 311 EAS_ValveValue_FL 0 "close" 1 "insufflation" 2 "deflate" 3 "PreCheck" 4 "error" 7 "invalid" ;
VAL_ 311 EAS_ValveValue_FR 0 "close" 1 "insufflation" 2 "deflate" 3 "PreCheck" 4 "error" 7 "invalid" ;
VAL_ 311 EAS_ValveValue_RL 0 "close" 1 "insufflation" 2 "deflate" 3 "PreCheck" 4 "error" 7 "invalid" ;
VAL_ 311 EAS_ValveValue_RR 0 "close" 1 "insufflation" 2 "deflate" 3 "PreCheck" 4 "error" 7 "invalid" ;
VAL_ 311 EAS_EnableSts 0 "Enable" 1 "Disable" ;
VAL_ 311 CDC_ValveValue_FL 0 "Normal" 1 "Error" ;
VAL_ 311 CDC_ValveValue_FR 0 "Normal" 1 "Error" ;
VAL_ 311 CDC_ValveValue_RL 0 "Normal" 1 "Error" ;
VAL_ 311 CDC_ValveValue_RR 0 "Normal" 1 "Error" ;
VAL_ 311 EAS_MntnSts 0 "Normal Status" 1 "maintenance Status" ;
VAL_ 311 EAS_EasyLoadingSetFb 0 "Initializing" 1 "OFF" 2 "ON" 3 "Reserved" ;
VAL_ 311 EAS_LiftModFb 0 "No Lift and Jack" 1 "AutoLift Mode" 2 "AutoJack Mode" 3 "invalid" ;
VAL_ 311 EAS_VehicleUpDownState 0 "stangby" 1 "up" 2 "down" 3 "Reserved" ;
VAL_ 311 EAS_Overheat_Warning 0 "No failure" 1 "Warnig for overheat" ;
VAL_ 311 EAS_VehiclePositionState 0 "Initializing" 1 "High" 2 "Middle" 3 "Low" 4 "easy Entry level" 5 "easy Loading level" 6 "Reserved" ;
VAL_ 311 EAS_VehicleTargetPositionState 0 "Initializing" 1 "High" 2 "Middle" 3 "Low" 4 "easy Entry level" 5 "easy Loading level" 6 "Reserved" ;
VAL_ 357 CVC_AcChgGunIn 0 "disconnect" 1 "connect" ;
VAL_ 357 CVC_DCChgGunIn 0 "disconnect" 1 "connect" ;
VAL_ 372 BMS_StartOfMeasument_STS 0 "Not start" 1 "Started" ;
VAL_ 372 BMS_CVC_Insulation_Mon_Sts 0 "ON" 1 "OFF" ;
VAL_ 382 SAS_SASStsSnsr 0 "sensor value Invalid" 1 "sensor value valid" ;
VAL_ 382 SAS_SteerWhlRotSpdStatus 0 "Invalid" 1 "Valid" ;
VAL_ 382 SAS_SASFailure 0 "Failure" 1 "No Failure" ;
VAL_ 382 SAS_Calibrated 0 "Not Calibrated" 1 "Calibrated" ;
VAL_ 382 SAS_SteerWheelAngleValid 0 "Valid" 1 "Invalid" ;
VAL_ 466 FCAM_TSR_SLWSwtResp 0 "Off" 1 "On" ;
VAL_ 466 FCAM_FC_CalibrationSts 0 "Calibration Success" 1 "Calibration In Process" 2 "Calibration Failed" 3 "Reserved" ;
VAL_ 466 FCAM_BlockageSts 0 "Front Camera Not Blockage" 1 "Front Camera Blockage" ;
VAL_ 466 FCAM_AEB_ABA_Req 0 "No Request" 1 "Request" ;
VAL_ 466 FCAM_AEB_AWB_Req 0 "No Request" 1 "Request" ;
VAL_ 466 FCAM_AEB_TgtDecel_Req 0 "No Request" 1 "Request" ;
VAL_ 466 FCAM_AEB_VehHldReq 0 "No Request" 1 "Request" ;
VAL_ 466 FCAM_AEB_AWB_Level 0 "No level" 1 "Level 1" 2 "Level 2" 3 "Level 3" 4 "Level 4" 5 "Reserved" 6 "Reserved" 7 "Reserved" 8 "Reserved" 9 "Reserved" 10 "Reserved" 11 "Reserved" 12 "Reserved" 13 "Reserved" 14 "Reserved" 15 "Reserved" ;
VAL_ 507 Driver_SeatbeltBuckleStatus 0 "Not_buckled" 1 "Buckled" 2 "Not_Available" 3 "ailure" ;
VAL_ 507 Passenger_SeatbeltBuckleStatus 0 "Not_buckled" 1 "Buckled" 2 "Not_Available" 3 "ailure" ;
VAL_ 507 CVC_2nd_Dri_SeatbeltBuckleStatus 0 "Not_buckled" 1 "Buckled" 2 "Not_Available" 3 "ailure" ;
VAL_ 507 CVC_2nd_Pas_SeatbeltBuckleStatus 0 "Not_buckled" 1 "Buckled" 2 "Not_Available" 3 "ailure" ;
VAL_ 507 CVC_2nd_Mid_SeatbeltBuckleStatus 0 "Not_buckled" 1 "Buckled" 2 "Not_Available" 3 "ailure" ;
VAL_ 507 Driver_SeatbeltOccupantStatus 0 "eat_Not_Occupied" 1 "Seat Occupied" 2 "Not_Available" 3 "Failure" ;
VAL_ 507 Passenger_SeatbeltOccupantStatus 0 "eat_Not_Occupied" 1 "Seat Occupied" 2 "Not_Available" 3 "Failure" ;
VAL_ 507 Dri_SeatbeltOccupantStatus_2nd 0 "eat_Not_Occupied" 1 "Seat Occupied" 2 "Not_Available" 3 "Failure" ;
VAL_ 507 Pas_SeatbeltOccupantStatus_2nd 0 "eat_Not_Occupied" 1 "Seat Occupied" 2 "Not_Available" 3 "Failure" ;
VAL_ 507 Mid_SeatbeltOccupantStatus_2nd 0 "eat_Not_Occupied" 1 "Seat Occupied" 2 "Not_Available" 3 "Failure" ;
VAL_ 507 CVC_Seatbelt_Reminder_Request 0 "Seatbelt reminder NOT activated" 1 "Seatbelt reminder activated" ;
VAL_ 507 CVC_SBR_Chime_Req 0 "No Active Chime" 1 "Active Chime" ;
VAL_ 507 CVC_SBR_Blinking_Req 0 "No Blinking" 1 "Blinking 1Hz" ;
VAL_ 522 ETG_Lift_Gate_Status 0 "Fully closed" 1 "Fully opened" 2 "Stopped halfway at Area 1" 3 "Stopped halfway at Area 2" 4 "Stopped halfway at Area 3" 5 "Ready to open" 6 "Opening" 7 "Ready to close" 8 "Closing" 9 "SNA (Signal not available)" ;
VAL_ 522 ETG_Power_Latch_Status 0 "uninitialized" 1 "Stoped" 2 "Cinching" 3 "Cinching reset" 4 "Releasing" 5 "Releasing reset" 7 "SNA" ;
VAL_ 522 ETG_Latch_Segment 0 "Full latch" 1 "Half latch" 2 "Open latch" 3 "SNA" ;
VAL_ 522 ETG_DSW_Status 0 "Not active" 1 "Active" ;
VAL_ 522 ETG_GSW_Status 0 "Not active" 1 "Active" ;
VAL_ 522 ETG_LTS_Status 0 "Not active" 1 "Active" ;
VAL_ 522 ETG_RTS_Status 0 "Not active" 1 "Active" ;
VAL_ 522 ETG_HAL_Status 0 "Low level" 1 "High level" ;
VAL_ 522 ETG_FUL_Status 0 "Low level" 1 "High level" ;
VAL_ 522 ETG_AJR_Status 0 "Low level(Open)" 1 "High level(Close)" ;
VAL_ 522 ETG_NTL_Status 0 "Low level" 1 "High level" ;
VAL_ 522 ETG_ERR_Voltage 0 "Normal" 1 "Under voltage" 2 "Over voltage" ;
VAL_ 522 ETG_ERR_Left_Motor 0 "Normal" 1 "Open circuit" 2 "short circuit" ;
VAL_ 522 ETG_ERR_Right_Motor 0 "Normal" 1 "Open circuit" 2 "short circuit" ;
VAL_ 522 ETG_ERR_Latch 0 "Normal" 1 "Open circuit" 2 "short circuit" ;
VAL_ 522 ETG_ERR_Hall 0 "Normal" 1 "Hall power short circuit" 2 "Hall position out of range" 3 "Hall signal out of sync" ;
VAL_ 522 ETG_Lift_Motor_Stall 0 "Not active" 1 "Active" ;
VAL_ 522 ETG_Lift_Motor_AntiPinch 0 "Not active" 1 "Active" ;
VAL_ 522 ETG_Lift_Motor_Thermal 0 "Not active" 1 "Active" ;
VAL_ 522 ETG_Power_Latch_Thermal 0 "Not active" 1 "Active" ;
VAL_ 522 ETG_Abuse_Protection 0 "Not active" 1 "Active" ;
VAL_ 524 CVC_OdometerV 0 "valid" 1 "invalid" ;
VAL_ 525 ABSFailed 0 "No fault" 1 "Fault" ;
VAL_ 525 ABSActive 0 "Inactive" 1 "Active" ;
VAL_ 525 ESC_VehicleStandstill 0 "NO_VEHICLE_STANDSTILL" 1 "VEHICLE_STANDSTILL" ;
VAL_ 525 WCBS_VehicleSpeedValid 0 "Valid" 1 "Invalid" ;
VAL_ 525 ESC_VehicleHoldStat 0 "No vehicle hold" 1 "vehicle hold" 2 "reserved" 3 "reserved" ;
VAL_ 525 ABS_EBDFailed 0 "EBD Normal" 1 "EBD Failed" ;
VAL_ 525 ABS_HAZActive 0 "Emergency brake light off" 1 "Emergency brake light on" ;
VAL_ 525 ABS_LowBrakeFluid 0 "no failure" 1 "failure" ;
VAL_ 525 EBDActive 0 "Inactive" 1 "Active" ;
VAL_ 525 WCBS_Veh_DriveCondition 0 "Vehicle is stationary" 1 "Vehicle is moving forward" 2 "Vehicle is moving reverse" 3 "Vehicle is stationary rear axle rol" 4 "Vehicle is stationary front axle roll" 5 "Vehicle is stationary all axle roll" 6 "reserved" 7 "Signal invalid" ;
VAL_ 533 BMS_BatBalance_ERR 0 "Error" 1 "normal" ;
VAL_ 533 BMS_Balance_STS 0 "Inactive" 1 "active" ;
VAL_ 533 BMS_IGN_Sts 0 "OFF" 1 "ON" ;
VAL_ 533 BMS_HWCrash_Sts 0 "No Crash" 1 "Crash" ;
VAL_ 533 BMS_HVIL_STS 0 "Closed" 1 "Open & short to battery" 2 "short to ground" 3 "Signal invalid" ;
VAL_ 533 BMS_HVOnOff_STS 0 "HV Off" 1 "Precharge" 2 "HV On" 3 "Fail to HV on" ;
VAL_ 533 BMS_ERR_LEV 0 "No error" 1 "Warning" 2 "Limp Home" 3 "Power down without FTTI" 4 "Delay power down with FTTI" 5 "Emergency off condition" 6 "Fault, needs to shutdown and wakeup" 7 "Battery locked - reserved" ;
VAL_ 533 BMS_Sys_STS 0 "Initialization of power on, self-checking" 1 "Self-check passes, can be high-voltage" 2 "Successful High Voltage Power Up" 3 "Successful Power Down of HV" 4 "Power Down process" 5 "Successful Power Down" 6 "BCU Sleep mode" 7 "Failure, unable to operate" 8 "Invalid" ;
VAL_ 533 BMS_ISU_Status 0 "Normal (> 250 kOhms)" 1 "Level1 (<250 kOhms ~ >100 kOhms)" 3 "Level3 (<100 kOhms)" ;
VAL_ 533 BMS_HV_Sts 0 "HV Off" 1 "Pre Charge" 2 "HV On" 3 "Super_Fast_Charge" 4 "AC Charge" 5 "Undefined" 6 "Undefined" 7 "Undefined" 8 "Undefined" 9 "Undefined" ;
VAL_ 542 CVC_RearFogLampSts 0 "OFF" 1 "ON" 2 "Reserved" 3 "Signal Invalid" 4 "Fault" ;
VAL_ 542 CVC_ExteriorLightSts 0 "OFF" 1 "Parking" 2 "On" 3 "Auto" 4 "Invalid" ;
VAL_ 542 CVC_FollowMeHomeSts 0 "OFF" 1 "30 secs" 2 "60 secs" 3 "90 secs" 4 "120 secs" 5 "Signal Invalid" ;
VAL_ 542 CVC_WelcomeLightSts 0 "Vehicle Unlock" 1 "Driver walk toward" 2 "OFF" 3 "Signal invalid" ;
VAL_ 542 CVC_FrontFogLampSts 0 "OFF" 1 "ON" 2 "Reserved" 3 "Signal Invalid" 4 "Fault" ;
VAL_ 560 WCBS_BrkLampReq 0 "False" 1 "True" ;
VAL_ 560 EPB_SysWrnIndReq 0 "No Indication" 1 "Continuous Indication" 2 "FlashRate #1 Indication" ;
VAL_ 560 EPB_SysStatIndReq 0 "No Indication" 1 "Continuous Indication" 2 "FlashRate #1 Indication" ;
VAL_ 560 EPB_SysDspMsgReq 0 "Off" 1 "BrakeForceNotEnough" 2 "ParkBrkOverheat" 3 "ParkOnTooHighSlope" 4 "DAR_Nok_DoorOpen" 5 "Reserved" 6 "Reserved" 7 "Reserved" ;
VAL_ 560 EPB_Sts 0 "Unknown" 1 "Released" 2 "Locked" 3 "Releasing" 4 "Locking" ;
VAL_ 560 WCBS_TSMActive 0 "Trailermode active" 1 "Trailermode inactive" ;
VAL_ 560 EPB_CDPActive 0 "Off" 1 "Hydraulic CDP active" 2 "CDP via Caliper active" ;
VAL_ 560 EPB_Swch_Mafnc 0 "No Error" 1 "Error" ;
VAL_ 560 WCBS_Avh_Available 0 "AVH Available" 1 "AVH Not Available" ;
VAL_ 560 WCBS_AVH_DispMsg 0 "Off" 1 "AUTO HOLD to be deactivated Press brake pedal" 2 "Message #2" 3 "Message #3" 4 "Message #4" 5 "Message #5" 6 "Message #6" 7 "Message #7" ;
VAL_ 560 WCBS_AVH_Status 0 "AVH Off" 1 "AVH Standby" 2 "AVH Active" 3 "AVH Not Ready" ;
VAL_ 560 WCBS_EPB_Fault 0 "No Error" 1 "Error" ;
VAL_ 560 WCBS_ROMActive 0 "Inactive" 1 "Active" ;
VAL_ 560 WCBS_ROMFailure 0 "No Error" 1 "Error" ;
VAL_ 560 WCBS_TrailerDetected 0 "No Trailer connected" 1 "Trailer detected" ;
VAL_ 560 WCBS_TSMFailure 0 "No Error" 1 "Error" ;
VAL_ 560 WCBS_OnePedalAvailable 0 "Not available" 1 "Available" ;
VAL_ 560 WCBS_HDCCtrlsts 0 "OFF" 1 "No active braking" 2 "Active braking" 3 "reserved" ;
VAL_ 560 WCBS_HDC_displayWarnMsg 0 "No warning" 1 "HDC function not available due to fault" 2 "reserved" 3 "reserved" ;
VAL_ 560 WCBS_VehicleSteerSts 0 "Normal" 1 "Understeer" 2 "Oversteer" 3 "Signal Invalid" ;
VAL_ 560 WCBS_HDC_available 0 "HDC Not Available" 1 "HDC Available" ;
VAL_ 560 WCBS_HDC_SwitchSts 0 "HDC OFF" 1 "HDC ON" ;
VAL_ 560 WCBS_DTCFailure 0 "No Error" 1 "Error" ;
VAL_ 560 WCBS_TowMode_Feedback 0 "Inactive" 1 "Active" 3 "Reserved" ;
VAL_ 560 WCBS_SCM_available 0 "SCM Not Available" 1 "SCM Available" ;
VAL_ 560 WCBS_OnePedal_Active 0 "One pedal inactive" 1 "One pedal active" ;
VAL_ 560 WCBS_OnePedal_hold_state 0 "One pedal not hold" 1 "One pedal Hold" ;
VAL_ 560 WCBS_CDPFailSts 0 "No failure" 1 "Failure" ;
VAL_ 560 WCBS_CBC_Active 0 "Not Active" 1 "Active" ;
VAL_ 560 WCBS_CBC_Available 0 "Not Available" 1 "Available" ;
VAL_ 560 WCBS_SLS_Active 0 "Not Active" 1 "Active" ;
VAL_ 560 WCBS_SLS_Available 0 "Not Available" 1 "Available" ;
VAL_ 560 WCBS_TVBB_Active 0 "Not Active" 1 "Active" ;
VAL_ 560 WCBS_TVBB_Available 0 "Not Available" 1 "Available" ;
VAL_ 560 WCBS_BDW_Active 0 "Not Active" 1 "Active" ;
VAL_ 560 WCBS_BDW_Available 0 "Not Available" 1 "Available" ;
VAL_ 560 WCBS_SCMActive 0 "Inactive" 1 "Active" ;
VAL_ 561 DOW_DoorAjarStatusRL 0 "Closed" 1 "Opened" 2 "Faults" 3 "Invalid" ;
VAL_ 561 DOW_DoorAjarStatusFL 0 "Closed" 1 "Opened" 2 "Faults" 3 "Invalid" ;
VAL_ 561 CVC_ADAS_BonnetAjarStatus 0 "Closed" 1 "Opened" 2 "Faults" 3 "Invalid" ;
VAL_ 561 CVC_ADAS_TailgateAjarStatus 0 "Closed" 1 "Opened" 2 "Faults" 3 "Invalid" ;
VAL_ 565 TRM_TowingDetected 0 "Towing not detected" 1 "Towing detected" 3 "Invalid" ;
VAL_ 565 TRM_TrailerDetected 0 "Trailer not detected" 1 "Trailer detected" 3 "Invalid" ;
VAL_ 562 DriverDoor_Ajar_Sts 0 "Closed" 1 "Opened" 2 "Faults" 3 "Invalid" ;
VAL_ 562 CoDriverDoor_Ajar_Sts 0 "Closed" 1 "Opened" 2 "Faults" 3 "Invalid" ;
VAL_ 562 RearLeftDoor_Ajar_Sts 0 "Closed" 1 "Opened" 2 "Faults" 3 "Invalid" ;
VAL_ 562 RearRightDoor_Ajar_Sts 0 "Closed" 1 "Opened" 2 "Faults" 3 "Invalid" ;
VAL_ 562 Bonnet_Ajar_Sts 0 "Closed" 1 "Opened" 2 "Faults" 3 "Invalid" ;
VAL_ 562 Tailgate_Ajar_Sts 0 "Closed" 1 "Opened" 2 "Faults" 3 "Invalid" ;
VAL_ 562 DriverDoor_Lock_Sts 0 "Locked" 1 "Unlocked" 2 "Faults" 3 "Invalid" ;
VAL_ 562 CoDriverDoor_Lock_Sts 0 "Locked" 1 "Unlocked" 2 "Faults" 3 "Invalid" ;
VAL_ 562 RearLeftDoor_Lock_Sts 0 "Locked" 1 "Unlocked" 2 "Faults" 3 "Invalid" ;
VAL_ 562 RearRightDoor_Lock_Sts 0 "Locked" 1 "Unlocked" 2 "Faults" 3 "Invalid" ;
VAL_ 562 STAT_CDL_LED 0 "OFF" 1 "ON" 2 "blinking" 3 "Signal invalid" ;
VAL_ 571 CVC_ACPE_Actuator 0 "Standby" 1 "ACPE Armed-cut-off power" 2 "ACPE Armed-Limit power" 3 "ACPE intervene cut-off power" 4 "ACPE intervene limit power" 5 "ACPE Disengaging" 6 "Reserved" 7 "Invalid" ;
VAL_ 571 CVC_ACPE_PedalErrorEvent 0 "No Pedal Error event'" 1 "Pedal Misapplication Event" 2 "Reserved" 3 "Invalid" ;
VAL_ 571 CVC_ACPE_Available_Flag 0 "ECU No support function'" 1 "Not Available" 2 "Available" 3 "Invalid" ;
VAL_ 571 CVC_ACPE_Active_Flag 0 "Not Active" 1 "Active" ;
VAL_ 571 CVC_ACPE_HeathCheck 0 "Available'" 1 "Failure" 2 "Reserved" 3 "Invalid" ;
VAL_ 581 BMS_ProbeNumMaxCellTemp 0 "Invalid" 62 "Error" 63 "Invalid" ;
VAL_ 581 BMS_ProbeNumMinCellTemp 0 "Invalid" 62 "Error" 63 "Invalid" ;
VAL_ 584 DOW_DoorAjarStatusRR 0 "Closed" 1 "Opened" 2 "Faults" 3 "Invalid" ;
VAL_ 584 DOW_DoorAjarStatusFR 0 "Closed" 1 "Opened" 2 "Faults" 3 "Invalid" ;
VAL_ 624 WCBS_Fault_Status 0 "No Fault" 1 "Level 1 Fault(Function degradation, yellow light on)" 2 "Level 2Fault(Functional malfunction, red light on)" 3 "Braking function is normal, redundant system failure (text prompt)" ;
VAL_ 624 WCBS_IBS_Sys_Fault_Sts 0 "No Fault" 1 "Fault" ;
VAL_ 624 WCBS_BrkPedalValid 0 "Valid" 1 "Invalid" ;
VAL_ 624 WCBS_DiagMode 0 "Normal mode" 1 "Diagnosis mode" ;
VAL_ 624 WCBS_RollerBenchMode 0 "None" 1 "Alert" ;
VAL_ 624 WCBSActive 0 "Inactive" 1 "Active" ;
VAL_ 624 WCBS_EOL_NotDone 0 "None" 1 "Alert" ;
VAL_ 624 STAT_DSC 0 "Normal" 1 "Traction Mode OFF" 2 "ESC-OFF" 3 "Signal invalid" ;
VAL_ 624 WCBS_BLAFlt 0 "No Error" 1 "Error" ;
VAL_ 624 FBW_WarningSts 0 "No_failure" 1 "BrakeDisc_High_Temperature_Leve1" 2 "BrakeDisc_High_Temperature_Leve2" 3 "Not_Used" ;
VAL_ 624 WCBS_BrakesystemFailSts 0 "BBF_FullSys" 1 "BBF_DegradedPedalFeel" 2 "BBF_CircuitSperation" 3 "BBF_C1/2BoostOnlyd" 4 "HydBack_w/_act/HydBack_w/o_ac" ;
VAL_ 662 PDU_DCDC_StsCtrl 0 "DCDC_OFF" 1 "DCDC_STANDBY" 2 "DCDC_ON" 3 "DCDC_RESERVED" 4 "DCDC_DEGRAEDED" 5 "DCDC_FAULT_SHUTDOWN" 6 "DCDC_EMEGENCY_SHUTDOWN" 7 "DCDC_SNA" ;
VAL_ 674 DrvSeatMsgModeStat 0 "OFF" 1 "Wave Mode" 2 "Cat Paw Mode" 3 "Cross Mode" 4 "Relieve Mode" 5 "Jump Mode" 6 "Invalid" 7 "Not used" ;
VAL_ 674 LSSM_APumpFail 0 "Invalid" 1 "No Error" 2 "Error" 3 "Reserved" ;
VAL_ 674 DrvSeatMsgStrLvlStat 0 "OFF" 1 "Initial value" 2 "Level 1(Weak)" 3 "Level 2(General)" 4 "Level 3(Strong)" 5 "Not used" 6 "Not used" 7 "Not used" ;
VAL_ 674 PassSeatMsgModeStat 0 "OFF" 1 "Wave Mode" 2 "Cat Paw Mode" 3 "Cross Mode" 4 "Relieve Mode" 5 "Jump Mode" 6 "Invalid" 7 "Not used" ;
VAL_ 674 LSSM_BPumpFail 0 "Invalid" 1 "No Error" 2 "Error" 3 "Reserved" ;
VAL_ 674 PassSeatMsgStrLvlStat 0 "OFF" 1 "Initial value" 2 "Level 1(Weak)" 3 "Level 2(General)" 4 "Level 3(Strong)" 5 "Not used" 6 "Not used" 7 "Not used" ;
VAL_ 674 DrvSeatMsgModeStat_sec 0 "OFF" 1 "Wave mode" 2 "Cat Paw Mode" 3 "Cross Mode" 4 "Relieve Mode" 5 "Jump Mode" 6 "invalid" 7 "Not used" ;
VAL_ 674 LSSM_CPumpFail_sec_Drv 0 "Invalid" 1 "No Error" 2 "Error" 3 "Reserved" ;
VAL_ 674 DrvSeatMsgStrLvlStat_sec 0 "OFF" 1 "Initial value" 2 "Level 1(Weak)" 3 "Level 2(General)" 4 "Level 3(Strong)" 5 "Not used" 6 "Not used" 7 "Not used" ;
VAL_ 674 PsSeatMsgModeStat_sec 0 "OFF" 1 "Wave mode" 2 "Cat Paw Mode" 3 "Cross Mode" 4 "Relieve Mode" 5 "Jump Mode" 6 "invalid" 7 "Not used" ;
VAL_ 674 LSSM_CPumpFail_sec_Ps 0 "Invalid" 1 "No Error" 2 "Error" 3 "Reserved" ;
VAL_ 674 PsSeatMsgStrLvlStat_sec 0 "OFF" 1 "Initial value" 2 "Level 1(Weak)" 3 "Level 2(General)" 4 "Level 3(Strong)" 5 "Not used" 6 "Not used" 7 "Not used" ;
VAL_ 746 CVC_Fan_Sts 0 "Closed" 1 "Low Speed" 2 "High speed" ;
VAL_ 746 CVC_EdrivePump_Sts 0 "Not Work" 1 "Working" 2 "Fault" ;
VAL_ 746 CVC_BatPump_Sts 0 "Not Work" 1 "Working" 2 "Fault" ;
VAL_ 760 DISP_DATE_WDAY 1 "Monday" 2 "Tuesday" 3 "Wednesday" 4 "Thursday" 5 "Friday" 6 "Saturday" 7 "Sunday" 15 "Signal invalid" ;
VAL_ 760 ST_DISP_CTI_DATE 0 "data not valid" 1 "data valid" 3 "UTC" 5 "winter time" 6 "Manually set time" 7 "summer time" 15 "signal invalid" ;
VAL_ 768 CVC_STAT_SyncClimateZone 0 "OFF" 1 "ON" 2 "Reserved" 3 "Signal invalid" ;
VAL_ 768 CVC_STAT_Auto 0 "OFF" 1 "ON" 2 "Reserved" 3 "Signal invalid" ;
VAL_ 768 CVC_STAT_Aircondition 0 "OFF" 1 "ON" 2 "Reserved" 3 "Signal invalid" ;
VAL_ 768 CVC_STAT_IonButton 0 "OFF" 1 "ON" 2 "Reserved" 3 "Signal invalid" ;
VAL_ 768 CVC_STAT_MaxAc 0 "OFF" 1 "ON" 2 "Reserved" 3 "Signal invalid" ;
VAL_ 768 CVC_STAT_ClimateOnOff 0 "OFF" 1 "ON" 2 "Reserved" 3 "Signal invalid" ;
VAL_ 768 CVC_STAT_FanSpeed 0 "OFF" 1 "Level 1" 2 "Level 2" 3 "Level 3" 4 "Level 4" 5 "Level 5" 6 "Level 6" 7 "Reserved" 8 "Reserved" 9 "Reserved" 10 "Reserved" 11 "Reserved" 12 "Reserved" 13 "Reserved" 14 "Reserved" 15 "Signal invalid" ;
VAL_ 768 CVC_STAT_RecircFlap 0 "Inside" 1 "Outside" 2 "Auto" 3 "Signal invalid" ;
VAL_ 768 CVC_STAT_AirDistributionMode 0 "OFF" 1 "Vent" 2 "Vent/Foot" 3 "Foot" 4 "Foot/Defrost" 5 "Defrost" 6 "Default" 7 "Signal invalid" ;
VAL_ 768 CVC_STAT_Defrost 0 "OFF" 1 "ON" 2 "Reserved" 3 "Signal invalid" ;
VAL_ 768 CVC_STAT_PTC_Heater 0 "OFF" 1 "Stage 1" 2 "Stage 2" 3 "Stage 3" 4 "Reserved" 5 "Reserved" 6 "Reserved" 7 "Signal invalid" ;
VAL_ 768 CVC_CoolSysWarnLvl 0 "No fault" 1 "Level 1" 2 "Level 2" 3 "Level 3" 4 "Level 4" 5 "Level 5" 6 "Level 6" 7 "Signal invalid" ;
VAL_ 777 CPD_Warn_Initial_Start 0 "UNKNOWN" 1 "Initial Warning Start" ;
VAL_ 777 CPD_Warn_Initial_End 0 "UNKNOWN" 1 "Initial Warning Complete" ;
VAL_ 777 CPD_Warn_Escalated_Start 0 "UNKNOWN" 1 "Escalation Warning Start" ;
VAL_ 777 CPD_Warn_Escalated_End 0 "UNKNOWN" 1 "Escalation Warning Complete" ;
VAL_ 777 CPD_Warn_Cancel 0 "UNKNOWN" 1 "cancel initial warning" 2 "cancel escalation warning" ;
VAL_ 778 CVC_DKCU_PhoneLocationReq 0 "No request" 1 "Request phone location once" 2 "Start periodic phone location reporting" 3 "Stop periodic phone location reporting" ;
VAL_ 779 CVC_DKCU_Temp_Intervention_Fdbk 0 "UNKNOWN" 1 "Temperature Intervention Start" ;
VAL_ 779 CVC_DKCU_Remote_Phone_Interventi 0 "UNKNOWN" 1 "Phone Intervention Start" ;
VAL_ 787 POD_GTW_statusOBC 0 "OBC_OFF" 1 "OBC_STANDBY" 2 "OBC_ON_NORMAL" 3 "OBC_ON_VOLTAGE" 4 "OBC_DEGRADED_ON_NORMAL" 5 "OBC_FAULT_SHUTDOWN" 6 "OBC_EMERGENCY_SHUTDOWN" 7 "OBC_DEGRADED_ON_VOLTAGE" 8 "OBC_ON_V2L" 9 "OBC_DEGRADED_ON_V2L" 10 "OBC_STS_SNA" ;
VAL_ 803 POD_GW_PhaseACInput 1 "AC 1 phase input" 3 "AC 3 phase input" ;
VAL_ 805 Steering_Wheel_Convenience_Acces 0 "ON" 1 "OFF" 2 "Invalid" 3 "Invalid" ;
VAL_ 805 Steering_HeatingControlFdbk 0 "Disable" 1 "Enable" 2 "Error" ;
VAL_ 805 BCMFL_STS_SteerAdjust 0 "OFF" 1 "ON" 2 "Reserved" 3 "Signal Invalid" ;
VAL_ 805 SWHC_SterringWheelHeatFaultReaso 0 "Normal" 1 "resistive heater open circuit" 2 "resistive heater short out" 3 "thermistor open circuit" 4 "thermistor short out" 5 "thermistor overheat" ;
VAL_ 805 Steer_ProfileSave_Tips 0 "no tips" 1 "save successfully" 2 "save fail" ;
VAL_ 805 Steer_ColUpDown_Sts 0 "Inactive" 1 "Active" ;
VAL_ 805 Steer_ElecAdjust_SettingSts 0 "No Request" 1 "Save" 2 "Restore memory location" 3 "Moving" ;
VAL_ 815 WCBS_ACC_Available_Flag 0 "Not available" 1 "Available" ;
VAL_ 815 WCBS_ACC_Deceleration_Flag 0 "Not active" 1 "Active" ;
VAL_ 815 WCBS_ACC_Acceleration_Flag 0 "Not active" 1 "Active" ;
VAL_ 815 WCBS_RAEB_Active_Flag 0 "Not Active" 1 "Active" ;
VAL_ 815 WCBS_RAEB_Available_Flag 0 "Not available" 1 "Available" ;
VAL_ 815 WCBS_AEB_Active_Flag 0 "Not active" 1 "Active" ;
VAL_ 815 WCBS_AEB_Available_Flag 0 "Not available" 1 "Available" ;
VAL_ 815 WCBS_ACC_DriverOverride 0 "No override" 1 "Acceleration pedal override" 2 "Brake pedal override" ;
VAL_ 815 WCBS_ACC_WheelTrq_Active 0 "Inactive" 1 "Active" ;
VAL_ 815 WCBS_RAEB_BrakeActuator 0 "Standby" 1 "Prefill progess" 2 "RAEB Braking progess" 3 "Post AEB Brake by 2s" 4 "RAEB Releasing" 5 "No Equipped/support" 6 "Error" 7 "Invalid" ;
VAL_ 843 EVSE_DC_Stt 0 "Init" 1 "EVSE not ready" 2 "EVSE ready" 3 "EVSE shutdown" 4 "EVSE utility interrupt event" 5 "EVSE isolation monitoring active" 6 "EVSE emergency shutdown" 7 "EVSE Malfunction" 8 "Reserved by ISO/IEC for future use" 9 "Reserved by ISO/IEC for future use" 10 "Reserved by ISO/IEC for future use" 11 "Reserved by ISO/IEC for future use" 12 "Reserved by ISO/IEC for future use" ;
VAL_ 843 EVSE_CtrlPilot_STS 0 "A" 1 "B" 2 "C" 3 "D" 4 "E" 5 "F" 6 "Error" ;
VAL_ 843 EVSE_IsolationLvl 0 "Init" 1 "Invalid" 2 "Valid" 3 "Warning" 4 "Fault" 5 "No IMD" ;
VAL_ 843 EVSE_VehChgComm_STAT 0 "None" 1 "Scc_StateMachineStatus_Initialized" 2 "SLAC" 3 "WaitForIP" 4 "SECCDiscoveryProtocol" 5 "TLConnection" 6 "SupportedAppProtocol" 7 "SessionSetup" 8 "ServiceDiscovery" 9 "ServiceDetail" 10 "PaymentServiceSelection" 11 "CertificateInstallation" 12 "CertificateUpdate" 13 "PaymentDetails" 14 "Authorization" 15 "ChargeParameterDiscovery" 16 "PowerDelivery" 17 "MeteringReceipt" 18 "ChargingStatus (AC Charging)" 19 "CableCheck" 20 "PreCharge" 21 "CurrentDemand" 22 "WeldingDetection" 23 "Scc_StateMachineStatus_SessionStop" 24 "StopCommunicationSession" 25 "Finished" 26 "Error_WaitingForRetry" 27 "Error_Stopped" ;
VAL_ 843 EVSE_ResponseCode 0 "Init" 1 "No error" 2 "No error, new session established" 3 "No error, old session joined" 4 "No error, certificate expires soon" 5 "Error" 6 "Sequence error" 7 "Error, service ID invalid" 8 "Error, unknown session" 9 "Error, service selection invalid" 10 "Error, payment selection invalid" 11 "Error, Certificate Expired" 12 "Error, Signature Error" 13 "Error, No Certificate Available" 14 "Error, Cert Chain Error" 15 "Error, Challenge Invalid" 16 "Error, Contract Canceled" 17 "Error, Wrong Charge Parameter" 18 "Error, Power Delivery Not Applied" 19 "Error, Tariff Selection Invalid" 20 "Error, Charging Profile Invalid" 21 "Error, Metering Signature Not Valid" 22 "Error, No Charge Service Selected" 23 "Error, Wrong Energy Transfer Mode" 24 "Error, Contactor Error" 25 "Error, Certificate Not Allowed At This EVSE" 26 "Error, Certificate Revoked" ;
VAL_ 852 CVC_RAEB_Mode 0 "OFF" 1 "ON" 2 "Reserved" 3 "Signal invalid" ;
VAL_ 852 CVC_LA_AudWarning 0 "OFF" 1 "ON" 2 "Reserved" 3 "Signal invalid" ;
VAL_ 852 CVC_BSD_On 0 "OFF" 1 "ON" 2 "Reserved" 3 "Signal invalid" ;
VAL_ 852 CVC_BSD_sens 0 "Early" 1 "Normal" 2 "Late" 3 "Signal invalid" ;
VAL_ 852 CVC_BSD_AudWarning 0 "OFF" 1 "ON" 2 "Reserved" 3 "Signal invalid" ;
VAL_ 852 CVC_RCTA_On 0 "OFF" 1 "ON" 2 "Reserved" 3 "Signal invalid" ;
VAL_ 852 CVC_RCTA_sens 0 "Early" 1 "Normal" 2 "Late" 3 "Signal invalid" ;
VAL_ 852 CVC_PA_On 0 "OFF" 1 "ON" 2 "Reserved" 3 "Signal invalid" ;
VAL_ 852 CVC_AHB_On 0 "OFF" 1 "ON" 2 "Reserved" 3 "Signal invalid" ;
VAL_ 852 CVC_IA_Mode 0 "OFF" 1 "ON" 2 "Reserved" 3 "Signal invalid" ;
VAL_ 852 CVC_TSR_Mode 0 "OFF" 1 "ON" 2 "Reserve" 3 "Signal invalid" ;
VAL_ 852 CVC_DOW_Mode 0 "OFF" 1 "Warning Only" 2 "Warning/Door Lock both" 3 "Signal invalid" ;
VAL_ 852 CVC_AHB_sens 0 "Early" 1 "Normal" 2 "Late" 3 "Signal invalid" ;
VAL_ 852 CVC_FCW_sens 0 "Early" 1 "Normal" 2 "Late" 3 "Signal invalid" ;
VAL_ 852 CVC_LA_Mode 0 "OFF" 1 "Warning only" 2 "Warning & Steer" 3 "Reserved" 4 "Signal Invalid" ;
VAL_ 852 CVC_FCW_Mode 0 "OFF" 1 "ON" 2 "Reserve" 3 "Signal invalid" ;
VAL_ 852 CVC_SET_TSR_AudWarn 0 "OFF" 1 "ON" 2 "Reserved" 3 "Signal invalid" ;
VAL_ 852 CVC_SET_TSR_SLAert 0 "Offset" 1 "Offset + 5" 2 "Offset + 10" 3 "Reserved" ;
VAL_ 852 CVC_LA_sens 0 "Early" 1 "Normal" 2 "Late" 3 "Signal invalid" ;
VAL_ 852 CVC_AEB_Mode 0 "OFF" 1 "ON" 2 "Reserved" 3 "Signal invalid" ;
VAL_ 852 CVC_ESA_ON 0 "OFF" 1 "On" ;
VAL_ 852 CVC_ELKA_ON 0 "OFF" 1 "ON" ;
VAL_ 852 CVC_ALC_ON 0 "OFF" 1 "ON" 2 "Reserved" 3 "Reserved" ;
VAL_ 852 CVC_DashCam_Setting 0 "Disable" 1 "Enable" 2 "Invalid" 3 "Failure" 4 "Reserved" 5 "Reserved" 6 "Reserved" 7 "Reserved" ;
VAL_ 852 CVC_LKA_LDW_Haptic_Mode 0 "OFF" 1 "On" ;
VAL_ 852 CVC_ELK_Haptic_Mode 0 "OFF" 1 "On" ;
VAL_ 852 CVC_TSR_Haptic_Mode 0 "OFF" 1 "On" ;
VAL_ 852 CVC_SLW_Mode_Req 0 "OFF" 1 "On" ;
VAL_ 852 CVC_HWA_Mode 0 "OFF" 1 "On" ;
VAL_ 852 CVC_ISA_ON 0 "OFF" 1 "ON" 2 "Auto" 3 "Reserved" ;
VAL_ 852 CVC_Option_feed 0 "No action" 1 "Perform Driver-Initiated Lane Change" 2 "Perform System-Initiated but Driver-Confirmed Lane Change" ;
VAL_ 852 CVC_ALCA_LaneChange_confir 0 "No confirmation" 1 "OK" 2 "Not OK" ;
VAL_ 852 CVC_FCTB_Mode 0 "OFF" 1 "On" ;
VAL_ 852 CVC_RCTB_Mode 0 "OFF" 1 "On" ;
VAL_ 852 CVC_ACPE_Setting 0 "ACPE Off" 1 "ACPE ON" 2 "Reserved" 3 "Invalid" ;
VAL_ 852 CVC_ACPE_Sens 0 "Normal'" 1 "Plus" 2 "Reserved" 3 "Invalid" ;
VAL_ 852 CVC_SVM_Setting_Guideline 0 "OFF" 1 "ON" 2 "Reserved" 3 "Invalid" ;
VAL_ 852 CVC_SVM_Setting_ObjOverlay 0 "OFF" 1 "ON" 2 "Reserved" 3 "Invalid" ;
VAL_ 852 CVC_SVM_Setting_TrailerGuideline 0 "OFF" 1 "ON" 2 "Reserved" 3 "Invalid" ;
VAL_ 852 CVC_SVM_Setting_MaxDoorOverlay 0 "OFF" 1 "ON" 2 "Reserved" 3 "Invalid" ;
VAL_ 852 CVC_SVM_TransparentRequest 0 "OFF" 1 "ON" 2 "Reserved" 3 "Invalid" ;
VAL_ 852 CVC_SVM_Setting_BlindSpotView 0 "OFF" 1 "ON" 2 "Reserved" 3 "Invalid" ;
VAL_ 852 CVC_NOP_Mode 0 "OFF" 1 "ON" 2 "Reserved" 3 "Invalid" ;
VAL_ 852 CVC_NOP_Type 0 "Init" 1 "HWA" 2 "NOP" 3 "Reserved" ;
VAL_ 852 CVC_ALC_Recommend 0 "OFF" 1 "On" ;
VAL_ 852 CVC_TLD_On 0 "Off" 1 "On" 2 "Reserved" 3 "Signal invalid" ;
